VERSION ""

NS_ :

BS_:

BU_: Dummy_FO EOCM2cp_K2_FO EOCM2cp_K1_FO EOCM2cp_IMX6_FO CECM_R1_FO CMMb_FO CMMa_FO RSRR_FO LRR_FO CIPM_FO IMU2_FO IMU1_FO CGM3b_FO
VAL_TABLE_ vt_BooleanValues 1 "true" 0 "false" ;
VAL_TABLE_ StrgColCommsFlt 2 "Disabled Communications DTC" 1 "No Communications Fault" 0 "Communications Fault" ;
VAL_TABLE_ CPMAPINFO4 1 "Hardware Or Software Error" 0 "No Hardware Or Software Error" ;
VAL_TABLE_ InterLghtStat 1 "Interior Lights On" 0 "Interior Light Off" ;
VAL_TABLE_ ObstacleType 6 "NO_OBJECT" 5 "OBJ_GUARDRAIL" 4 "OBJ_TUNNEL " 3 "OBJ_TRAFFIC_SIGN" 2 "OBJ_VEHICLE" 1 "OBJ_BRIDGE " 0 "OBJ_UNKNOWN" ;
VAL_TABLE_ VpathMode 2 "Mid Hi Spped" 1 "Low Speed" 0 "Disabled" ;
VAL_TABLE_ LaneChngStatus 2 "Lane Change Right" 1 "Lane Change Left" 0 "Idle" ;
VAL_TABLE_ TravelDirection 3 "Other (excessive side slip)" 2 "reverse / stopped in rvrs gear" 1 "Forward / stopped in frwd gear" 0 "Unknown" ;
VAL_TABLE_ ModeCommand 5 "Sensing with Reduced Power" 4 "Undefined" 3 "Radio Silent" 2 "Sensing" 1 "Not Sensing" 0 "Undefined" ;
VAL_TABLE_ LaneSnsLLnPosValid 1 "Invalid" 0 "Valid" ;
VAL_TABLE_ LnSnsRLnPosValid 0 "Valid" 1 "Invalid" ;
VAL_TABLE_ Elevation 3 "Low " 2 "mid (reserved)" 1 "high " 0 "Unknown" ;
VAL_TABLE_ ModeCommandFdbk 5 "Sensing with reduced power" 4 "Undefined" 3 "Radio Silent" 2 "Sensing" 1 "Not Sensing" 0 "Undefined" ;
VAL_TABLE_ RoadTypeInfo 5 "Constiction Zone Exit" 4 "Construction Zone Entry" 3 "Highway" 2 "Secondary Road" 1 "City" 0 "Unknown" ;
VAL_TABLE_ ObjectLossInfo 2 "elevation conditions" 1 "tight curve" 0 "not lost" ;
VAL_TABLE_ MeasurementStatus 3 "Measured this cycle" 2 "Latent track not detctd this cyc" 1 "New Object" 0 "No Object" ;
VAL_TABLE_ Confidence 3 "confident" 2 "speculative" 1 "highly speculative" 0 "invalid" ;
VAL_TABLE_ DynamicProp 4 "Moving in opposite direction" 3 "Moving in same direction as host" 2 "Has moved but currently stopped" 1 "Has never moved" 0 "Unknown" ;
VAL_TABLE_ CRL_Cnfdnc 7 "Reserved4" 6 "Reserved3" 5 "Reserved2" 4 "Reserved1" 3 "Best" 2 "Marking Present" 1 "Weak Marking" 0 "No Lane" ;
VAL_TABLE_ CLL_Cnfdnc 7 "Reserved4" 6 "Reserved3" 5 "Reserved2" 4 "Reserved1" 3 "Best" 2 "Marking Present" 1 "Weak Marking" 0 "No Lane" ;
VAL_TABLE_ DrvWndPosSt 6 "Fully Opened" 5 "Open More Than C" 4 "Position C" 3 "Posistion B" 2 "Posistion A" 1 "Open Less Than A" 0 "Fully Closed" ;
VAL_TABLE_ OtsdAmbtLtLvlStat 2 "Day" 1 "Night" 0 "Unknown" ;
VAL_TABLE_ DTCI_DTCFaultType 3 "Type C" 2 "Type B" 1 "Type A" 0 "Not Supported" ;
VAL_TABLE_ VD_CoPilotSysFltStat 5 "Copilot System Failure" 4 "Partial Function Fault Detected" 3 "Redundancy Fault Detected" 2 "Environmental Interference" 1 "Operational" 0 "Unknown" ;
VAL_TABLE_ StrgAngTrqBsdEstSrfcMuConf 2 "Indeterminate" 1 "Use Data" 0 "Do Not Use Data" ;
VAL_TABLE_ SysPwrMd 3 "Crank Request" 2 "Run" 1 "Accessory" 0 "Off" ;
VAL_TABLE_ ValidityStates 1 "Invalid" 0 "Valid" ;

BO_ 1923 DTC_Triggered_783_FO: 7 RSRR_FO
 SG_ DTCI_WrnIndRqdSt_783 : 47|1@0+ (1,0) [0|1] ""  CGM3b_FO
 SG_ DTCI_TstNPsdPwrUpSt_783 : 45|1@0+ (1,0) [0|1] ""  CGM3b_FO
 SG_ DTCI_TstNPsdCdClrdSt_783 : 42|1@0+ (1,0) [0|1] ""  CGM3b_FO
 SG_ DTCI_TstFldPwrUpSt_783 : 46|1@0+ (1,0) [0|1] ""  CGM3b_FO
 SG_ DTCI_TstFldCdClrdStat_783 : 43|1@0+ (1,0) [0|1] ""  CGM3b_FO
 SG_ DTCI_HistStat_783 : 44|1@0+ (1,0) [0|1] ""  CGM3b_FO
 SG_ DTCI_DTCTriggered_783 : 0|1@0+ (1,0) [0|1] ""  CGM3b_FO
 SG_ DTCI_DTCSource_783 : 15|8@0+ (1,0) [0|255] ""  CGM3b_FO
 SG_ DTCI_DTCNumber_783 : 23|16@0+ (1,0) [0|65535] ""  CGM3b_FO
 SG_ DTCI_DTCFaultType_783 : 55|8@0+ (1,0) [0|255] ""  CGM3b_FO
 SG_ DTCI_DTCFailType_783 : 39|8@0+ (1,0) [0|255] ""  CGM3b_FO
 SG_ DTCI_CurrentStatus_783 : 41|1@0+ (1,0) [0|1] ""  CGM3b_FO
 SG_ DTCI_CodeSupported_783 : 40|1@0+ (1,0) [0|1] ""  CGM3b_FO
 SG_ DTCIUnused7_783 : 1|1@0+ (1,0) [0|1] ""  CGM3b_FO
 SG_ DTCIUnused6_783 : 2|1@0+ (1,0) [0|1] ""  CGM3b_FO
 SG_ DTCIUnused5_783 : 3|1@0+ (1,0) [0|1] ""  CGM3b_FO
 SG_ DTCIUnused4_783 : 4|1@0+ (1,0) [0|1] ""  CGM3b_FO
 SG_ DTCIUnused3_783 : 5|1@0+ (1,0) [0|1] ""  CGM3b_FO
 SG_ DTCIUnused2_783 : 6|1@0+ (1,0) [0|1] ""  CGM3b_FO
 SG_ DTCIUnused1_783 : 7|1@0+ (1,0) [0|1] ""  CGM3b_FO

BO_ 1920 DTC_Triggered_780_FO: 7 LRR_FO
 SG_ DTCI_CurrentStatus_780 : 41|1@0+ (1,0) [0|1] ""  CGM3b_FO
 SG_ DTCI_WrnIndRqdSt_780 : 47|1@0+ (1,0) [0|1] ""  CGM3b_FO
 SG_ DTCIUnused7_780 : 1|1@0+ (1,0) [0|1] ""  CGM3b_FO
 SG_ DTCIUnused6_780 : 2|1@0+ (1,0) [0|1] ""  CGM3b_FO
 SG_ DTCIUnused5_780 : 3|1@0+ (1,0) [0|1] ""  CGM3b_FO
 SG_ DTCIUnused4_780 : 4|1@0+ (1,0) [0|1] ""  CGM3b_FO
 SG_ DTCIUnused3_780 : 5|1@0+ (1,0) [0|1] ""  CGM3b_FO
 SG_ DTCIUnused2_780 : 6|1@0+ (1,0) [0|1] ""  CGM3b_FO
 SG_ DTCIUnused1_780 : 7|1@0+ (1,0) [0|1] ""  CGM3b_FO
 SG_ DTCI_TstNPsdPwrUpSt_780 : 45|1@0+ (1,0) [0|1] ""  CGM3b_FO
 SG_ DTCI_TstNPsdCdClrdSt_780 : 42|1@0+ (1,0) [0|1] ""  CGM3b_FO
 SG_ DTCI_TstFldPwrUpSt_780 : 46|1@0+ (1,0) [0|1] ""  CGM3b_FO
 SG_ DTCI_TstFldCdClrdStat_780 : 43|1@0+ (1,0) [0|1] ""  CGM3b_FO
 SG_ DTCI_HistStat_780 : 44|1@0+ (1,0) [0|1] ""  CGM3b_FO
 SG_ DTCI_DTCTriggered_780 : 0|1@0+ (1,0) [0|1] ""  CGM3b_FO
 SG_ DTCI_DTCSource_780 : 15|8@0+ (1,0) [0|255] ""  CGM3b_FO
 SG_ DTCI_DTCNumber_780 : 23|16@0+ (1,0) [0|65535] ""  CGM3b_FO
 SG_ DTCI_DTCFaultType_780 : 55|8@0+ (1,0) [0|255] ""  CGM3b_FO
 SG_ DTCI_DTCFailType_780 : 39|8@0+ (1,0) [0|255] ""  CGM3b_FO
 SG_ DTCI_CodeSupported_780 : 40|1@0+ (1,0) [0|1] ""  CGM3b_FO

BO_ 1789 AL_Test_Tool_Req_RSRR: 8 Dummy_FO
 SG_ RSRREngCmdDta : 7|64@0+ (1,0) [0|1.84467440737096E+019] ""  CGM3b_FO,RSRR_FO

BO_ 1786 AL_Test_Tool_Rsp_RSRR: 8 RSRR_FO
 SG_ RSRREngRspDta : 7|64@0+ (1,0) [0|1.84467440737096E+019] ""  CGM3b_FO

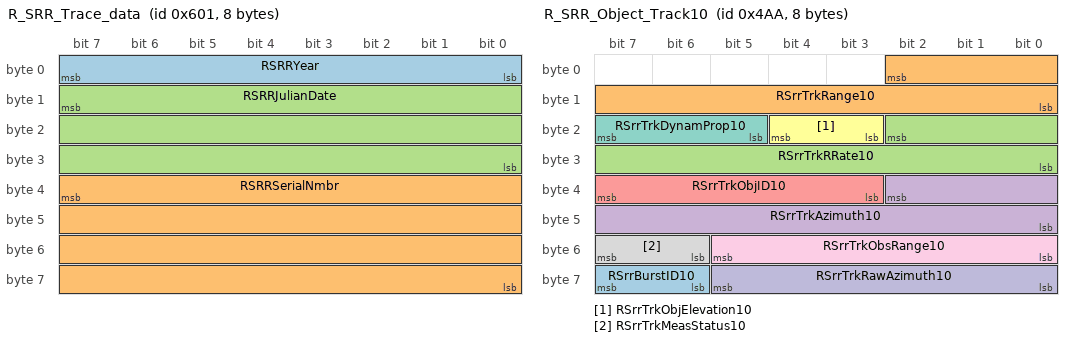
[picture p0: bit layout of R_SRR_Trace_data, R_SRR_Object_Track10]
BO_ 1537 R_SRR_Trace_data: 8 RSRR_FO
 SG_ RSRRYear : 7|8@0+ (1,0) [0|0] ""  CGM3b_FO
 SG_ RSRRSerialNmbr : 39|32@0+ (1,0) [0|0] ""  CGM3b_FO
 SG_ RSRRJulianDate : 15|24@0+ (1,0) [0|0] ""  CGM3b_FO

BO_ 1194 R_SRR_Object_Track10: 8 RSRR_FO
 SG_ RSrrBurstID10 : 63|2@0+ (1,0) [0|3] ""  CGM3b_FO
 SG_ RSrrTrkRange10 : 2|11@0+ (0.02,0) [0|40.94] "m"  CGM3b_FO
 SG_ RSrrTrkRRate10 : 18|11@0- (0.125,0) [-128|127.875] "m/s"  CGM3b_FO
 SG_ RSrrTrkAzimuth10 : 34|11@0- (0.125,0) [-128|127.875] "deg"  CGM3b_FO
 SG_ RSrrTrkObjID10 : 39|5@0+ (1,0) [0|31] ""  CGM3b_FO
 SG_ RSrrTrkObjElevation10 : 20|2@0+ (1,0) [0|3] ""  CGM3b_FO
 SG_ RSrrTrkDynamProp10 : 23|3@0+ (1,0) [0|7] ""  CGM3b_FO
 SG_ RSrrTrkMeasStatus10 : 55|2@0+ (1,0) [0|3] ""  CGM3b_FO
 SG_ RSrrTrkObsRange10 : 53|6@0- (0.02,0) [-0.64|0.62] "m"  CGM3b_FO
 SG_ RSrrTrkRawAzimuth10 : 61|6@0- (1,0) [-32|31] "deg"  CGM3b_FO

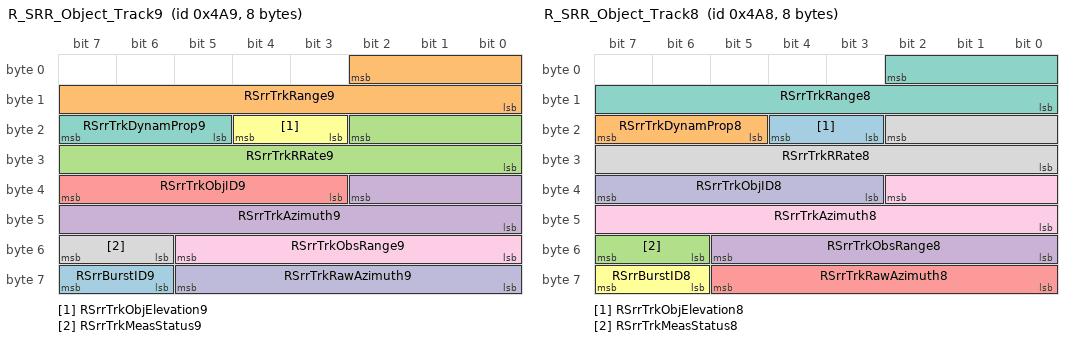
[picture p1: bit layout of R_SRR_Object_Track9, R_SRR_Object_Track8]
BO_ 1193 R_SRR_Object_Track9: 8 RSRR_FO
 SG_ RSrrBurstID9 : 63|2@0+ (1,0) [0|3] ""  CGM3b_FO
 SG_ RSrrTrkRange9 : 2|11@0+ (0.02,0) [0|40.94] "m"  CGM3b_FO
 SG_ RSrrTrkRRate9 : 18|11@0- (0.125,0) [-128|127.875] "m/s"  CGM3b_FO
 SG_ RSrrTrkAzimuth9 : 34|11@0- (0.125,0) [-128|127.875] "deg"  CGM3b_FO
 SG_ RSrrTrkObjID9 : 39|5@0+ (1,0) [0|31] ""  CGM3b_FO
 SG_ RSrrTrkObjElevation9 : 20|2@0+ (1,0) [0|3] ""  CGM3b_FO
 SG_ RSrrTrkDynamProp9 : 23|3@0+ (1,0) [0|7] ""  CGM3b_FO
 SG_ RSrrTrkMeasStatus9 : 55|2@0+ (1,0) [0|3] ""  CGM3b_FO
 SG_ RSrrTrkObsRange9 : 53|6@0- (0.02,0) [-0.64|0.62] "m"  CGM3b_FO
 SG_ RSrrTrkRawAzimuth9 : 61|6@0- (1,0) [-32|31] "deg"  CGM3b_FO

BO_ 1192 R_SRR_Object_Track8: 8 RSRR_FO
 SG_ RSrrTrkObjElevation8 : 20|2@0+ (1,0) [0|3] ""  CGM3b_FO
 SG_ RSrrTrkDynamProp8 : 23|3@0+ (1,0) [0|7] ""  CGM3b_FO
 SG_ RSrrTrkMeasStatus8 : 55|2@0+ (1,0) [0|3] ""  CGM3b_FO
 SG_ RSrrTrkObsRange8 : 53|6@0- (0.02,0) [-0.64|0.62] "m"  CGM3b_FO
 SG_ RSrrTrkRawAzimuth8 : 61|6@0- (1,0) [-32|31] "deg"  CGM3b_FO
 SG_ RSrrBurstID8 : 63|2@0+ (1,0) [0|3] ""  CGM3b_FO
 SG_ RSrrTrkRange8 : 2|11@0+ (0.02,0) [0|40.94] "m"  CGM3b_FO
 SG_ RSrrTrkRRate8 : 18|11@0- (0.125,0) [-128|127.875] "m/s"  CGM3b_FO
 SG_ RSrrTrkAzimuth8 : 34|11@0- (0.125,0) [-128|127.875] "deg"  CGM3b_FO
 SG_ RSrrTrkObjID8 : 39|5@0+ (1,0) [0|31] ""  CGM3b_FO

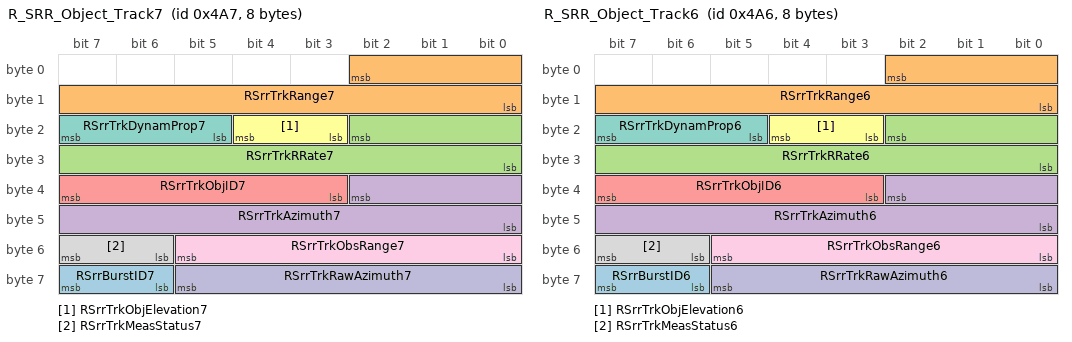
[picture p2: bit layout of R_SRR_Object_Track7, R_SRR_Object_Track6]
BO_ 1191 R_SRR_Object_Track7: 8 RSRR_FO
 SG_ RSrrBurstID7 : 63|2@0+ (1,0) [0|3] ""  CGM3b_FO
 SG_ RSrrTrkRange7 : 2|11@0+ (0.02,0) [0|40.94] "m"  CGM3b_FO
 SG_ RSrrTrkRRate7 : 18|11@0- (0.125,0) [-128|127.875] "m/s"  CGM3b_FO
 SG_ RSrrTrkAzimuth7 : 34|11@0- (0.125,0) [-128|127.875] "deg"  CGM3b_FO
 SG_ RSrrTrkObjID7 : 39|5@0+ (1,0) [0|31] ""  CGM3b_FO
 SG_ RSrrTrkObjElevation7 : 20|2@0+ (1,0) [0|3] ""  CGM3b_FO
 SG_ RSrrTrkDynamProp7 : 23|3@0+ (1,0) [0|7] ""  CGM3b_FO
 SG_ RSrrTrkMeasStatus7 : 55|2@0+ (1,0) [0|3] ""  CGM3b_FO
 SG_ RSrrTrkObsRange7 : 53|6@0- (0.02,0) [-0.64|0.62] "m"  CGM3b_FO
 SG_ RSrrTrkRawAzimuth7 : 61|6@0- (1,0) [-32|31] "deg"  CGM3b_FO

BO_ 1190 R_SRR_Object_Track6: 8 RSRR_FO
 SG_ RSrrBurstID6 : 63|2@0+ (1,0) [0|3] ""  CGM3b_FO
 SG_ RSrrTrkRange6 : 2|11@0+ (0.02,0) [0|40.94] "m"  CGM3b_FO
 SG_ RSrrTrkRRate6 : 18|11@0- (0.125,0) [-128|127.875] "m/s"  CGM3b_FO
 SG_ RSrrTrkAzimuth6 : 34|11@0- (0.125,0) [-128|127.875] "deg"  CGM3b_FO
 SG_ RSrrTrkObjID6 : 39|5@0+ (1,0) [0|31] ""  CGM3b_FO
 SG_ RSrrTrkObjElevation6 : 20|2@0+ (1,0) [0|3] ""  CGM3b_FO
 SG_ RSrrTrkDynamProp6 : 23|3@0+ (1,0) [0|7] ""  CGM3b_FO
 SG_ RSrrTrkMeasStatus6 : 55|2@0+ (1,0) [0|3] ""  CGM3b_FO
 SG_ RSrrTrkObsRange6 : 53|6@0- (0.02,0) [-0.64|0.62] "m"  CGM3b_FO
 SG_ RSrrTrkRawAzimuth6 : 61|6@0- (1,0) [-32|31] "deg"  CGM3b_FO

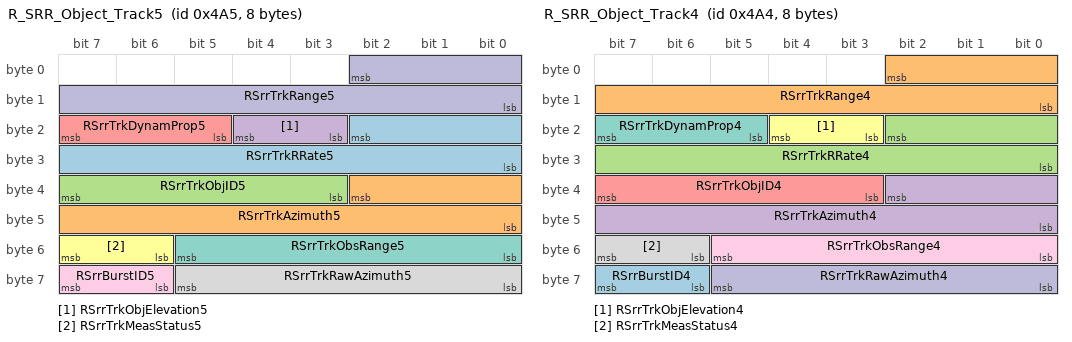
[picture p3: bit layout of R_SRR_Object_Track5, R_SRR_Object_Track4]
BO_ 1189 R_SRR_Object_Track5: 8 RSRR_FO
 SG_ RSrrTrkRRate5 : 18|11@0- (0.125,0) [-128|127.875] "m/s"  CGM3b_FO
 SG_ RSrrTrkAzimuth5 : 34|11@0- (0.125,0) [-128|127.875] "deg"  CGM3b_FO
 SG_ RSrrTrkObjID5 : 39|5@0+ (1,0) [0|31] ""  CGM3b_FO
 SG_ RSrrTrkObjElevation5 : 20|2@0+ (1,0) [0|3] ""  CGM3b_FO
 SG_ RSrrTrkDynamProp5 : 23|3@0+ (1,0) [0|7] ""  CGM3b_FO
 SG_ RSrrTrkMeasStatus5 : 55|2@0+ (1,0) [0|3] ""  CGM3b_FO
 SG_ RSrrTrkObsRange5 : 53|6@0- (0.02,0) [-0.64|0.62] "m"  CGM3b_FO
 SG_ RSrrTrkRawAzimuth5 : 61|6@0- (1,0) [-32|31] "deg"  CGM3b_FO
 SG_ RSrrBurstID5 : 63|2@0+ (1,0) [0|3] ""  CGM3b_FO
 SG_ RSrrTrkRange5 : 2|11@0+ (0.02,0) [0|40.94] "m"  CGM3b_FO

BO_ 1188 R_SRR_Object_Track4: 8 RSRR_FO
 SG_ RSrrBurstID4 : 63|2@0+ (1,0) [0|3] ""  CGM3b_FO
 SG_ RSrrTrkRange4 : 2|11@0+ (0.02,0) [0|40.94] "m"  CGM3b_FO
 SG_ RSrrTrkRRate4 : 18|11@0- (0.125,0) [-128|127.875] "m/s"  CGM3b_FO
 SG_ RSrrTrkAzimuth4 : 34|11@0- (0.125,0) [-128|127.875] "deg"  CGM3b_FO
 SG_ RSrrTrkObjID4 : 39|5@0+ (1,0) [0|31] ""  CGM3b_FO
 SG_ RSrrTrkObjElevation4 : 20|2@0+ (1,0) [0|3] ""  CGM3b_FO
 SG_ RSrrTrkDynamProp4 : 23|3@0+ (1,0) [0|7] ""  CGM3b_FO
 SG_ RSrrTrkMeasStatus4 : 55|2@0+ (1,0) [0|3] ""  CGM3b_FO
 SG_ RSrrTrkObsRange4 : 53|6@0- (0.02,0) [-0.64|0.62] "m"  CGM3b_FO
 SG_ RSrrTrkRawAzimuth4 : 61|6@0- (1,0) [-32|31] "deg"  CGM3b_FO

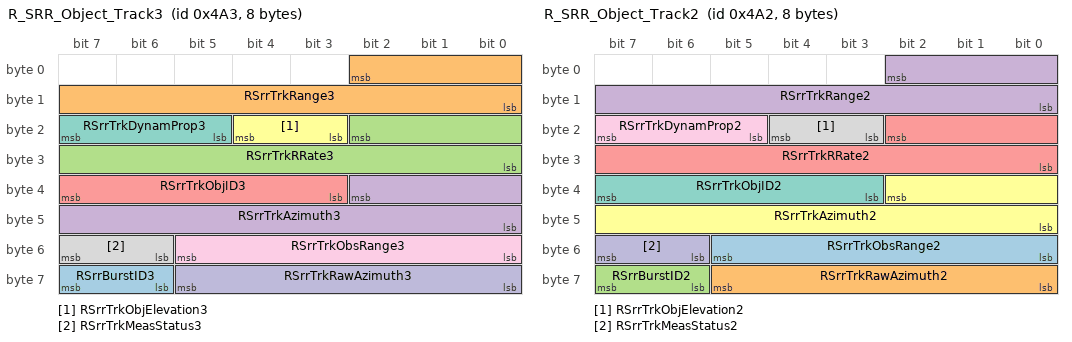
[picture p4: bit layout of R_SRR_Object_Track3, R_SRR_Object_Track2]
BO_ 1187 R_SRR_Object_Track3: 8 RSRR_FO
 SG_ RSrrBurstID3 : 63|2@0+ (1,0) [0|3] ""  CGM3b_FO
 SG_ RSrrTrkRange3 : 2|11@0+ (0.02,0) [0|40.94] "m"  CGM3b_FO
 SG_ RSrrTrkRRate3 : 18|11@0- (0.125,0) [-128|127.875] "m/s"  CGM3b_FO
 SG_ RSrrTrkAzimuth3 : 34|11@0- (0.125,0) [-128|127.875] "deg"  CGM3b_FO
 SG_ RSrrTrkObjID3 : 39|5@0+ (1,0) [0|31] ""  CGM3b_FO
 SG_ RSrrTrkObjElevation3 : 20|2@0+ (1,0) [0|3] ""  CGM3b_FO
 SG_ RSrrTrkDynamProp3 : 23|3@0+ (1,0) [0|7] ""  CGM3b_FO
 SG_ RSrrTrkMeasStatus3 : 55|2@0+ (1,0) [0|3] ""  CGM3b_FO
 SG_ RSrrTrkObsRange3 : 53|6@0- (0.02,0) [-0.64|0.62] "m"  CGM3b_FO
 SG_ RSrrTrkRawAzimuth3 : 61|6@0- (1,0) [-32|31] "deg"  CGM3b_FO

BO_ 1186 R_SRR_Object_Track2: 8 RSRR_FO
 SG_ RSrrTrkObsRange2 : 53|6@0- (0.02,0) [-0.64|0.62] "m"  CGM3b_FO
 SG_ RSrrTrkRawAzimuth2 : 61|6@0- (1,0) [-32|31] "deg"  CGM3b_FO
 SG_ RSrrBurstID2 : 63|2@0+ (1,0) [0|3] ""  CGM3b_FO
 SG_ RSrrTrkRange2 : 2|11@0+ (0.02,0) [0|40.94] "m"  CGM3b_FO
 SG_ RSrrTrkRRate2 : 18|11@0- (0.125,0) [-128|127.875] "m/s"  CGM3b_FO
 SG_ RSrrTrkAzimuth2 : 34|11@0- (0.125,0) [-128|127.875] "deg"  CGM3b_FO
 SG_ RSrrTrkObjID2 : 39|5@0+ (1,0) [0|31] ""  CGM3b_FO
 SG_ RSrrTrkObjElevation2 : 20|2@0+ (1,0) [0|3] ""  CGM3b_FO
 SG_ RSrrTrkDynamProp2 : 23|3@0+ (1,0) [0|7] ""  CGM3b_FO
 SG_ RSrrTrkMeasStatus2 : 55|2@0+ (1,0) [0|3] ""  CGM3b_FO

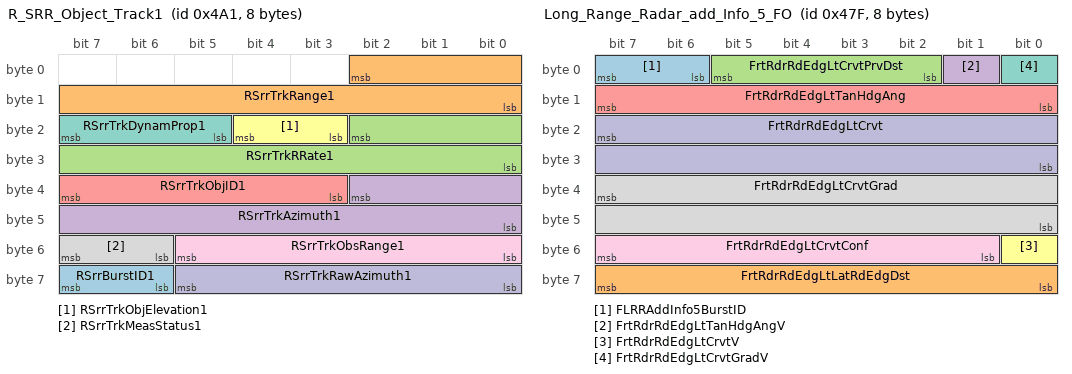
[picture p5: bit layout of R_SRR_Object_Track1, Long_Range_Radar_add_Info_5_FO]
BO_ 1185 R_SRR_Object_Track1: 8 RSRR_FO
 SG_ RSrrBurstID1 : 63|2@0+ (1,0) [0|3] ""  CGM3b_FO
 SG_ RSrrTrkRange1 : 2|11@0+ (0.02,0) [0|40.94] "m"  CGM3b_FO
 SG_ RSrrTrkRRate1 : 18|11@0- (0.125,0) [-128|127.875] "m/s"  CGM3b_FO
 SG_ RSrrTrkAzimuth1 : 34|11@0- (0.125,0) [-128|127.875] "deg"  CGM3b_FO
 SG_ RSrrTrkObjID1 : 39|5@0+ (1,0) [0|31] ""  CGM3b_FO
 SG_ RSrrTrkObjElevation1 : 20|2@0+ (1,0) [0|3] ""  CGM3b_FO
 SG_ RSrrTrkDynamProp1 : 23|3@0+ (1,0) [0|7] ""  CGM3b_FO
 SG_ RSrrTrkMeasStatus1 : 55|2@0+ (1,0) [0|3] ""  CGM3b_FO
 SG_ RSrrTrkObsRange1 : 53|6@0- (0.02,0) [-0.64|0.62] "m"  CGM3b_FO
 SG_ RSrrTrkRawAzimuth1 : 61|6@0- (1,0) [-32|31] "deg"  CGM3b_FO

BO_ 1184 R_SRR_Object_Header: 8 RSRR_FO
 SG_ RSRRSnstvFltPrsntInt : 24|1@0+ (1,0) [0|1] ""  CGM3b_FO
 SG_ RSRRPlntAlgnInProc : 37|1@0+ (1,0) [0|1] ""  CGM3b_FO
 SG_ RSRRMsalgnYawRt : 47|1@0+ (1,0) [0|1] ""  CGM3b_FO
 SG_ RSRRMsalgnYawLt : 46|1@0+ (1,0) [0|1] ""  CGM3b_FO
 SG_ RSRRMsalgnRllRt : 35|1@0+ (1,0) [0|1] ""  CGM3b_FO
 SG_ RSRRMsalgnRllLt : 34|1@0+ (1,0) [0|1] ""  CGM3b_FO
 SG_ RSRRMsalgnPtchUp : 32|1@0+ (1,0) [0|1] ""  CGM3b_FO
 SG_ RSRRMsalgnPtchDn : 33|1@0+ (1,0) [0|1] ""  CGM3b_FO
 SG_ RSRRInitDiagCmplt : 40|1@0+ (1,0) [0|1] ""  CGM3b_FO
 SG_ RSRRHWFltPrsntInt : 25|1@0+ (1,0) [0|1] ""  CGM3b_FO
 SG_ RSRRExtIntrfrnc : 36|1@0+ (1,0) [0|1] ""  CGM3b_FO
 SG_ RSRRDiagSpare : 30|1@0+ (1,0) [0|1] ""  CGM3b_FO
 SG_ RSRRCANSgnlSpvFld : 29|1@0+ (1,0) [0|1] ""  CGM3b_FO
 SG_ RSRRCANRxErr : 28|1@0+ (1,0) [0|1] ""  CGM3b_FO
 SG_ RSRRCANIDAddrsUnsbl : 27|1@0+ (1,0) [0|1] ""  CGM3b_FO
 SG_ RSRRAntTngFltPrsnt : 26|1@0+ (1,0) [0|1] ""  CGM3b_FO
 SG_ RSRRAmbTmpOutRngLw : 42|1@0+ (1,0) [0|1] ""  CGM3b_FO
 SG_ RSRRAmbTmpOutRngHi : 41|1@0+ (1,0) [0|1] ""  CGM3b_FO
 SG_ RSRRAlgnFltPrsnt : 39|1@0+ (1,0) [0|1] ""  CGM3b_FO
 SG_ RSRRVltgOutRngLo : 44|1@0+ (1,0) [0|1] ""  CGM3b_FO
 SG_ RSRRVltgOutRngHi : 43|1@0+ (1,0) [0|1] ""  CGM3b_FO
 SG_ RSRRSvcAlgnInPrcs : 38|1@0+ (1,0) [0|1] ""  CGM3b_FO
 SG_ RSRRSnsrBlckd : 45|1@0+ (1,0) [0|1] ""  CGM3b_FO
 SG_ RSRRNumValidTargets : 14|4@0+ (1,0) [0|15] ""  CGM3b_FO
 SG_ RSrrRollingCnt : 1|2@0+ (1,0) [0|3] ""  CGM3b_FO
 SG_ RSRRModeCmdFdbk : 4|3@0+ (1,0) [0|7] ""  CGM3b_FO
 SG_ RSrrTimeStampV : 15|1@0+ (1,0) [0|1] ""  CGM3b_FO
 SG_ RSrrTimeStamp : 10|11@0+ (1,0) [0|2047] "ms"  CGM3b_FO
 SG_ RSrrBurstChecksum : 55|16@0+ (1,0) [0|65535] ""  CGM3b_FO

BO_ 1151 Long_Range_Radar_add_Info_5_FO: 8 LRR_FO
 SG_ FLRRAddInfo5BurstID : 7|2@0+ (1,0) [0|3] ""  CGM3b_FO
 SG_ FrtRdrRdEdgLtLatRdEdgDst : 63|8@0- (0.1,0) [-12.8|12.7] "m/m"  CGM3b_FO
 SG_ FrtRdrRdEdgLtCrvtPrvDst : 5|4@0+ (10,0) [0|150] ""  CGM3b_FO
 SG_ FrtRdrRdEdgLtTanHdgAngV : 1|1@0+ (1,0) [0|1] ""  CGM3b_FO
 SG_ FrtRdrRdEdgLtTanHdgAng : 15|8@0- (0.002,0) [-0.256|0.254] "m/m"  CGM3b_FO
 SG_ FrtRdrRdEdgLtCrvtV : 48|1@0+ (1,0) [0|1] ""  CGM3b_FO
 SG_ FrtRdrRdEdgLtCrvtGradV : 0|1@0+ (1,0) [0|1] ""  CGM3b_FO
 SG_ FrtRdrRdEdgLtCrvtGrad : 39|16@0- (5.96E-008,0) [-0.0019529728|0.0019529132] "1/(m*sec)"  CGM3b_FO
 SG_ FrtRdrRdEdgLtCrvtConf : 55|7@0+ (0.7874016,0) [0|100.0000032] "%"  CGM3b_FO
 SG_ FrtRdrRdEdgLtCrvt : 23|16@0- (9.53E-007,0) [-0.031227904|0.031226951] "1/m"  CGM3b_FO

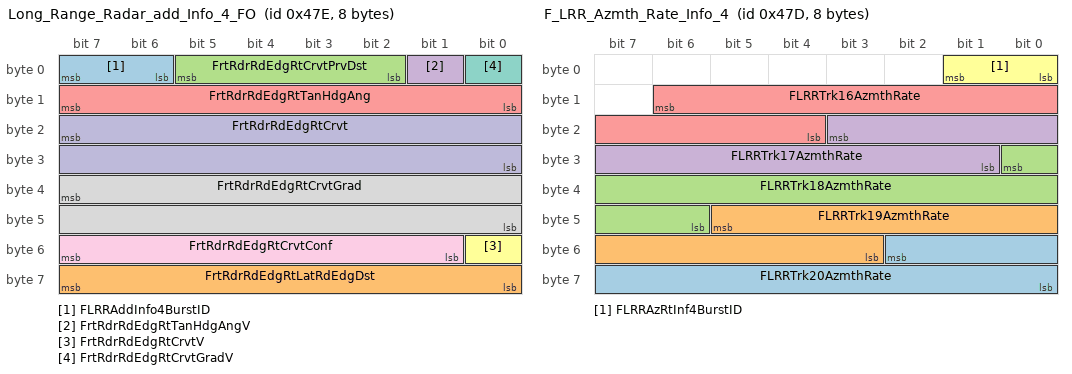
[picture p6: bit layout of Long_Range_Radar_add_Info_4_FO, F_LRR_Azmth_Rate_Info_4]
BO_ 1150 Long_Range_Radar_add_Info_4_FO: 8 LRR_FO
 SG_ FLRRAddInfo4BurstID : 7|2@0+ (1,0) [0|3] ""  CGM3b_FO
 SG_ FrtRdrRdEdgRtLatRdEdgDst : 63|8@0- (0.1,0) [-12.8|12.7] "m/m"  CGM3b_FO
 SG_ FrtRdrRdEdgRtCrvtPrvDst : 5|4@0+ (10,0) [0|150] ""  CGM3b_FO
 SG_ FrtRdrRdEdgRtTanHdgAngV : 1|1@0+ (1,0) [0|1] ""  CGM3b_FO
 SG_ FrtRdrRdEdgRtTanHdgAng : 15|8@0- (0.002,0) [-0.256|0.254] "m/m"  CGM3b_FO
 SG_ FrtRdrRdEdgRtCrvtV : 48|1@0+ (1,0) [0|1] ""  CGM3b_FO
 SG_ FrtRdrRdEdgRtCrvtGradV : 0|1@0+ (1,0) [0|1] ""  CGM3b_FO
 SG_ FrtRdrRdEdgRtCrvtGrad : 39|16@0- (5.96E-008,0) [-0.0019529728|0.0019529132] "1/(m*sec)"  CGM3b_FO
 SG_ FrtRdrRdEdgRtCrvtConf : 55|7@0+ (0.7874016,0) [0|100.0000032] "%"  CGM3b_FO
 SG_ FrtRdrRdEdgRtCrvt : 23|16@0- (9.53E-007,0) [-0.031227904|0.031226951] "1/m"  CGM3b_FO

BO_ 1149 F_LRR_Azmth_Rate_Info_4: 8 LRR_FO
 SG_ FLRRTrk20AzmthRate : 50|11@0- (0.125,0) [-128|127.875] "deg/s"  CGM3b_FO
 SG_ FLRRTrk19AzmthRate : 45|11@0- (0.125,0) [-128|127.875] "deg/s"  CGM3b_FO
 SG_ FLRRTrk18AzmthRate : 24|11@0- (0.125,0) [-128|127.875] "deg/s"  CGM3b_FO
 SG_ FLRRTrk17AzmthRate : 19|11@0- (0.125,0) [-128|127.875] "deg/s"  CGM3b_FO
 SG_ FLRRTrk16AzmthRate : 14|11@0- (0.125,0) [-128|127.875] "deg/s"  CGM3b_FO
 SG_ FLRRAzRtInf4BurstID : 1|2@0+ (1,0) [0|3] ""  CGM3b_FO

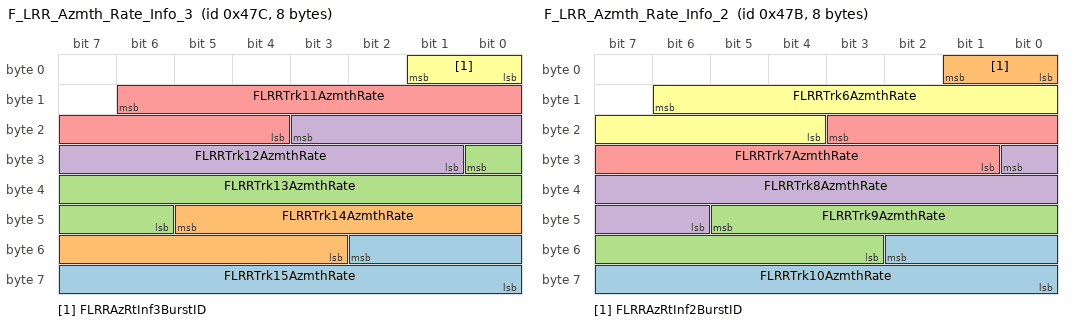
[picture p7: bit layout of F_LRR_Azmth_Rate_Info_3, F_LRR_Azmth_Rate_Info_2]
BO_ 1148 F_LRR_Azmth_Rate_Info_3: 8 LRR_FO
 SG_ FLRRTrk15AzmthRate : 50|11@0- (0.125,0) [-128|127.875] "deg/s"  CGM3b_FO
 SG_ FLRRTrk14AzmthRate : 45|11@0- (0.125,0) [-128|127.875] "deg/s"  CGM3b_FO
 SG_ FLRRTrk13AzmthRate : 24|11@0- (0.125,0) [-128|127.875] "deg/s"  CGM3b_FO
 SG_ FLRRTrk12AzmthRate : 19|11@0- (0.125,0) [-128|127.875] "deg/s"  CGM3b_FO
 SG_ FLRRTrk11AzmthRate : 14|11@0- (0.125,0) [-128|127.875] "deg/s"  CGM3b_FO
 SG_ FLRRAzRtInf3BurstID : 1|2@0+ (1,0) [0|3] ""  CGM3b_FO

BO_ 1147 F_LRR_Azmth_Rate_Info_2: 8 LRR_FO
 SG_ FLRRTrk10AzmthRate : 50|11@0- (0.125,0) [-128|127.875] "deg/s"  CGM3b_FO
 SG_ FLRRAzRtInf2BurstID : 1|2@0+ (1,0) [0|3] ""  CGM3b_FO
 SG_ FLRRTrk9AzmthRate : 45|11@0- (0.125,0) [-128|127.875] "deg/s"  CGM3b_FO
 SG_ FLRRTrk8AzmthRate : 24|11@0- (0.125,0) [-128|127.875] "deg/s"  CGM3b_FO
 SG_ FLRRTrk7AzmthRate : 19|11@0- (0.125,0) [-128|127.875] "deg/s"  CGM3b_FO
 SG_ FLRRTrk6AzmthRate : 14|11@0- (0.125,0) [-128|127.875] "deg/s"  CGM3b_FO

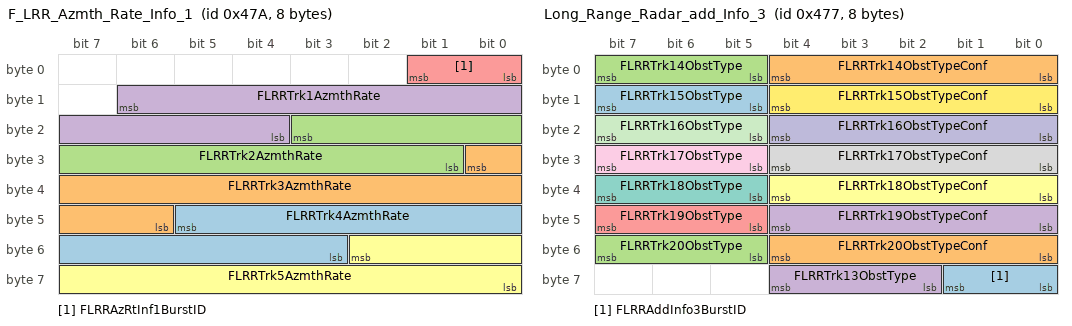
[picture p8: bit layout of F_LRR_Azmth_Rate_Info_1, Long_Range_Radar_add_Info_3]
BO_ 1146 F_LRR_Azmth_Rate_Info_1: 8 LRR_FO
 SG_ FLRRTrk4AzmthRate : 45|11@0- (0.125,0) [-128|127.875] "deg/s"  CGM3b_FO
 SG_ FLRRTrk3AzmthRate : 24|11@0- (0.125,0) [-128|127.875] "deg/s"  CGM3b_FO
 SG_ FLRRTrk2AzmthRate : 19|11@0- (0.125,0) [-128|127.875] "deg/s"  CGM3b_FO
 SG_ FLRRTrk1AzmthRate : 14|11@0- (0.125,0) [-128|127.875] "deg/s"  CGM3b_FO
 SG_ FLRRAzRtInf1BurstID : 1|2@0+ (1,0) [0|3] ""  CGM3b_FO
 SG_ FLRRTrk5AzmthRate : 50|11@0- (0.125,0) [-128|127.875] "deg/s"  CGM3b_FO

BO_ 1143 Long_Range_Radar_add_Info_3: 8 LRR_FO
 SG_ FLRRAddInfo3BurstID : 57|2@0+ (1,0) [0|3] ""  CGM3b_FO
 SG_ FLRRTrk20ObstTypeConf : 52|5@0+ (0.0323,0) [0|1.0013] ""  CGM3b_FO
 SG_ FLRRTrk20ObstType : 55|3@0+ (1,0) [0|7] ""  CGM3b_FO
 SG_ FLRRTrk19ObstTypeConf : 44|5@0+ (0.0323,0) [0|1.0013] ""  CGM3b_FO
 SG_ FLRRTrk19ObstType : 47|3@0+ (1,0) [0|7] ""  CGM3b_FO
 SG_ FLRRTrk18ObstTypeConf : 36|5@0+ (0.0323,0) [0|1.0013] ""  CGM3b_FO
 SG_ FLRRTrk18ObstType : 39|3@0+ (1,0) [0|7] ""  CGM3b_FO
 SG_ FLRRTrk17ObstTypeConf : 28|5@0+ (0.0323,0) [0|1.0013] ""  CGM3b_FO
 SG_ FLRRTrk17ObstType : 31|3@0+ (1,0) [0|7] ""  CGM3b_FO
 SG_ FLRRTrk16ObstTypeConf : 20|5@0+ (0.0323,0) [0|1.0013] ""  CGM3b_FO
 SG_ FLRRTrk16ObstType : 23|3@0+ (1,0) [0|7] ""  CGM3b_FO
 SG_ FLRRTrk15ObstTypeConf : 12|5@0+ (0.0323,0) [0|1.0013] ""  CGM3b_FO
 SG_ FLRRTrk15ObstType : 15|3@0+ (1,0) [0|7] ""  CGM3b_FO
 SG_ FLRRTrk14ObstTypeConf : 4|5@0+ (0.0323,0) [0|1.0013] ""  CGM3b_FO
 SG_ FLRRTrk14ObstType : 7|3@0+ (1,0) [0|7] ""  CGM3b_FO
 SG_ FLRRTrk13ObstType : 60|3@0+ (1,0) [0|7] ""  CGM3b_FO

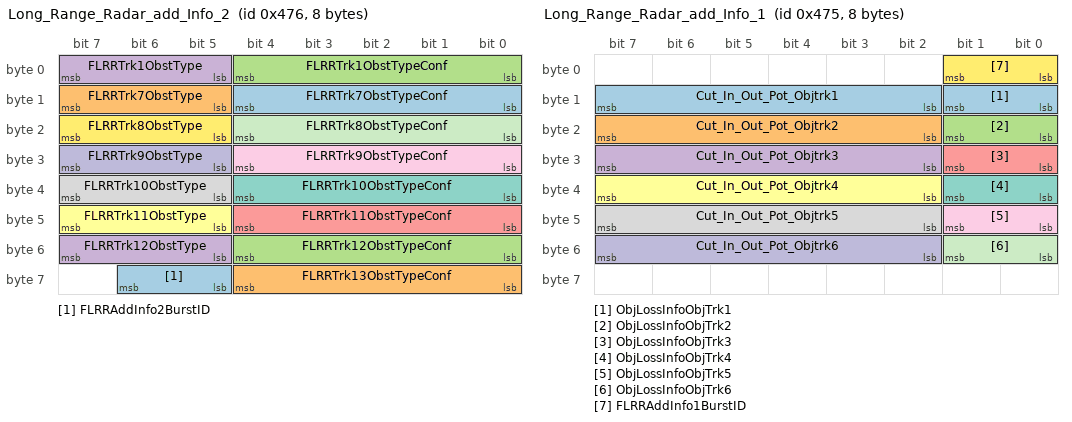
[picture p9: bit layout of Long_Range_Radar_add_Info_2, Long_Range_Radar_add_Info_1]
BO_ 1142 Long_Range_Radar_add_Info_2: 8 LRR_FO
 SG_ FLRRAddInfo2BurstID : 62|2@0+ (1,0) [0|3] ""  CGM3b_FO
 SG_ FLRRTrk13ObstTypeConf : 60|5@0+ (0.0323,0) [0|1.0013] ""  CGM3b_FO
 SG_ FLRRTrk12ObstTypeConf : 52|5@0+ (0.0323,0) [0|1.0013] ""  CGM3b_FO
 SG_ FLRRTrk12ObstType : 55|3@0+ (1,0) [0|7] ""  CGM3b_FO
 SG_ FLRRTrk11ObstTypeConf : 44|5@0+ (0.0323,0) [0|1.0013] ""  CGM3b_FO
 SG_ FLRRTrk11ObstType : 47|3@0+ (1,0) [0|7] ""  CGM3b_FO
 SG_ FLRRTrk10ObstTypeConf : 36|5@0+ (0.0323,0) [0|1.0013] ""  CGM3b_FO
 SG_ FLRRTrk10ObstType : 39|3@0+ (1,0) [0|7] ""  CGM3b_FO
 SG_ FLRRTrk9ObstTypeConf : 28|5@0+ (0.0323,0) [0|1.0013] ""  CGM3b_FO
 SG_ FLRRTrk9ObstType : 31|3@0+ (1,0) [0|7] ""  CGM3b_FO
 SG_ FLRRTrk8ObstTypeConf : 20|5@0+ (0.0323,0) [0|1.0013] ""  CGM3b_FO
 SG_ FLRRTrk8ObstType : 23|3@0+ (1,0) [0|7] ""  CGM3b_FO
 SG_ FLRRTrk7ObstTypeConf : 12|5@0+ (0.0323,0) [0|1.0013] ""  CGM3b_FO
 SG_ FLRRTrk7ObstType : 15|3@0+ (1,0) [0|7] ""  CGM3b_FO
 SG_ FLRRTrk1ObstTypeConf : 4|5@0+ (0.0323,0) [0|1.0013] ""  CGM3b_FO
 SG_ FLRRTrk1ObstType : 7|3@0+ (1,0) [0|7] ""  CGM3b_FO

BO_ 1141 Long_Range_Radar_add_Info_1: 8 LRR_FO
 SG_ ObjLossInfoObjTrk1 : 9|2@0+ (1,0) [0|3] ""  CGM3b_FO
 SG_ Cut_In_Out_Pot_Objtrk2 : 23|6@0+ (0.02,0) [0|1.26] ""  CGM3b_FO
 SG_ ObjLossInfoObjTrk2 : 17|2@0+ (1,0) [0|3] ""  CGM3b_FO
 SG_ Cut_In_Out_Pot_Objtrk3 : 31|6@0+ (0.02,0) [0|1.26] ""  CGM3b_FO
 SG_ ObjLossInfoObjTrk3 : 25|2@0+ (1,0) [0|3] ""  CGM3b_FO
 SG_ Cut_In_Out_Pot_Objtrk4 : 39|6@0+ (0.02,0) [0|1.26] ""  CGM3b_FO
 SG_ ObjLossInfoObjTrk4 : 33|2@0+ (1,0) [0|3] ""  CGM3b_FO
 SG_ Cut_In_Out_Pot_Objtrk5 : 47|6@0+ (0.02,0) [0|1.26] ""  CGM3b_FO
 SG_ ObjLossInfoObjTrk5 : 41|2@0+ (1,0) [0|3] ""  CGM3b_FO
 SG_ Cut_In_Out_Pot_Objtrk6 : 55|6@0+ (0.02,0) [0|1.26] ""  CGM3b_FO
 SG_ ObjLossInfoObjTrk6 : 49|2@0+ (1,0) [0|3] ""  CGM3b_FO
 SG_ FLRRAddInfo1BurstID : 1|2@0+ (1,0) [0|3] ""  CGM3b_FO
 SG_ Cut_In_Out_Pot_Objtrk1 : 15|6@0+ (0.02,0) [0|1.26] ""  CGM3b_FO

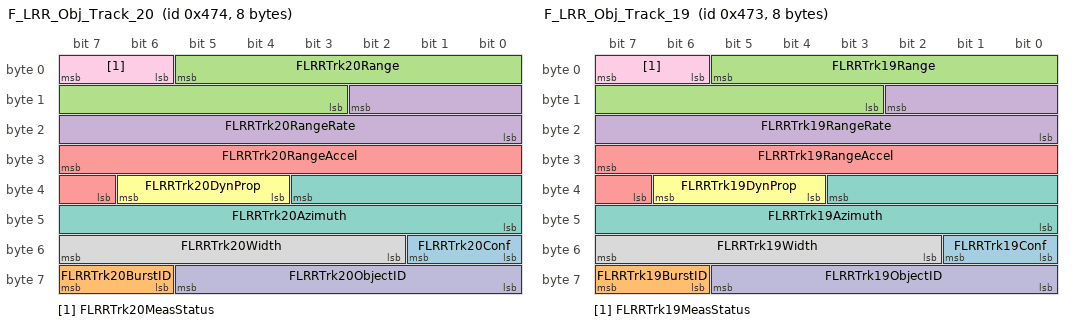
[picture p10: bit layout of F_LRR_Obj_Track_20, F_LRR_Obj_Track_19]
BO_ 1140 F_LRR_Obj_Track_20: 8 LRR_FO
 SG_ FLRRTrk20Conf : 49|2@0+ (1,0) [0|3] ""  CGM3b_FO
 SG_ FLRRTrk20BurstID : 63|2@0+ (1,0) [0|3] ""  CGM3b_FO
 SG_ FLRRTrk20Range : 5|11@0+ (0.125,0) [0|255.875] "m"  CGM3b_FO
 SG_ FLRRTrk20RangeRate : 10|11@0- (0.125,0) [-128|127.875] "m/s"  CGM3b_FO
 SG_ FLRRTrk20RangeAccel : 31|9@0- (0.125,0) [-32|31.875] "m/s^2"  CGM3b_FO
 SG_ FLRRTrk20DynProp : 38|3@0+ (1,0) [0|7] ""  CGM3b_FO
 SG_ FLRRTrk20Azimuth : 35|12@0- (0.125,0) [-256|255.875] "deg"  CGM3b_FO
 SG_ FLRRTrk20Width : 55|6@0+ (0.25,0) [0|15.75] "m"  CGM3b_FO
 SG_ FLRRTrk20MeasStatus : 7|2@0+ (1,0) [0|3] ""  CGM3b_FO
 SG_ FLRRTrk20ObjectID : 61|6@0+ (1,0) [0|63] ""  CGM3b_FO

BO_ 1139 F_LRR_Obj_Track_19: 8 LRR_FO
 SG_ FLRRTrk19Conf : 49|2@0+ (1,0) [0|3] ""  CGM3b_FO
 SG_ FLRRTrk19BurstID : 63|2@0+ (1,0) [0|3] ""  CGM3b_FO
 SG_ FLRRTrk19Range : 5|11@0+ (0.125,0) [0|255.875] "m"  CGM3b_FO
 SG_ FLRRTrk19RangeRate : 10|11@0- (0.125,0) [-128|127.875] "m/s"  CGM3b_FO
 SG_ FLRRTrk19RangeAccel : 31|9@0- (0.125,0) [-32|31.875] "m/s^2"  CGM3b_FO
 SG_ FLRRTrk19DynProp : 38|3@0+ (1,0) [0|7] ""  CGM3b_FO
 SG_ FLRRTrk19Azimuth : 35|12@0- (0.125,0) [-256|255.875] "deg"  CGM3b_FO
 SG_ FLRRTrk19Width : 55|6@0+ (0.25,0) [0|15.75] "m"  CGM3b_FO
 SG_ FLRRTrk19MeasStatus : 7|2@0+ (1,0) [0|3] ""  CGM3b_FO
 SG_ FLRRTrk19ObjectID : 61|6@0+ (1,0) [0|63] ""  CGM3b_FO

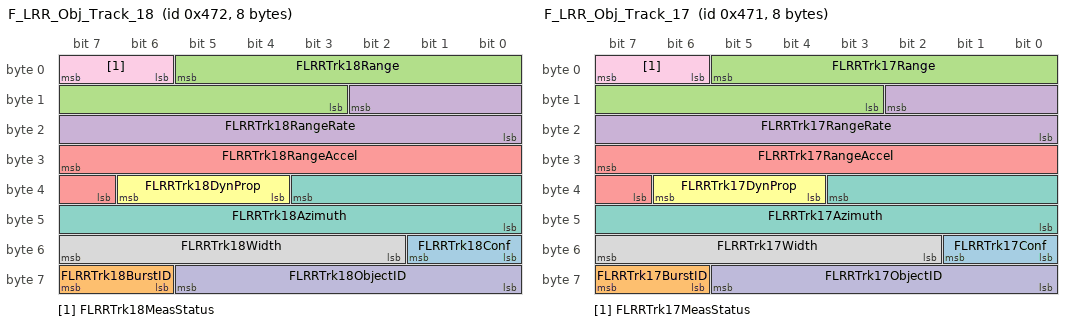
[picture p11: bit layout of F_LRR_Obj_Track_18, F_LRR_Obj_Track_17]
BO_ 1138 F_LRR_Obj_Track_18: 8 LRR_FO
 SG_ FLRRTrk18Conf : 49|2@0+ (1,0) [0|3] ""  CGM3b_FO
 SG_ FLRRTrk18BurstID : 63|2@0+ (1,0) [0|3] ""  CGM3b_FO
 SG_ FLRRTrk18Range : 5|11@0+ (0.125,0) [0|255.875] "m"  CGM3b_FO
 SG_ FLRRTrk18RangeRate : 10|11@0- (0.125,0) [-128|127.875] "m/s"  CGM3b_FO
 SG_ FLRRTrk18RangeAccel : 31|9@0- (0.125,0) [-32|31.875] "m/s^2"  CGM3b_FO
 SG_ FLRRTrk18DynProp : 38|3@0+ (1,0) [0|7] ""  CGM3b_FO
 SG_ FLRRTrk18Azimuth : 35|12@0- (0.125,0) [-256|255.875] "deg"  CGM3b_FO
 SG_ FLRRTrk18Width : 55|6@0+ (0.25,0) [0|15.75] "m"  CGM3b_FO
 SG_ FLRRTrk18MeasStatus : 7|2@0+ (1,0) [0|3] ""  CGM3b_FO
 SG_ FLRRTrk18ObjectID : 61|6@0+ (1,0) [0|63] ""  CGM3b_FO

BO_ 1137 F_LRR_Obj_Track_17: 8 LRR_FO
 SG_ FLRRTrk17Conf : 49|2@0+ (1,0) [0|3] ""  CGM3b_FO
 SG_ FLRRTrk17BurstID : 63|2@0+ (1,0) [0|3] ""  CGM3b_FO
 SG_ FLRRTrk17Range : 5|11@0+ (0.125,0) [0|255.875] "m"  CGM3b_FO
 SG_ FLRRTrk17RangeRate : 10|11@0- (0.125,0) [-128|127.875] "m/s"  CGM3b_FO
 SG_ FLRRTrk17RangeAccel : 31|9@0- (0.125,0) [-32|31.875] "m/s^2"  CGM3b_FO
 SG_ FLRRTrk17DynProp : 38|3@0+ (1,0) [0|7] ""  CGM3b_FO
 SG_ FLRRTrk17Azimuth : 35|12@0- (0.125,0) [-256|255.875] "deg"  CGM3b_FO
 SG_ FLRRTrk17Width : 55|6@0+ (0.25,0) [0|15.75] "m"  CGM3b_FO
 SG_ FLRRTrk17MeasStatus : 7|2@0+ (1,0) [0|3] ""  CGM3b_FO
 SG_ FLRRTrk17ObjectID : 61|6@0+ (1,0) [0|63] ""  CGM3b_FO

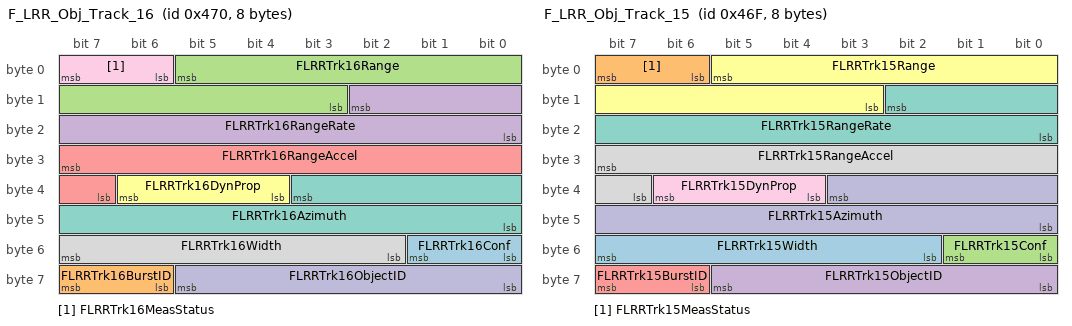
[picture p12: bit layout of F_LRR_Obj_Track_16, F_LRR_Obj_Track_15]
BO_ 1136 F_LRR_Obj_Track_16: 8 LRR_FO
 SG_ FLRRTrk16Conf : 49|2@0+ (1,0) [0|3] ""  CGM3b_FO
 SG_ FLRRTrk16BurstID : 63|2@0+ (1,0) [0|3] ""  CGM3b_FO
 SG_ FLRRTrk16Range : 5|11@0+ (0.125,0) [0|255.875] "m"  CGM3b_FO
 SG_ FLRRTrk16RangeRate : 10|11@0- (0.125,0) [-128|127.875] "m/s"  CGM3b_FO
 SG_ FLRRTrk16RangeAccel : 31|9@0- (0.125,0) [-32|31.875] "m/s^2"  CGM3b_FO
 SG_ FLRRTrk16DynProp : 38|3@0+ (1,0) [0|7] ""  CGM3b_FO
 SG_ FLRRTrk16Azimuth : 35|12@0- (0.125,0) [-256|255.875] "deg"  CGM3b_FO
 SG_ FLRRTrk16Width : 55|6@0+ (0.25,0) [0|15.75] "m"  CGM3b_FO
 SG_ FLRRTrk16MeasStatus : 7|2@0+ (1,0) [0|3] ""  CGM3b_FO
 SG_ FLRRTrk16ObjectID : 61|6@0+ (1,0) [0|63] ""  CGM3b_FO

BO_ 1135 F_LRR_Obj_Track_15: 8 LRR_FO
 SG_ FLRRTrk15Width : 55|6@0+ (0.25,0) [0|15.75] "m"  CGM3b_FO
 SG_ FLRRTrk15MeasStatus : 7|2@0+ (1,0) [0|3] ""  CGM3b_FO
 SG_ FLRRTrk15Conf : 49|2@0+ (1,0) [0|3] ""  CGM3b_FO
 SG_ FLRRTrk15ObjectID : 61|6@0+ (1,0) [0|63] ""  CGM3b_FO
 SG_ FLRRTrk15BurstID : 63|2@0+ (1,0) [0|3] ""  CGM3b_FO
 SG_ FLRRTrk15Range : 5|11@0+ (0.125,0) [0|255.875] "m"  CGM3b_FO
 SG_ FLRRTrk15RangeRate : 10|11@0- (0.125,0) [-128|127.875] "m/s"  CGM3b_FO
 SG_ FLRRTrk15RangeAccel : 31|9@0- (0.125,0) [-32|31.875] "m/s^2"  CGM3b_FO
 SG_ FLRRTrk15DynProp : 38|3@0+ (1,0) [0|7] ""  CGM3b_FO
 SG_ FLRRTrk15Azimuth : 35|12@0- (0.125,0) [-256|255.875] "deg"  CGM3b_FO

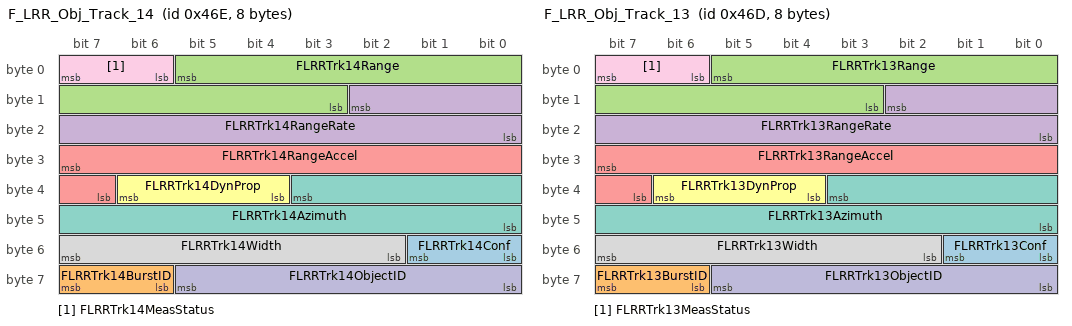
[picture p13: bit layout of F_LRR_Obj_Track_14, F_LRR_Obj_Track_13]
BO_ 1134 F_LRR_Obj_Track_14: 8 LRR_FO
 SG_ FLRRTrk14Conf : 49|2@0+ (1,0) [0|3] ""  CGM3b_FO
 SG_ FLRRTrk14BurstID : 63|2@0+ (1,0) [0|3] ""  CGM3b_FO
 SG_ FLRRTrk14Range : 5|11@0+ (0.125,0) [0|255.875] "m"  CGM3b_FO
 SG_ FLRRTrk14RangeRate : 10|11@0- (0.125,0) [-128|127.875] "m/s"  CGM3b_FO
 SG_ FLRRTrk14RangeAccel : 31|9@0- (0.125,0) [-32|31.875] "m/s^2"  CGM3b_FO
 SG_ FLRRTrk14DynProp : 38|3@0+ (1,0) [0|7] ""  CGM3b_FO
 SG_ FLRRTrk14Azimuth : 35|12@0- (0.125,0) [-256|255.875] "deg"  CGM3b_FO
 SG_ FLRRTrk14Width : 55|6@0+ (0.25,0) [0|15.75] "m"  CGM3b_FO
 SG_ FLRRTrk14MeasStatus : 7|2@0+ (1,0) [0|3] ""  CGM3b_FO
 SG_ FLRRTrk14ObjectID : 61|6@0+ (1,0) [0|63] ""  CGM3b_FO

BO_ 1133 F_LRR_Obj_Track_13: 8 LRR_FO
 SG_ FLRRTrk13Conf : 49|2@0+ (1,0) [0|3] ""  CGM3b_FO
 SG_ FLRRTrk13BurstID : 63|2@0+ (1,0) [0|3] ""  CGM3b_FO
 SG_ FLRRTrk13Range : 5|11@0+ (0.125,0) [0|255.875] "m"  CGM3b_FO
 SG_ FLRRTrk13RangeRate : 10|11@0- (0.125,0) [-128|127.875] "m/s"  CGM3b_FO
 SG_ FLRRTrk13RangeAccel : 31|9@0- (0.125,0) [-32|31.875] "m/s^2"  CGM3b_FO
 SG_ FLRRTrk13DynProp : 38|3@0+ (1,0) [0|7] ""  CGM3b_FO
 SG_ FLRRTrk13Azimuth : 35|12@0- (0.125,0) [-256|255.875] "deg"  CGM3b_FO
 SG_ FLRRTrk13Width : 55|6@0+ (0.25,0) [0|15.75] "m"  CGM3b_FO
 SG_ FLRRTrk13MeasStatus : 7|2@0+ (1,0) [0|3] ""  CGM3b_FO
 SG_ FLRRTrk13ObjectID : 61|6@0+ (1,0) [0|63] ""  CGM3b_FO

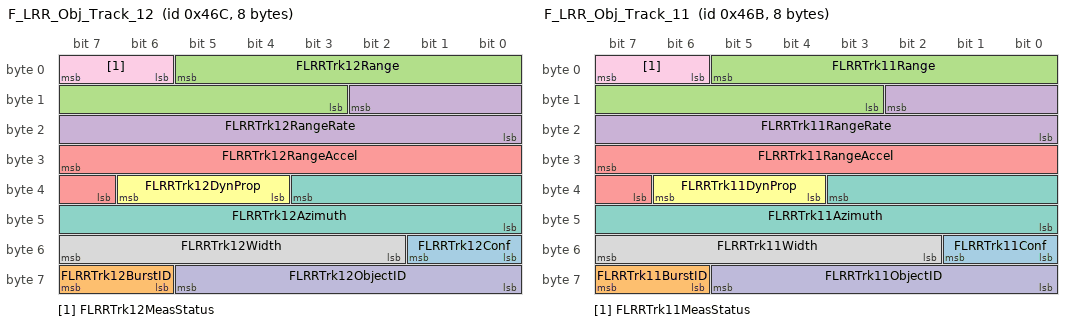
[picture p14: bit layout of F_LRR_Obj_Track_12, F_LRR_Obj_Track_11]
BO_ 1132 F_LRR_Obj_Track_12: 8 LRR_FO
 SG_ FLRRTrk12Conf : 49|2@0+ (1,0) [0|3] ""  CGM3b_FO
 SG_ FLRRTrk12BurstID : 63|2@0+ (1,0) [0|3] ""  CGM3b_FO
 SG_ FLRRTrk12Range : 5|11@0+ (0.125,0) [0|255.875] "m"  CGM3b_FO
 SG_ FLRRTrk12RangeRate : 10|11@0- (0.125,0) [-128|127.875] "m/s"  CGM3b_FO
 SG_ FLRRTrk12RangeAccel : 31|9@0- (0.125,0) [-32|31.875] "m/s^2"  CGM3b_FO
 SG_ FLRRTrk12DynProp : 38|3@0+ (1,0) [0|7] ""  CGM3b_FO
 SG_ FLRRTrk12Azimuth : 35|12@0- (0.125,0) [-256|255.875] "deg"  CGM3b_FO
 SG_ FLRRTrk12Width : 55|6@0+ (0.25,0) [0|15.75] "m"  CGM3b_FO
 SG_ FLRRTrk12MeasStatus : 7|2@0+ (1,0) [0|3] ""  CGM3b_FO
 SG_ FLRRTrk12ObjectID : 61|6@0+ (1,0) [0|63] ""  CGM3b_FO

BO_ 1131 F_LRR_Obj_Track_11: 8 LRR_FO
 SG_ FLRRTrk11Conf : 49|2@0+ (1,0) [0|3] ""  CGM3b_FO
 SG_ FLRRTrk11BurstID : 63|2@0+ (1,0) [0|3] ""  CGM3b_FO
 SG_ FLRRTrk11Range : 5|11@0+ (0.125,0) [0|255.875] "m"  CGM3b_FO
 SG_ FLRRTrk11RangeRate : 10|11@0- (0.125,0) [-128|127.875] "m/s"  CGM3b_FO
 SG_ FLRRTrk11RangeAccel : 31|9@0- (0.125,0) [-32|31.875] "m/s^2"  CGM3b_FO
 SG_ FLRRTrk11DynProp : 38|3@0+ (1,0) [0|7] ""  CGM3b_FO
 SG_ FLRRTrk11Azimuth : 35|12@0- (0.125,0) [-256|255.875] "deg"  CGM3b_FO
 SG_ FLRRTrk11Width : 55|6@0+ (0.25,0) [0|15.75] "m"  CGM3b_FO
 SG_ FLRRTrk11MeasStatus : 7|2@0+ (1,0) [0|3] ""  CGM3b_FO
 SG_ FLRRTrk11ObjectID : 61|6@0+ (1,0) [0|63] ""  CGM3b_FO

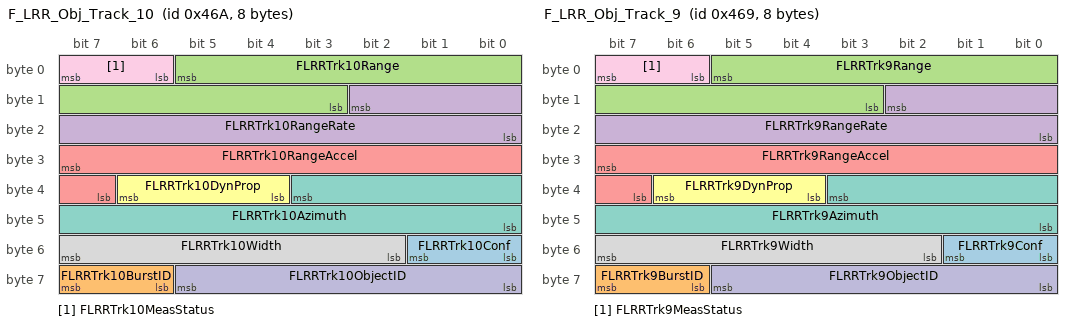
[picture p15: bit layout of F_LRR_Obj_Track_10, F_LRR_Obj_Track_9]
BO_ 1130 F_LRR_Obj_Track_10: 8 LRR_FO
 SG_ FLRRTrk10Conf : 49|2@0+ (1,0) [0|3] ""  CGM3b_FO
 SG_ FLRRTrk10BurstID : 63|2@0+ (1,0) [0|3] ""  CGM3b_FO
 SG_ FLRRTrk10Range : 5|11@0+ (0.125,0) [0|255.875] "m"  CGM3b_FO
 SG_ FLRRTrk10RangeRate : 10|11@0- (0.125,0) [-128|127.875] "m/s"  CGM3b_FO
 SG_ FLRRTrk10RangeAccel : 31|9@0- (0.125,0) [-32|31.875] "m/s^2"  CGM3b_FO
 SG_ FLRRTrk10DynProp : 38|3@0+ (1,0) [0|7] ""  CGM3b_FO
 SG_ FLRRTrk10Azimuth : 35|12@0- (0.125,0) [-256|255.875] "deg"  CGM3b_FO
 SG_ FLRRTrk10Width : 55|6@0+ (0.25,0) [0|15.75] "m"  CGM3b_FO
 SG_ FLRRTrk10MeasStatus : 7|2@0+ (1,0) [0|3] ""  CGM3b_FO
 SG_ FLRRTrk10ObjectID : 61|6@0+ (1,0) [0|63] ""  CGM3b_FO

BO_ 1129 F_LRR_Obj_Track_9: 8 LRR_FO
 SG_ FLRRTrk9Conf : 49|2@0+ (1,0) [0|3] ""  CGM3b_FO
 SG_ FLRRTrk9BurstID : 63|2@0+ (1,0) [0|3] ""  CGM3b_FO
 SG_ FLRRTrk9Range : 5|11@0+ (0.125,0) [0|255.875] "m"  CGM3b_FO
 SG_ FLRRTrk9RangeRate : 10|11@0- (0.125,0) [-128|127.875] "m/s"  CGM3b_FO
 SG_ FLRRTrk9RangeAccel : 31|9@0- (0.125,0) [-32|31.875] "m/s^2"  CGM3b_FO
 SG_ FLRRTrk9DynProp : 38|3@0+ (1,0) [0|7] ""  CGM3b_FO
 SG_ FLRRTrk9Azimuth : 35|12@0- (0.125,0) [-256|255.875] "deg"  CGM3b_FO
 SG_ FLRRTrk9Width : 55|6@0+ (0.25,0) [0|15.75] "m"  CGM3b_FO
 SG_ FLRRTrk9MeasStatus : 7|2@0+ (1,0) [0|3] ""  CGM3b_FO
 SG_ FLRRTrk9ObjectID : 61|6@0+ (1,0) [0|63] ""  CGM3b_FO

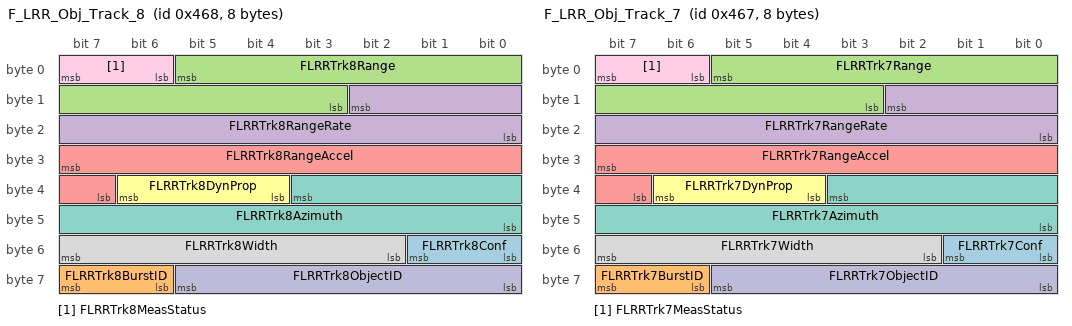
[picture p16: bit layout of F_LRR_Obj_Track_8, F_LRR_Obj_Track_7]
BO_ 1128 F_LRR_Obj_Track_8: 8 LRR_FO
 SG_ FLRRTrk8Conf : 49|2@0+ (1,0) [0|3] ""  CGM3b_FO
 SG_ FLRRTrk8BurstID : 63|2@0+ (1,0) [0|3] ""  CGM3b_FO
 SG_ FLRRTrk8Range : 5|11@0+ (0.125,0) [0|255.875] "m"  CGM3b_FO
 SG_ FLRRTrk8RangeRate : 10|11@0- (0.125,0) [-128|127.875] "m/s"  CGM3b_FO
 SG_ FLRRTrk8RangeAccel : 31|9@0- (0.125,0) [-32|31.875] "m/s^2"  CGM3b_FO
 SG_ FLRRTrk8DynProp : 38|3@0+ (1,0) [0|7] ""  CGM3b_FO
 SG_ FLRRTrk8Azimuth : 35|12@0- (0.125,0) [-256|255.875] "deg"  CGM3b_FO
 SG_ FLRRTrk8Width : 55|6@0+ (0.25,0) [0|15.75] "m"  CGM3b_FO
 SG_ FLRRTrk8MeasStatus : 7|2@0+ (1,0) [0|3] ""  CGM3b_FO
 SG_ FLRRTrk8ObjectID : 61|6@0+ (1,0) [0|63] ""  CGM3b_FO

BO_ 1127 F_LRR_Obj_Track_7: 8 LRR_FO
 SG_ FLRRTrk7Conf : 49|2@0+ (1,0) [0|3] ""  CGM3b_FO
 SG_ FLRRTrk7BurstID : 63|2@0+ (1,0) [0|3] ""  CGM3b_FO
 SG_ FLRRTrk7Range : 5|11@0+ (0.125,0) [0|255.875] "m"  CGM3b_FO
 SG_ FLRRTrk7RangeRate : 10|11@0- (0.125,0) [-128|127.875] "m/s"  CGM3b_FO
 SG_ FLRRTrk7RangeAccel : 31|9@0- (0.125,0) [-32|31.875] "m/s^2"  CGM3b_FO
 SG_ FLRRTrk7DynProp : 38|3@0+ (1,0) [0|7] ""  CGM3b_FO
 SG_ FLRRTrk7Azimuth : 35|12@0- (0.125,0) [-256|255.875] "deg"  CGM3b_FO
 SG_ FLRRTrk7Width : 55|6@0+ (0.25,0) [0|15.75] "m"  CGM3b_FO
 SG_ FLRRTrk7MeasStatus : 7|2@0+ (1,0) [0|3] ""  CGM3b_FO
 SG_ FLRRTrk7ObjectID : 61|6@0+ (1,0) [0|63] ""  CGM3b_FO

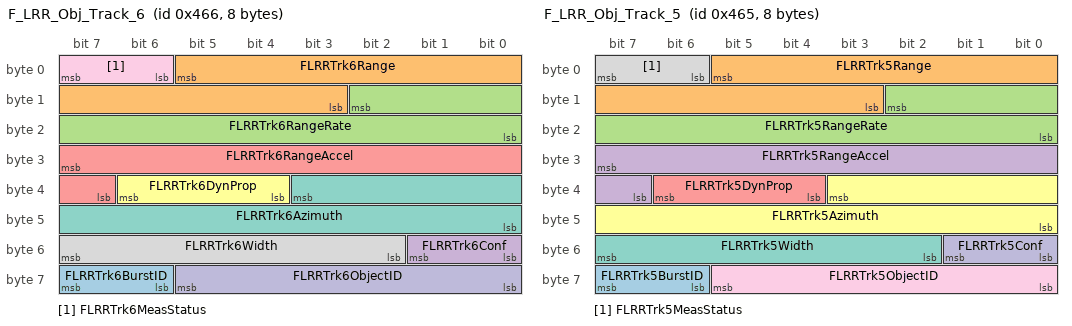
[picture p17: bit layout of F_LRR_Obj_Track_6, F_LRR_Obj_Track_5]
BO_ 1126 F_LRR_Obj_Track_6: 8 LRR_FO
 SG_ FLRRTrk6BurstID : 63|2@0+ (1,0) [0|3] ""  CGM3b_FO
 SG_ FLRRTrk6Range : 5|11@0+ (0.125,0) [0|255.875] "m"  CGM3b_FO
 SG_ FLRRTrk6RangeRate : 10|11@0- (0.125,0) [-128|127.875] "m/s"  CGM3b_FO
 SG_ FLRRTrk6Conf : 49|2@0+ (1,0) [0|3] ""  CGM3b_FO
 SG_ FLRRTrk6RangeAccel : 31|9@0- (0.125,0) [-32|31.875] "m/s^2"  CGM3b_FO
 SG_ FLRRTrk6DynProp : 38|3@0+ (1,0) [0|7] ""  CGM3b_FO
 SG_ FLRRTrk6Azimuth : 35|12@0- (0.125,0) [-256|255.875] "deg"  CGM3b_FO
 SG_ FLRRTrk6Width : 55|6@0+ (0.25,0) [0|15.75] "m"  CGM3b_FO
 SG_ FLRRTrk6MeasStatus : 7|2@0+ (1,0) [0|3] ""  CGM3b_FO
 SG_ FLRRTrk6ObjectID : 61|6@0+ (1,0) [0|63] ""  CGM3b_FO

BO_ 1125 F_LRR_Obj_Track_5: 8 LRR_FO
 SG_ FLRRTrk5BurstID : 63|2@0+ (1,0) [0|3] ""  CGM3b_FO
 SG_ FLRRTrk5Range : 5|11@0+ (0.125,0) [0|255.875] "m"  CGM3b_FO
 SG_ FLRRTrk5RangeRate : 10|11@0- (0.125,0) [-128|127.875] "m/s"  CGM3b_FO
 SG_ FLRRTrk5RangeAccel : 31|9@0- (0.125,0) [-32|31.875] "m/s^2"  CGM3b_FO
 SG_ FLRRTrk5DynProp : 38|3@0+ (1,0) [0|7] ""  CGM3b_FO
 SG_ FLRRTrk5Azimuth : 35|12@0- (0.125,0) [-256|255.875] "deg"  CGM3b_FO
 SG_ FLRRTrk5Width : 55|6@0+ (0.25,0) [0|15.75] "m"  CGM3b_FO
 SG_ FLRRTrk5MeasStatus : 7|2@0+ (1,0) [0|3] ""  CGM3b_FO
 SG_ FLRRTrk5ObjectID : 61|6@0+ (1,0) [0|63] ""  CGM3b_FO
 SG_ FLRRTrk5Conf : 49|2@0+ (1,0) [0|3] ""  CGM3b_FO

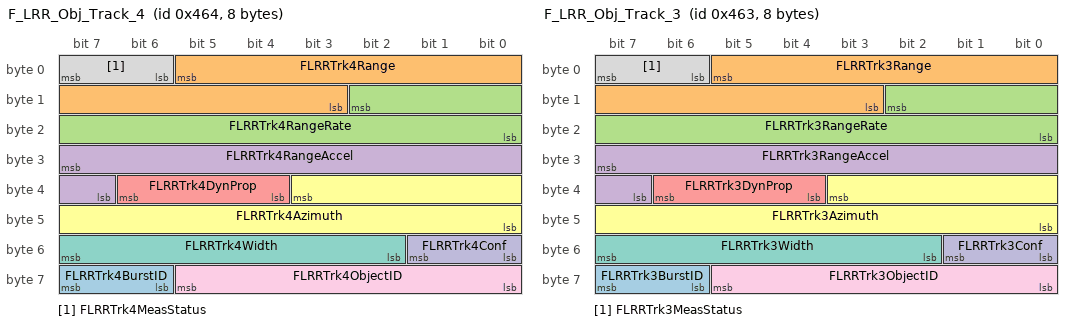
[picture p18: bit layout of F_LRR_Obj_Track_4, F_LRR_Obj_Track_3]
BO_ 1124 F_LRR_Obj_Track_4: 8 LRR_FO
 SG_ FLRRTrk4BurstID : 63|2@0+ (1,0) [0|3] ""  CGM3b_FO
 SG_ FLRRTrk4Range : 5|11@0+ (0.125,0) [0|255.875] "m"  CGM3b_FO
 SG_ FLRRTrk4RangeRate : 10|11@0- (0.125,0) [-128|127.875] "m/s"  CGM3b_FO
 SG_ FLRRTrk4RangeAccel : 31|9@0- (0.125,0) [-32|31.875] "m/s^2"  CGM3b_FO
 SG_ FLRRTrk4DynProp : 38|3@0+ (1,0) [0|7] ""  CGM3b_FO
 SG_ FLRRTrk4Azimuth : 35|12@0- (0.125,0) [-256|255.875] "deg"  CGM3b_FO
 SG_ FLRRTrk4Width : 55|6@0+ (0.25,0) [0|15.75] "m"  CGM3b_FO
 SG_ FLRRTrk4MeasStatus : 7|2@0+ (1,0) [0|3] ""  CGM3b_FO
 SG_ FLRRTrk4ObjectID : 61|6@0+ (1,0) [0|63] ""  CGM3b_FO
 SG_ FLRRTrk4Conf : 49|2@0+ (1,0) [0|3] ""  CGM3b_FO

BO_ 1123 F_LRR_Obj_Track_3: 8 LRR_FO
 SG_ FLRRTrk3BurstID : 63|2@0+ (1,0) [0|3] ""  CGM3b_FO
 SG_ FLRRTrk3Range : 5|11@0+ (0.125,0) [0|255.875] "m"  CGM3b_FO
 SG_ FLRRTrk3RangeRate : 10|11@0- (0.125,0) [-128|127.875] "m/s"  CGM3b_FO
 SG_ FLRRTrk3RangeAccel : 31|9@0- (0.125,0) [-32|31.875] "m/s^2"  CGM3b_FO
 SG_ FLRRTrk3DynProp : 38|3@0+ (1,0) [0|7] ""  CGM3b_FO
 SG_ FLRRTrk3Azimuth : 35|12@0- (0.125,0) [-256|255.875] "deg"  CGM3b_FO
 SG_ FLRRTrk3Width : 55|6@0+ (0.25,0) [0|15.75] "m"  CGM3b_FO
 SG_ FLRRTrk3MeasStatus : 7|2@0+ (1,0) [0|3] ""  CGM3b_FO
 SG_ FLRRTrk3ObjectID : 61|6@0+ (1,0) [0|63] ""  CGM3b_FO
 SG_ FLRRTrk3Conf : 49|2@0+ (1,0) [0|3] ""  CGM3b_FO

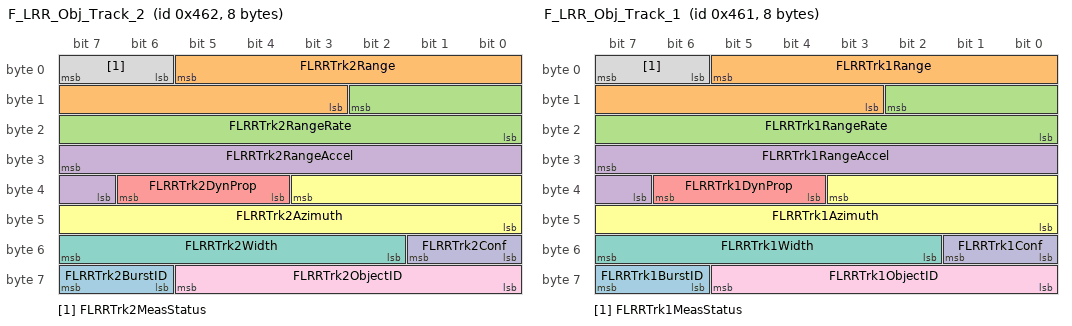
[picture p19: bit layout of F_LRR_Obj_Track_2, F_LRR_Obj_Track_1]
BO_ 1122 F_LRR_Obj_Track_2: 8 LRR_FO
 SG_ FLRRTrk2BurstID : 63|2@0+ (1,0) [0|3] ""  CGM3b_FO
 SG_ FLRRTrk2Range : 5|11@0+ (0.125,0) [0|255.875] "m"  CGM3b_FO
 SG_ FLRRTrk2RangeRate : 10|11@0- (0.125,0) [-128|127.875] "m/s"  CGM3b_FO
 SG_ FLRRTrk2RangeAccel : 31|9@0- (0.125,0) [-32|31.875] "m/s^2"  CGM3b_FO
 SG_ FLRRTrk2DynProp : 38|3@0+ (1,0) [0|7] ""  CGM3b_FO
 SG_ FLRRTrk2Azimuth : 35|12@0- (0.125,0) [-256|255.875] "deg"  CGM3b_FO
 SG_ FLRRTrk2Width : 55|6@0+ (0.25,0) [0|15.75] "m"  CGM3b_FO
 SG_ FLRRTrk2MeasStatus : 7|2@0+ (1,0) [0|3] ""  CGM3b_FO
 SG_ FLRRTrk2ObjectID : 61|6@0+ (1,0) [0|63] ""  CGM3b_FO
 SG_ FLRRTrk2Conf : 49|2@0+ (1,0) [0|3] ""  CGM3b_FO

BO_ 1121 F_LRR_Obj_Track_1: 8 LRR_FO
 SG_ FLRRTrk1BurstID : 63|2@0+ (1,0) [0|3] ""  CGM3b_FO
 SG_ FLRRTrk1Range : 5|11@0+ (0.125,0) [0|255.875] "m"  CGM3b_FO
 SG_ FLRRTrk1RangeRate : 10|11@0- (0.125,0) [-128|127.875] "m/s"  CGM3b_FO
 SG_ FLRRTrk1RangeAccel : 31|9@0- (0.125,0) [-32|31.875] "m/s^2"  CGM3b_FO
 SG_ FLRRTrk1DynProp : 38|3@0+ (1,0) [0|7] ""  CGM3b_FO
 SG_ FLRRTrk1Azimuth : 35|12@0- (0.125,0) [-256|255.875] "deg"  CGM3b_FO
 SG_ FLRRTrk1Width : 55|6@0+ (0.25,0) [0|15.75] "m"  CGM3b_FO
 SG_ FLRRTrk1MeasStatus : 7|2@0+ (1,0) [0|3] ""  CGM3b_FO
 SG_ FLRRTrk1ObjectID : 61|6@0+ (1,0) [0|63] ""  CGM3b_FO
 SG_ FLRRTrk1Conf : 49|2@0+ (1,0) [0|3] ""  CGM3b_FO

BO_ 1120 F_LRR_Obj_Header: 8 LRR_FO
 SG_ FLRRDiagSpare : 30|1@0+ (1,0) [0|1] ""  CGM3b_FO
 SG_ FLRRVltgOutRngLo : 44|1@0+ (1,0) [0|1] ""  CGM3b_FO
 SG_ FLRRVltgOutRngHi : 43|1@0+ (1,0) [0|1] ""  CGM3b_FO
 SG_ FLRRSvcAlgnInPrcs : 38|1@0+ (1,0) [0|1] ""  CGM3b_FO
 SG_ FLRRSnsrBlckd : 45|1@0+ (1,0) [0|1] ""  CGM3b_FO
 SG_ FLRRSnstvFltPrsntInt : 24|1@0+ (1,0) [0|1] ""  CGM3b_FO
 SG_ FLRRPlntAlgnInProc : 37|1@0+ (1,0) [0|1] ""  CGM3b_FO
 SG_ FLRRMsalgnYawRt : 47|1@0+ (1,0) [0|1] ""  CGM3b_FO
 SG_ FLRRMsalgnYawLt : 46|1@0+ (1,0) [0|1] ""  CGM3b_FO
 SG_ FLRRLonVelPlsblityFlt : 35|1@0+ (1,0) [0|1] ""  CGM3b_FO
 SG_ FLRRYawRtPlsblityFlt : 34|1@0+ (1,0) [0|1] ""  CGM3b_FO
 SG_ FLRRMsalgnPtchUp : 32|1@0+ (1,0) [0|1] ""  CGM3b_FO
 SG_ FLRRMsalgnPtchDn : 33|1@0+ (1,0) [0|1] ""  CGM3b_FO
 SG_ FLRRInitDiagCmplt : 40|1@0+ (1,0) [0|1] ""  CGM3b_FO
 SG_ FLRRHWFltPrsntInt : 25|1@0+ (1,0) [0|1] ""  CGM3b_FO
 SG_ FLRRExtIntrfrnc : 36|1@0+ (1,0) [0|1] ""  CGM3b_FO
 SG_ FLRRCANSgnlSpvFld : 29|1@0+ (1,0) [0|1] ""  CGM3b_FO
 SG_ FLRRCANRxErr : 28|1@0+ (1,0) [0|1] ""  CGM3b_FO
 SG_ FLRRTunlDtctd : 27|1@0+ (1,0) [0|1] ""  CGM3b_FO
 SG_ FLRRAmbTmpOutRngLw : 42|1@0+ (1,0) [0|1] ""  CGM3b_FO
 SG_ FLRRAmbTmpOutRngHi : 41|1@0+ (1,0) [0|1] ""  CGM3b_FO
 SG_ FLRRAntTngFltPrsnt : 26|1@0+ (1,0) [0|1] ""  CGM3b_FO
 SG_ FLRRAlgnFltPrsnt : 39|1@0+ (1,0) [0|1] ""  CGM3b_FO
 SG_ FLRRRollingCount : 7|2@0+ (1,0) [0|3] ""  CGM3b_FO
 SG_ FLRRModeCmdFdbk : 23|3@0+ (1,0) [0|7] ""  CGM3b_FO
 SG_ FLRRNumValidTargets : 20|5@0+ (1,0) [0|31] ""  CGM3b_FO
 SG_ FLRRTimeStampV : 31|1@0+ (1,0) [0|1] ""  CGM3b_FO
 SG_ FLRRTimeStamp : 2|11@0+ (1,0) [0|2047] "ms"  CGM3b_FO
 SG_ FLRRRoadTypeInfo : 5|3@0+ (1,0) [0|7] ""  CGM3b_FO
 SG_ FLRRBurstChecksum : 55|16@0+ (1,0) [0|65535] ""  CGM3b_FO

BO_ 1625 USDT_Resp_From_RSRR: 8 RSRR_FO
 SG_ DgnInf : 7|64@0+ (1,0) [0|1.84467440737096E+019] ""  CECM_R1_FO,CGM3b_FO

BO_ 1602 USDT_Resp_From_LRR_FO: 8 LRR_FO
 SG_ DgnInf : 7|64@0+ (1,0) [0|1.84467440737096E+019] ""  CECM_R1_FO,CGM3b_FO

CM_ "Front Object Bus";
CM_ BU_ Dummy_FO "This is to avoid single ended signalling";
CM_ BU_ EOCM2cp_K2_FO "External Object Control Module Safety co-pilot - K2 micro";
CM_ BU_ EOCM2cp_K1_FO "External Object Control Module Safety co-pilot - K1 micro";
CM_ BU_ EOCM2cp_IMX6_FO "External Object Control Module Safety co-pilot - IMX6 micro";
CM_ BU_ CECM_R1_FO "CAN to Ethernet Convertor Module";
CM_ BU_ CMMb_FO "Chassis Motion Module";
CM_ BU_ CMMa_FO "Chassis Motion Module";
CM_ BU_ RSRR_FO "Rear Short Range Radar";
CM_ BU_ LRR_FO "Long Range Radar";
CM_ BU_ CIPM_FO "Camera Image Processing Module";
CM_ BU_ IMU2_FO "6 Degrees of Freedom Inertial Measurement Unit 2";
CM_ BU_ IMU1_FO "6 Degrees of Freedom Inertial Measurement Unit 1";
CM_ BU_ CGM3b_FO "Communication Gateway  - Secondary";
CM_ SG_ 1923 DTCI_DTCSource_783 "This shall be equal to the Diagnostic Address of the transmittting device.";
CM_ SG_ 1923 DTCI_DTCFaultType_783 "Based on Powertrain definition.  Not expected to be supported by all devices.";
CM_ SG_ 1923 DTCI_DTCFailType_783 "Assigned per GMW3110, Appendix E";
CM_ SG_ 1920 DTCI_DTCSource_780 "This shall be equal to the Diagnostic Address of the transmittting device.";
CM_ SG_ 1920 DTCI_DTCFaultType_780 "Based on Powertrain definition.  Not expected to be supported by all devices.";
CM_ SG_ 1920 DTCI_DTCFailType_780 "Assigned per GMW3110, Appendix E";
CM_ BO_ 1194 "Application Is Tx ing this frame at the rate of 40 ms";
CM_ BO_ 1193 "Application Is Tx ing this frame at the rate of 40 ms";
CM_ BO_ 1192 "Application Is Tx ing this frame at the rate of 40 ms";
CM_ BO_ 1191 "Application Is Tx ing this frame at the rate of 40 ms";
CM_ BO_ 1190 "Application Is Tx ing this frame at the rate of 40 ms";
CM_ BO_ 1189 "Application Is Tx ing this frame at the rate of 40 ms";
CM_ BO_ 1188 "Application Is Tx ing this frame at the rate of 40 ms";
CM_ BO_ 1187 "Application Is Tx ing this frame at the rate of 40 ms";
CM_ BO_ 1186 "Application Is Tx ing this frame at the rate of 40 ms";
CM_ BO_ 1185 "Application Is Tx ing this frame at the rate of 40 ms";
CM_ BO_ 1184 "Application Is Tx ing this frame at the rate of 40 ms";
CM_ SG_ 1184 RSRRModeCmdFdbk "0 = Disabled
1 = Standby
2 = Enabled
3 + Reserved";
CM_ BO_ 1149 "Application Is Tx ing this frame at the rate of 66 ms";
CM_ BO_ 1148 "Application Is Tx ing this frame at the rate of 66 ms";
CM_ BO_ 1147 "Application Is Tx ing this frame at the rate of 66 ms";
CM_ BO_ 1146 "Application Is Tx ing this frame at the rate of 66 ms";
CM_ BO_ 1143 "Application Is Tx ing this frame at the rate of 66 ms";
CM_ BO_ 1142 "Application Is Tx ing this frame at the rate of 66 ms";
CM_ BO_ 1141 "Application Is Tx ing this frame at the rate of 66 ms";
CM_ BO_ 1140 "Application Is Tx ing this frame at the rate of 66 ms";
CM_ BO_ 1139 "Application Is Tx ing this frame at the rate of 66 ms";
CM_ BO_ 1138 "Application Is Tx ing this frame at the rate of 66 ms";
CM_ BO_ 1137 "Application Is Tx ing this frame at the rate of 66 ms";
CM_ BO_ 1136 "Application Is Tx ing this frame at the rate of 66 ms";
CM_ BO_ 1135 "Application Is Tx ing this frame at the rate of 66 ms";
CM_ BO_ 1134 "Application Is Tx ing this frame at the rate of 66 ms";
CM_ BO_ 1133 "Application Is Tx ing this frame at the rate of 66 ms";
CM_ BO_ 1132 "Application Is Tx ing this frame at the rate of 66 ms";
CM_ BO_ 1131 "Application Is Tx ing this frame at the rate of 66 ms";
CM_ BO_ 1130 "Application Is Tx ing this frame at the rate of 66 ms";
CM_ BO_ 1129 "Application Is Tx ing this frame at the rate of 66 ms";
CM_ BO_ 1128 "Application Is Tx ing this frame at the rate of 66 ms";
CM_ BO_ 1127 "Application Is Tx ing this frame at the rate of 66 ms";
CM_ BO_ 1126 "Application Is Tx ing this frame at the rate of 66 ms";
CM_ BO_ 1125 "Application Is Tx ing this frame at the rate of 66 ms";
CM_ BO_ 1124 "Application Is Tx ing this frame at the rate of 66 ms";
CM_ BO_ 1123 "Application Is Tx ing this frame at the rate of 66 ms";
CM_ BO_ 1122 "Application Is Tx ing this frame at the rate of 66 ms";
CM_ BO_ 1121 "Application Is Tx ing this frame at the rate of 66 ms";
CM_ BO_ 1120 "Application Is Tx ing this frame at the rate of 66 ms";
BA_DEF_  "BusType" STRING ;
BA_DEF_ SG_  "VNSigSLHSSharedDiagnostic" ENUM  "No","Yes";
BA_DEF_ SG_  "SignalType" STRING ;
BA_DEF_ SG_  "PacketOrder" INT 0 65535;
BA_DEF_ SG_  "SignalLongName" STRING ;
BA_DEF_ SG_  "GenSigStartValue" INT 0 65535;
BA_DEF_ SG_  "VNSigAllNodes" ENUM  "No","Yes";
BA_DEF_ SG_  "GenSigDeltaValue" INT 0 0;
BA_DEF_ SG_  "GenSigSendType" ENUM  "not used","not used","not used","not used","not used","not used","not used","NoSigSendType","not used","not used","OnAnyChange","OnChangeIfActive","OnDelta";
BA_DEF_ SG_  "GenSigSendOnInit" ENUM  "Not Initialized","Application","Handler";
BA_DEF_ BO_  "AppGenMsgCycleTime" INT 0 0;
BA_DEF_ BO_  "GenMsgILSupport" ENUM  "No","Yes";
BA_DEF_ BO_  "TpApplType" STRING ;
BA_DEF_ BO_  "Prio" INT 0 7;
BA_DEF_ BO_  "MessageSubnet" ENUM  "LS","HS","CE","PE","HV","FO","LE","HE2","PHS","PCE","DLCLS","DLCHS","DLCCE","DLCFO";
BA_DEF_ BO_  "DiagState" ENUM  "No","Yes";
BA_DEF_ BO_  "GenMsgDelayTime" INT 0 100000;
BA_DEF_ BO_  "GenMsgCycleTime" INT 0 100000;
BA_DEF_ BO_  "GenMsgCycleTimeFast" INT 0 100000;
BA_DEF_ BO_  "GenMsgSendType" ENUM  "cyclicX","spontanX","cyclicIfActiveX","spontanWithDelay","cyclicAndSpontanX","cyclicAndSpontanWithDelay","spontanWithRepitition","cyclicIfActiveAndSpontanWD";
BA_DEF_ BO_  "DiagResponse" ENUM  "No","Yes";
BA_DEF_ BO_  "DiagRequest" ENUM  "No","Yes";
BA_DEF_ BO_  "NmMessage" ENUM  "No","Yes";
BA_DEF_ BU_  "MessageManagerUsed" ENUM  "No","Yes";
BA_DEF_ BU_  "NmNode" ENUM  "No","Yes";
BA_DEF_ BU_  "ILUsed" ENUM  "No","Yes";
BA_DEF_ BU_  "NodeLayerModules" STRING ;
BA_DEF_ BU_  "VNECUSLHSSharedDiagnostic" ENUM  "None","Activator","Remoted","Activator and Remoted","Shared Local";
BA_DEF_ BU_  "VNECUAllNodes" ENUM  "None","Activator","Remoted","Activator and Remoted","Shared Local";
BA_DEF_ BU_  "ECU_Id" HEX 0 255;
BA_DEF_ BU_  "SourceId" HEX 0 253;
BA_DEF_  "VersionMonth" INT 0 255;
BA_DEF_  "SyncJumpWidthMax" INT 0 255;
BA_DEF_  "SyncJumpWidthMin" INT 0 255;
BA_DEF_  "SamplePointMax" FLOAT 0 100;
BA_DEF_  "SamplePointMin" FLOAT 0 100;
BA_DEF_  "Baudrate" INT 0 1000000;
BA_DEF_  "VehicleArchitecture" STRING ;
BA_DEF_  "VNInitActSLHS_VNReq" ENUM  "No","Yes";
BA_DEF_  "VNInitActSLHSSharedDiagnostic" ENUM  "No","Yes";
BA_DEF_  "VN_SLHSSharedDiagnostic" INT 0 255;
BA_DEF_  "VersionNumber" INT 0 65535;
BA_DEF_  "NmMessageCount" INT 0 32;
BA_DEF_  "NmBaseAddress" HEX 0 2032;
BA_DEF_  "NetworkType" STRING ;
BA_DEF_  "VNMFPeriodicInterval" INT 0 65535;
BA_DEF_  "BusWakeUpDelay" INT 0 65535;
BA_DEF_  "BusOffRecoveryTime" INT 0 65535;
BA_DEF_  "NodeStatusMsgID" HEX 0 536870911;
BA_DEF_  "NodeStatusMsgCycleTime" INT 0 65535;
BA_DEF_  "NodeStatusMsgTimeoutTime" INT 0 65535;
BA_DEF_  "UseGMParameterIDs" INT 0 1;
BA_DEF_  "VersionWeek" INT 0 255;
BA_DEF_  "VersionYear" INT 0 255;
BA_DEF_  "VN_AllNodes" INT 0 255;
BA_DEF_  "Manufacturer" ENUM  "DBAG","VAG","BMW","PAG","GM";
BA_DEF_  "NmType" STRING ;
BA_DEF_REL_ BU_SG_REL_  "GenSigSuprvRespComment" STRING ;
BA_DEF_REL_ BU_SG_REL_  "GenSigVBitResp" ENUM  "No","Yes";
BA_DEF_REL_ BU_SG_REL_  "GenSigVBitRespComment" STRING ;
BA_DEF_REL_ BU_SG_REL_  "GenSigVDAFailComment" STRING ;
BA_DEF_REL_ BU_SG_REL_  "GenSigRxStartValue" STRING ;
BA_DEF_REL_ BU_SG_REL_  "GenSigSuprvResp" ENUM  "None","Notify App","Substitute Default";
BA_DEF_REL_ BU_SG_REL_  "GenSigTimeoutMsg" HEX 0 268435455;
BA_DEF_REL_ BU_SG_REL_  "GenSigTimeoutTime" INT 0 15000;
BA_DEF_DEF_  "BusType" "";
BA_DEF_DEF_  "VNSigSLHSSharedDiagnostic" "No";
BA_DEF_DEF_  "SignalType" "";
BA_DEF_DEF_  "PacketOrder" 0;
BA_DEF_DEF_  "SignalLongName" "";
BA_DEF_DEF_  "GenSigStartValue" 0;
BA_DEF_DEF_  "VNSigAllNodes" "No";
BA_DEF_DEF_  "GenSigDeltaValue" 0;
BA_DEF_DEF_  "GenSigSendType" "NoSigSendType";
BA_DEF_DEF_  "GenSigSendOnInit" "Not Initialized";
BA_DEF_DEF_  "AppGenMsgCycleTime" 0;
BA_DEF_DEF_  "GenMsgILSupport" "Yes";
BA_DEF_DEF_  "TpApplType" "";
BA_DEF_DEF_  "Prio" 4;
BA_DEF_DEF_  "MessageSubnet" "LS";
BA_DEF_DEF_  "DiagState" "No";
BA_DEF_DEF_  "GenMsgDelayTime" 0;
BA_DEF_DEF_  "GenMsgCycleTime" 0;
BA_DEF_DEF_  "GenMsgCycleTimeFast" 0;
BA_DEF_DEF_  "GenMsgSendType" "spontanX";
BA_DEF_DEF_  "DiagResponse" "No";
BA_DEF_DEF_  "DiagRequest" "No";
BA_DEF_DEF_  "NmMessage" "No";
BA_DEF_DEF_REL_ "GenSigSuprvRespComment" "";
BA_DEF_DEF_REL_ "GenSigVBitResp" "No";
BA_DEF_DEF_REL_ "GenSigVBitRespComment" "";
BA_DEF_DEF_REL_ "GenSigVDAFailComment" "";
BA_DEF_DEF_REL_ "GenSigRxStartValue" "";
BA_DEF_DEF_REL_ "GenSigSuprvResp" "None";
BA_DEF_DEF_REL_ "GenSigTimeoutMsg" 0;
BA_DEF_DEF_REL_ "GenSigTimeoutTime" 0;
BA_DEF_DEF_  "MessageManagerUsed" "Yes";
BA_DEF_DEF_  "NmNode" "Yes";
BA_DEF_DEF_  "ILUsed" "Yes";
BA_DEF_DEF_  "NodeLayerModules" "gmlan02.dll";
BA_DEF_DEF_  "VNECUSLHSSharedDiagnostic" "None";
BA_DEF_DEF_  "VNECUAllNodes" "None";
BA_DEF_DEF_  "ECU_Id" 0;
BA_DEF_DEF_  "SourceId" 0;
BA_DEF_DEF_  "VersionMonth" 0;
BA_DEF_DEF_  "SyncJumpWidthMax" 0;
BA_DEF_DEF_  "SyncJumpWidthMin" 0;
BA_DEF_DEF_  "SamplePointMax" 0;
BA_DEF_DEF_  "SamplePointMin" 0;
BA_DEF_DEF_  "Baudrate" 0;
BA_DEF_DEF_  "VehicleArchitecture" "";
BA_DEF_DEF_  "VNInitActSLHS_VNReq" "No";
BA_DEF_DEF_  "VNInitActSLHSSharedDiagnostic" "No";
BA_DEF_DEF_  "VN_SLHSSharedDiagnostic" 0;
BA_DEF_DEF_  "VersionNumber" 0;
BA_DEF_DEF_  "NmMessageCount" 32;
BA_DEF_DEF_  "NmBaseAddress" 1568;
BA_DEF_DEF_  "NetworkType" "";
BA_DEF_DEF_  "VNMFPeriodicInterval" 3000;
BA_DEF_DEF_  "BusWakeUpDelay" 100;
BA_DEF_DEF_  "BusOffRecoveryTime" 0;
BA_DEF_DEF_  "NodeStatusMsgID" 268427264;
BA_DEF_DEF_  "NodeStatusMsgCycleTime" 1200;
BA_DEF_DEF_  "NodeStatusMsgTimeoutTime" 0;
BA_DEF_DEF_  "UseGMParameterIDs" 1;
BA_DEF_DEF_  "VersionWeek" 0;
BA_DEF_DEF_  "VersionYear" 0;
BA_DEF_DEF_  "VN_AllNodes" 1;
BA_DEF_DEF_  "Manufacturer" "GM";
BA_DEF_DEF_  "NmType" "GMLAN";
BA_ "VersionMonth" 19;
BA_ "SyncJumpWidthMax" 4;
BA_ "SyncJumpWidthMin" 3;
BA_ "SamplePointMax" 81.25;
BA_ "SamplePointMin" 80;
BA_ "Baudrate" 500000;
BA_ "VehicleArchitecture" "G2KCA";
BA_ "VNInitActSLHS_VNReq" 1;
BA_ "VNInitActSLHSSharedDiagnostic" 1;
BA_ "NmMessageCount" 16;
BA_ "NmBaseAddress" 1552;
BA_ "NetworkType" "Powertrain";
BA_ "BusOffRecoveryTime" 160;
BA_ "NodeStatusMsgID" 0;
BA_ "UseGMParameterIDs" 0;
BA_ "VersionWeek" 38;
BA_ "VersionYear" 19;
BA_ "BusType" "CAN";
BA_ "VNECUSLHSSharedDiagnostic" BU_ Dummy_FO 4;
BA_ "VNECUAllNodes" BU_ Dummy_FO 4;
BA_ "VNECUSLHSSharedDiagnostic" BU_ EOCM2cp_K2_FO 4;
BA_ "VNECUAllNodes" BU_ EOCM2cp_K2_FO 4;
BA_ "ECU_Id" BU_ EOCM2cp_K2_FO 11;
BA_ "SourceId" BU_ EOCM2cp_K2_FO 219;
BA_ "VNECUSLHSSharedDiagnostic" BU_ EOCM2cp_K1_FO 4;
BA_ "VNECUAllNodes" BU_ EOCM2cp_K1_FO 4;
BA_ "ECU_Id" BU_ EOCM2cp_K1_FO 10;
BA_ "SourceId" BU_ EOCM2cp_K1_FO 108;
BA_ "VNECUSLHSSharedDiagnostic" BU_ EOCM2cp_IMX6_FO 4;
BA_ "VNECUAllNodes" BU_ EOCM2cp_IMX6_FO 4;
BA_ "ECU_Id" BU_ EOCM2cp_IMX6_FO 16;
BA_ "SourceId" BU_ EOCM2cp_IMX6_FO 220;
BA_ "VNECUSLHSSharedDiagnostic" BU_ CECM_R1_FO 4;
BA_ "VNECUAllNodes" BU_ CECM_R1_FO 4;
BA_ "ECU_Id" BU_ CECM_R1_FO 5;
BA_ "SourceId" BU_ CECM_R1_FO 74;
BA_ "VNECUSLHSSharedDiagnostic" BU_ CMMb_FO 4;
BA_ "VNECUAllNodes" BU_ CMMb_FO 4;
BA_ "ECU_Id" BU_ CMMb_FO 22;
BA_ "SourceId" BU_ CMMb_FO 62;
BA_ "VNECUSLHSSharedDiagnostic" BU_ CMMa_FO 4;
BA_ "VNECUAllNodes" BU_ CMMa_FO 4;
BA_ "ECU_Id" BU_ CMMa_FO 27;
BA_ "SourceId" BU_ CMMa_FO 61;
BA_ "VNECUSLHSSharedDiagnostic" BU_ RSRR_FO 4;
BA_ "VNECUAllNodes" BU_ RSRR_FO 4;
BA_ "ECU_Id" BU_ RSRR_FO 25;
BA_ "SourceId" BU_ RSRR_FO 215;
BA_ "VNECUSLHSSharedDiagnostic" BU_ LRR_FO 4;
BA_ "VNECUAllNodes" BU_ LRR_FO 4;
BA_ "ECU_Id" BU_ LRR_FO 2;
BA_ "SourceId" BU_ LRR_FO 210;
BA_ "VNECUSLHSSharedDiagnostic" BU_ CIPM_FO 4;
BA_ "VNECUAllNodes" BU_ CIPM_FO 4;
BA_ "ECU_Id" BU_ CIPM_FO 21;
BA_ "SourceId" BU_ CIPM_FO 188;
BA_ "VNECUSLHSSharedDiagnostic" BU_ IMU2_FO 4;
BA_ "VNECUAllNodes" BU_ IMU2_FO 4;
BA_ "ECU_Id" BU_ IMU2_FO 8;
BA_ "SourceId" BU_ IMU2_FO 47;
BA_ "VNECUSLHSSharedDiagnostic" BU_ IMU1_FO 4;
BA_ "VNECUAllNodes" BU_ IMU1_FO 4;
BA_ "ECU_Id" BU_ IMU1_FO 4;
BA_ "SourceId" BU_ IMU1_FO 44;
BA_ "VNECUSLHSSharedDiagnostic" BU_ CGM3b_FO 4;
BA_ "VNECUAllNodes" BU_ CGM3b_FO 4;
BA_ "ECU_Id" BU_ CGM3b_FO 29;
BA_ "SourceId" BU_ CGM3b_FO 72;
BA_ "Prio" BO_ 1923 0;
BA_ "MessageSubnet" BO_ 1923 5;
BA_ "GenMsgCycleTime" BO_ 1923 1000;
BA_ "Prio" BO_ 1920 0;
BA_ "MessageSubnet" BO_ 1920 5;
BA_ "GenMsgCycleTime" BO_ 1920 1000;
BA_ "Prio" BO_ 1789 0;
BA_ "MessageSubnet" BO_ 1789 5;
BA_ "GenMsgCycleTime" BO_ 1789 100;
BA_ "GenMsgSendType" BO_ 1789 0;
BA_ "Prio" BO_ 1786 0;
BA_ "MessageSubnet" BO_ 1786 5;
BA_ "GenMsgCycleTime" BO_ 1786 100;
BA_ "GenMsgSendType" BO_ 1786 0;
BA_ "Prio" BO_ 1537 0;
BA_ "MessageSubnet" BO_ 1537 5;
BA_ "GenMsgDelayTime" BO_ 1537 10;
BA_ "AppGenMsgCycleTime" BO_ 1194 40;
BA_ "Prio" BO_ 1194 0;
BA_ "MessageSubnet" BO_ 1194 5;
BA_ "AppGenMsgCycleTime" BO_ 1193 40;
BA_ "Prio" BO_ 1193 0;
BA_ "MessageSubnet" BO_ 1193 5;
BA_ "AppGenMsgCycleTime" BO_ 1192 40;
BA_ "Prio" BO_ 1192 0;
BA_ "MessageSubnet" BO_ 1192 5;
BA_ "AppGenMsgCycleTime" BO_ 1191 40;
BA_ "Prio" BO_ 1191 0;
BA_ "MessageSubnet" BO_ 1191 5;
BA_ "AppGenMsgCycleTime" BO_ 1190 40;
BA_ "Prio" BO_ 1190 0;
BA_ "MessageSubnet" BO_ 1190 5;
BA_ "AppGenMsgCycleTime" BO_ 1189 40;
BA_ "Prio" BO_ 1189 0;
BA_ "MessageSubnet" BO_ 1189 5;
BA_ "AppGenMsgCycleTime" BO_ 1188 40;
BA_ "Prio" BO_ 1188 0;
BA_ "MessageSubnet" BO_ 1188 5;
BA_ "AppGenMsgCycleTime" BO_ 1187 40;
BA_ "Prio" BO_ 1187 0;
BA_ "MessageSubnet" BO_ 1187 5;
BA_ "AppGenMsgCycleTime" BO_ 1186 40;
BA_ "Prio" BO_ 1186 0;
BA_ "MessageSubnet" BO_ 1186 5;
BA_ "AppGenMsgCycleTime" BO_ 1185 40;
BA_ "Prio" BO_ 1185 0;
BA_ "MessageSubnet" BO_ 1185 5;
BA_ "AppGenMsgCycleTime" BO_ 1184 40;
BA_ "Prio" BO_ 1184 0;
BA_ "MessageSubnet" BO_ 1184 5;
BA_ "AppGenMsgCycleTime" BO_ 1151 66;
BA_ "Prio" BO_ 1151 0;
BA_ "MessageSubnet" BO_ 1151 5;
BA_ "AppGenMsgCycleTime" BO_ 1150 66;
BA_ "Prio" BO_ 1150 0;
BA_ "MessageSubnet" BO_ 1150 5;
BA_ "AppGenMsgCycleTime" BO_ 1149 66;
BA_ "Prio" BO_ 1149 0;
BA_ "MessageSubnet" BO_ 1149 5;
BA_ "AppGenMsgCycleTime" BO_ 1148 66;
BA_ "Prio" BO_ 1148 0;
BA_ "MessageSubnet" BO_ 1148 5;
BA_ "AppGenMsgCycleTime" BO_ 1147 66;
BA_ "Prio" BO_ 1147 0;
BA_ "MessageSubnet" BO_ 1147 5;
BA_ "AppGenMsgCycleTime" BO_ 1146 66;
BA_ "Prio" BO_ 1146 0;
BA_ "MessageSubnet" BO_ 1146 5;
BA_ "AppGenMsgCycleTime" BO_ 1143 66;
BA_ "Prio" BO_ 1143 0;
BA_ "MessageSubnet" BO_ 1143 5;
BA_ "AppGenMsgCycleTime" BO_ 1142 66;
BA_ "Prio" BO_ 1142 0;
BA_ "MessageSubnet" BO_ 1142 5;
BA_ "AppGenMsgCycleTime" BO_ 1141 66;
BA_ "Prio" BO_ 1141 0;
BA_ "MessageSubnet" BO_ 1141 5;
BA_ "AppGenMsgCycleTime" BO_ 1140 66;
BA_ "Prio" BO_ 1140 0;
BA_ "MessageSubnet" BO_ 1140 5;
BA_ "AppGenMsgCycleTime" BO_ 1139 66;
BA_ "Prio" BO_ 1139 0;
BA_ "MessageSubnet" BO_ 1139 5;
BA_ "AppGenMsgCycleTime" BO_ 1138 66;
BA_ "Prio" BO_ 1138 0;
BA_ "MessageSubnet" BO_ 1138 5;
BA_ "AppGenMsgCycleTime" BO_ 1137 66;
BA_ "Prio" BO_ 1137 0;
BA_ "MessageSubnet" BO_ 1137 5;
BA_ "AppGenMsgCycleTime" BO_ 1136 66;
BA_ "Prio" BO_ 1136 0;
BA_ "MessageSubnet" BO_ 1136 5;
BA_ "AppGenMsgCycleTime" BO_ 1135 66;
BA_ "Prio" BO_ 1135 0;
BA_ "MessageSubnet" BO_ 1135 5;
BA_ "AppGenMsgCycleTime" BO_ 1134 66;
BA_ "Prio" BO_ 1134 0;
BA_ "MessageSubnet" BO_ 1134 5;
BA_ "AppGenMsgCycleTime" BO_ 1133 66;
BA_ "Prio" BO_ 1133 0;
BA_ "MessageSubnet" BO_ 1133 5;
BA_ "AppGenMsgCycleTime" BO_ 1132 66;
BA_ "Prio" BO_ 1132 0;
BA_ "MessageSubnet" BO_ 1132 5;
BA_ "AppGenMsgCycleTime" BO_ 1131 66;
BA_ "Prio" BO_ 1131 0;
BA_ "MessageSubnet" BO_ 1131 5;
BA_ "AppGenMsgCycleTime" BO_ 1130 66;
BA_ "Prio" BO_ 1130 0;
BA_ "MessageSubnet" BO_ 1130 5;
BA_ "AppGenMsgCycleTime" BO_ 1129 66;
BA_ "Prio" BO_ 1129 0;
BA_ "MessageSubnet" BO_ 1129 5;
BA_ "AppGenMsgCycleTime" BO_ 1128 66;
BA_ "Prio" BO_ 1128 0;
BA_ "MessageSubnet" BO_ 1128 5;
BA_ "AppGenMsgCycleTime" BO_ 1127 66;
BA_ "Prio" BO_ 1127 0;
BA_ "MessageSubnet" BO_ 1127 5;
BA_ "AppGenMsgCycleTime" BO_ 1126 66;
BA_ "Prio" BO_ 1126 0;
BA_ "MessageSubnet" BO_ 1126 5;
BA_ "AppGenMsgCycleTime" BO_ 1125 66;
BA_ "Prio" BO_ 1125 0;
BA_ "MessageSubnet" BO_ 1125 5;
BA_ "AppGenMsgCycleTime" BO_ 1124 66;
BA_ "Prio" BO_ 1124 0;
BA_ "MessageSubnet" BO_ 1124 5;
BA_ "AppGenMsgCycleTime" BO_ 1123 66;
BA_ "Prio" BO_ 1123 0;
BA_ "MessageSubnet" BO_ 1123 5;
BA_ "AppGenMsgCycleTime" BO_ 1122 66;
BA_ "Prio" BO_ 1122 0;
BA_ "MessageSubnet" BO_ 1122 5;
BA_ "AppGenMsgCycleTime" BO_ 1121 66;
BA_ "Prio" BO_ 1121 0;
BA_ "MessageSubnet" BO_ 1121 5;
BA_ "AppGenMsgCycleTime" BO_ 1120 66;
BA_ "Prio" BO_ 1120 0;
BA_ "MessageSubnet" BO_ 1120 5;
BA_ "Prio" BO_ 1625 0;
BA_ "MessageSubnet" BO_ 1625 5;
BA_ "DiagResponse" BO_ 1625 1;
BA_ "Prio" BO_ 1602 0;
BA_ "MessageSubnet" BO_ 1602 5;
BA_ "DiagResponse" BO_ 1602 1;
BA_ "SignalType" SG_ 1923 DTCI_WrnIndRqdSt_783 "BLN";
BA_ "PacketOrder" SG_ 1923 DTCI_WrnIndRqdSt_783 12;
BA_ "SignalLongName" SG_ 1923 DTCI_WrnIndRqdSt_783 "Diagnostic Trouble Code Information Extended 783 : Warning Indicator Requested Status";
BA_ "VNSigAllNodes" SG_ 1923 DTCI_WrnIndRqdSt_783 1;
BA_ "SignalType" SG_ 1923 DTCI_TstNPsdPwrUpSt_783 "BLN";
BA_ "PacketOrder" SG_ 1923 DTCI_TstNPsdPwrUpSt_783 14;
BA_ "SignalLongName" SG_ 1923 DTCI_TstNPsdPwrUpSt_783 "Diagnostic Trouble Code Information Extended 783 : Test Not Passed Since Power Up Status";
BA_ "VNSigAllNodes" SG_ 1923 DTCI_TstNPsdPwrUpSt_783 1;
BA_ "SignalType" SG_ 1923 DTCI_TstNPsdCdClrdSt_783 "BLN";
BA_ "PacketOrder" SG_ 1923 DTCI_TstNPsdCdClrdSt_783 17;
BA_ "SignalLongName" SG_ 1923 DTCI_TstNPsdCdClrdSt_783 "Diagnostic Trouble Code Information Extended 783 : Test Not Passed Since Code Cleared Status";
BA_ "VNSigAllNodes" SG_ 1923 DTCI_TstNPsdCdClrdSt_783 1;
BA_ "SignalType" SG_ 1923 DTCI_TstFldPwrUpSt_783 "BLN";
BA_ "PacketOrder" SG_ 1923 DTCI_TstFldPwrUpSt_783 13;
BA_ "SignalLongName" SG_ 1923 DTCI_TstFldPwrUpSt_783 "Diagnostic Trouble Code Information Extended 783 : Test Failed Since Power Up Status";
BA_ "VNSigAllNodes" SG_ 1923 DTCI_TstFldPwrUpSt_783 1;
BA_ "SignalType" SG_ 1923 DTCI_TstFldCdClrdStat_783 "BLN";
BA_ "PacketOrder" SG_ 1923 DTCI_TstFldCdClrdStat_783 16;
BA_ "SignalLongName" SG_ 1923 DTCI_TstFldCdClrdStat_783 "Diagnostic Trouble Code Information Extended 783 : Test Failed Since Code Cleared Status";
BA_ "VNSigAllNodes" SG_ 1923 DTCI_TstFldCdClrdStat_783 1;
BA_ "SignalType" SG_ 1923 DTCI_HistStat_783 "BLN";
BA_ "PacketOrder" SG_ 1923 DTCI_HistStat_783 15;
BA_ "SignalLongName" SG_ 1923 DTCI_HistStat_783 "Diagnostic Trouble Code Information Extended 783 : History Status";
BA_ "VNSigAllNodes" SG_ 1923 DTCI_HistStat_783 1;
BA_ "SignalType" SG_ 1923 DTCI_DTCTriggered_783 "BLN";
BA_ "PacketOrder" SG_ 1923 DTCI_DTCTriggered_783 8;
BA_ "SignalLongName" SG_ 1923 DTCI_DTCTriggered_783 "Diagnostic Trouble Code Information Extended 783 : Diagnostic Trouble Code Triggered";
BA_ "VNSigAllNodes" SG_ 1923 DTCI_DTCTriggered_783 1;
BA_ "SignalType" SG_ 1923 DTCI_DTCSource_783 "UNM";
BA_ "PacketOrder" SG_ 1923 DTCI_DTCSource_783 9;
BA_ "SignalLongName" SG_ 1923 DTCI_DTCSource_783 "Diagnostic Trouble Code Information Extended 783 : Diagnostic Trouble Code Source";
BA_ "VNSigAllNodes" SG_ 1923 DTCI_DTCSource_783 1;
BA_ "SignalType" SG_ 1923 DTCI_DTCNumber_783 "UNM";
BA_ "PacketOrder" SG_ 1923 DTCI_DTCNumber_783 10;
BA_ "SignalLongName" SG_ 1923 DTCI_DTCNumber_783 "Diagnostic Trouble Code Information Extended 783 : Diagnostic Trouble Code Number";
BA_ "VNSigAllNodes" SG_ 1923 DTCI_DTCNumber_783 1;
BA_ "SignalType" SG_ 1923 DTCI_DTCFaultType_783 "ENM";
BA_ "PacketOrder" SG_ 1923 DTCI_DTCFaultType_783 20;
BA_ "SignalLongName" SG_ 1923 DTCI_DTCFaultType_783 "Diagnostic Trouble Code Information Extended 783 : Diagnostic Trouble Code Fault Type";
BA_ "VNSigAllNodes" SG_ 1923 DTCI_DTCFaultType_783 1;
BA_ "SignalType" SG_ 1923 DTCI_DTCFailType_783 "UNM";
BA_ "PacketOrder" SG_ 1923 DTCI_DTCFailType_783 11;
BA_ "SignalLongName" SG_ 1923 DTCI_DTCFailType_783 "Diagnostic Trouble Code Information Extended 783 : Diagnostic Trouble Code Failure Type";
BA_ "VNSigAllNodes" SG_ 1923 DTCI_DTCFailType_783 1;
BA_ "SignalType" SG_ 1923 DTCI_CurrentStatus_783 "BLN";
BA_ "PacketOrder" SG_ 1923 DTCI_CurrentStatus_783 18;
BA_ "SignalLongName" SG_ 1923 DTCI_CurrentStatus_783 "Diagnostic Trouble Code Information Extended 783 : Current Status";
BA_ "VNSigAllNodes" SG_ 1923 DTCI_CurrentStatus_783 1;
BA_ "SignalType" SG_ 1923 DTCI_CodeSupported_783 "BLN";
BA_ "PacketOrder" SG_ 1923 DTCI_CodeSupported_783 19;
BA_ "SignalLongName" SG_ 1923 DTCI_CodeSupported_783 "Diagnostic Trouble Code Information Extended 783 : Code Supported";
BA_ "VNSigAllNodes" SG_ 1923 DTCI_CodeSupported_783 1;
BA_ "SignalType" SG_ 1923 DTCIUnused7_783 "BLN";
BA_ "PacketOrder" SG_ 1923 DTCIUnused7_783 7;
BA_ "SignalLongName" SG_ 1923 DTCIUnused7_783 "Diagnostic Trouble Code Information Extended 783 : Unused 7";
BA_ "VNSigAllNodes" SG_ 1923 DTCIUnused7_783 1;
BA_ "SignalType" SG_ 1923 DTCIUnused6_783 "BLN";
BA_ "PacketOrder" SG_ 1923 DTCIUnused6_783 6;
BA_ "SignalLongName" SG_ 1923 DTCIUnused6_783 "Diagnostic Trouble Code Information Extended 783 : Unused 6";
BA_ "VNSigAllNodes" SG_ 1923 DTCIUnused6_783 1;
BA_ "SignalType" SG_ 1923 DTCIUnused5_783 "BLN";
BA_ "PacketOrder" SG_ 1923 DTCIUnused5_783 5;
BA_ "SignalLongName" SG_ 1923 DTCIUnused5_783 "Diagnostic Trouble Code Information Extended 783 : Unused 5";
BA_ "VNSigAllNodes" SG_ 1923 DTCIUnused5_783 1;
BA_ "SignalType" SG_ 1923 DTCIUnused4_783 "BLN";
BA_ "PacketOrder" SG_ 1923 DTCIUnused4_783 4;
BA_ "SignalLongName" SG_ 1923 DTCIUnused4_783 "Diagnostic Trouble Code Information Extended 783 : Unused 4";
BA_ "VNSigAllNodes" SG_ 1923 DTCIUnused4_783 1;
BA_ "SignalType" SG_ 1923 DTCIUnused3_783 "BLN";
BA_ "PacketOrder" SG_ 1923 DTCIUnused3_783 3;
BA_ "SignalLongName" SG_ 1923 DTCIUnused3_783 "Diagnostic Trouble Code Information Extended 783 : Unused 3";
BA_ "VNSigAllNodes" SG_ 1923 DTCIUnused3_783 1;
BA_ "SignalType" SG_ 1923 DTCIUnused2_783 "BLN";
BA_ "PacketOrder" SG_ 1923 DTCIUnused2_783 2;
BA_ "SignalLongName" SG_ 1923 DTCIUnused2_783 "Diagnostic Trouble Code Information Extended 783 : Unused 2";
BA_ "VNSigAllNodes" SG_ 1923 DTCIUnused2_783 1;
BA_ "SignalType" SG_ 1923 DTCIUnused1_783 "BLN";
BA_ "PacketOrder" SG_ 1923 DTCIUnused1_783 1;
BA_ "SignalLongName" SG_ 1923 DTCIUnused1_783 "Diagnostic Trouble Code Information Extended 783 : Unused 1";
BA_ "VNSigAllNodes" SG_ 1923 DTCIUnused1_783 1;
BA_ "SignalType" SG_ 1920 DTCI_CurrentStatus_780 "BLN";
BA_ "PacketOrder" SG_ 1920 DTCI_CurrentStatus_780 18;
BA_ "SignalLongName" SG_ 1920 DTCI_CurrentStatus_780 "Diagnostic Trouble Code Information Extended 780 : Current Status";
BA_ "VNSigAllNodes" SG_ 1920 DTCI_CurrentStatus_780 1;
BA_ "SignalType" SG_ 1920 DTCI_WrnIndRqdSt_780 "BLN";
BA_ "PacketOrder" SG_ 1920 DTCI_WrnIndRqdSt_780 12;
BA_ "SignalLongName" SG_ 1920 DTCI_WrnIndRqdSt_780 "Diagnostic Trouble Code Information Extended 780 : Warning Indicator Requested Status";
BA_ "VNSigAllNodes" SG_ 1920 DTCI_WrnIndRqdSt_780 1;
BA_ "SignalType" SG_ 1920 DTCIUnused7_780 "BLN";
BA_ "PacketOrder" SG_ 1920 DTCIUnused7_780 7;
BA_ "SignalLongName" SG_ 1920 DTCIUnused7_780 "Diagnostic Trouble Code Information Extended 780 : Unused 7";
BA_ "VNSigAllNodes" SG_ 1920 DTCIUnused7_780 1;
BA_ "SignalType" SG_ 1920 DTCIUnused6_780 "BLN";
BA_ "PacketOrder" SG_ 1920 DTCIUnused6_780 6;
BA_ "SignalLongName" SG_ 1920 DTCIUnused6_780 "Diagnostic Trouble Code Information Extended 780 : Unused 6";
BA_ "VNSigAllNodes" SG_ 1920 DTCIUnused6_780 1;
BA_ "SignalType" SG_ 1920 DTCIUnused5_780 "BLN";
BA_ "PacketOrder" SG_ 1920 DTCIUnused5_780 5;
BA_ "SignalLongName" SG_ 1920 DTCIUnused5_780 "Diagnostic Trouble Code Information Extended 780 : Unused 5";
BA_ "VNSigAllNodes" SG_ 1920 DTCIUnused5_780 1;
BA_ "SignalType" SG_ 1920 DTCIUnused4_780 "BLN";
BA_ "PacketOrder" SG_ 1920 DTCIUnused4_780 4;
BA_ "SignalLongName" SG_ 1920 DTCIUnused4_780 "Diagnostic Trouble Code Information Extended 780 : Unused 4";
BA_ "VNSigAllNodes" SG_ 1920 DTCIUnused4_780 1;
BA_ "SignalType" SG_ 1920 DTCIUnused3_780 "BLN";
BA_ "PacketOrder" SG_ 1920 DTCIUnused3_780 3;
BA_ "SignalLongName" SG_ 1920 DTCIUnused3_780 "Diagnostic Trouble Code Information Extended 780 : Unused 3";
BA_ "VNSigAllNodes" SG_ 1920 DTCIUnused3_780 1;
BA_ "SignalType" SG_ 1920 DTCIUnused2_780 "BLN";
BA_ "PacketOrder" SG_ 1920 DTCIUnused2_780 2;
BA_ "SignalLongName" SG_ 1920 DTCIUnused2_780 "Diagnostic Trouble Code Information Extended 780 : Unused 2";
BA_ "VNSigAllNodes" SG_ 1920 DTCIUnused2_780 1;
BA_ "SignalType" SG_ 1920 DTCIUnused1_780 "BLN";
BA_ "PacketOrder" SG_ 1920 DTCIUnused1_780 1;
BA_ "SignalLongName" SG_ 1920 DTCIUnused1_780 "Diagnostic Trouble Code Information Extended 780 : Unused 1";
BA_ "VNSigAllNodes" SG_ 1920 DTCIUnused1_780 1;
BA_ "SignalType" SG_ 1920 DTCI_TstNPsdPwrUpSt_780 "BLN";
BA_ "PacketOrder" SG_ 1920 DTCI_TstNPsdPwrUpSt_780 14;
BA_ "SignalLongName" SG_ 1920 DTCI_TstNPsdPwrUpSt_780 "Diagnostic Trouble Code Information Extended 780 : Test Not Passed Since Power Up Status";
BA_ "VNSigAllNodes" SG_ 1920 DTCI_TstNPsdPwrUpSt_780 1;
BA_ "SignalType" SG_ 1920 DTCI_TstNPsdCdClrdSt_780 "BLN";
BA_ "PacketOrder" SG_ 1920 DTCI_TstNPsdCdClrdSt_780 17;
BA_ "SignalLongName" SG_ 1920 DTCI_TstNPsdCdClrdSt_780 "Diagnostic Trouble Code Information Extended 780 : Test Not Passed Since Code Cleared Status";
BA_ "VNSigAllNodes" SG_ 1920 DTCI_TstNPsdCdClrdSt_780 1;
BA_ "SignalType" SG_ 1920 DTCI_TstFldPwrUpSt_780 "BLN";
BA_ "PacketOrder" SG_ 1920 DTCI_TstFldPwrUpSt_780 13;
BA_ "SignalLongName" SG_ 1920 DTCI_TstFldPwrUpSt_780 "Diagnostic Trouble Code Information Extended 780 : Test Failed Since Power Up Status";
BA_ "VNSigAllNodes" SG_ 1920 DTCI_TstFldPwrUpSt_780 1;
BA_ "SignalType" SG_ 1920 DTCI_TstFldCdClrdStat_780 "BLN";
BA_ "PacketOrder" SG_ 1920 DTCI_TstFldCdClrdStat_780 16;
BA_ "SignalLongName" SG_ 1920 DTCI_TstFldCdClrdStat_780 "Diagnostic Trouble Code Information Extended 780 : Test Failed Since Code Cleared Status";
BA_ "VNSigAllNodes" SG_ 1920 DTCI_TstFldCdClrdStat_780 1;
BA_ "SignalType" SG_ 1920 DTCI_HistStat_780 "BLN";
BA_ "PacketOrder" SG_ 1920 DTCI_HistStat_780 15;
BA_ "SignalLongName" SG_ 1920 DTCI_HistStat_780 "Diagnostic Trouble Code Information Extended 780 : History Status";
BA_ "VNSigAllNodes" SG_ 1920 DTCI_HistStat_780 1;
BA_ "SignalType" SG_ 1920 DTCI_DTCTriggered_780 "BLN";
BA_ "PacketOrder" SG_ 1920 DTCI_DTCTriggered_780 8;
BA_ "SignalLongName" SG_ 1920 DTCI_DTCTriggered_780 "Diagnostic Trouble Code Information Extended 780 : Diagnostic Trouble Code Triggered";
BA_ "VNSigAllNodes" SG_ 1920 DTCI_DTCTriggered_780 1;
BA_ "SignalType" SG_ 1920 DTCI_DTCSource_780 "UNM";
BA_ "PacketOrder" SG_ 1920 DTCI_DTCSource_780 9;
BA_ "SignalLongName" SG_ 1920 DTCI_DTCSource_780 "Diagnostic Trouble Code Information Extended 780 : Diagnostic Trouble Code Source";
BA_ "VNSigAllNodes" SG_ 1920 DTCI_DTCSource_780 1;
BA_ "SignalType" SG_ 1920 DTCI_DTCNumber_780 "UNM";
BA_ "PacketOrder" SG_ 1920 DTCI_DTCNumber_780 10;
BA_ "SignalLongName" SG_ 1920 DTCI_DTCNumber_780 "Diagnostic Trouble Code Information Extended 780 : Diagnostic Trouble Code Number";
BA_ "VNSigAllNodes" SG_ 1920 DTCI_DTCNumber_780 1;
BA_ "SignalType" SG_ 1920 DTCI_DTCFaultType_780 "ENM";
BA_ "PacketOrder" SG_ 1920 DTCI_DTCFaultType_780 20;
BA_ "SignalLongName" SG_ 1920 DTCI_DTCFaultType_780 "Diagnostic Trouble Code Information Extended 780 : Diagnostic Trouble Code Fault Type";
BA_ "VNSigAllNodes" SG_ 1920 DTCI_DTCFaultType_780 1;
BA_ "SignalType" SG_ 1920 DTCI_DTCFailType_780 "UNM";
BA_ "PacketOrder" SG_ 1920 DTCI_DTCFailType_780 11;
BA_ "SignalLongName" SG_ 1920 DTCI_DTCFailType_780 "Diagnostic Trouble Code Information Extended 780 : Diagnostic Trouble Code Failure Type";
BA_ "VNSigAllNodes" SG_ 1920 DTCI_DTCFailType_780 1;
BA_ "SignalType" SG_ 1920 DTCI_CodeSupported_780 "BLN";
BA_ "PacketOrder" SG_ 1920 DTCI_CodeSupported_780 19;
BA_ "SignalLongName" SG_ 1920 DTCI_CodeSupported_780 "Diagnostic Trouble Code Information Extended 780 : Code Supported";
BA_ "VNSigAllNodes" SG_ 1920 DTCI_CodeSupported_780 1;
BA_ "SignalType" SG_ 1789 RSRREngCmdDta "UNM";
BA_ "SignalLongName" SG_ 1789 RSRREngCmdDta "Rear Short Range Radar Engineering Command Data";
BA_ "VNSigAllNodes" SG_ 1789 RSRREngCmdDta 1;
BA_ "SignalType" SG_ 1786 RSRREngRspDta "UNM";
BA_ "SignalLongName" SG_ 1786 RSRREngRspDta "Rear Short Range Radar Engineering Response Data";
BA_ "VNSigAllNodes" SG_ 1786 RSRREngRspDta 1;
BA_ "SignalType" SG_ 1537 RSRRYear "ASC";
BA_ "SignalLongName" SG_ 1537 RSRRYear "Rear Short Range Radar Year";
BA_ "VNSigAllNodes" SG_ 1537 RSRRYear 1;
BA_ "SignalType" SG_ 1537 RSRRSerialNmbr "ASC";
BA_ "SignalLongName" SG_ 1537 RSRRSerialNmbr "Rear Short Range Radar Serial Number";
BA_ "VNSigAllNodes" SG_ 1537 RSRRSerialNmbr 1;
BA_ "SignalType" SG_ 1537 RSRRJulianDate "ASC";
BA_ "SignalLongName" SG_ 1537 RSRRJulianDate "Rear Short Range Radar Julian Date";
BA_ "VNSigAllNodes" SG_ 1537 RSRRJulianDate 1;
BA_ "SignalType" SG_ 1194 RSrrBurstID10 "UNM";
BA_ "SignalLongName" SG_ 1194 RSrrBurstID10 "Rear Short Range Radar Burst ID 10";
BA_ "VNSigAllNodes" SG_ 1194 RSrrBurstID10 1;
BA_ "SignalType" SG_ 1194 RSrrTrkRange10 "UNM";
BA_ "SignalLongName" SG_ 1194 RSrrTrkRange10 "Rear Short Range Radar Track Range 10";
BA_ "VNSigAllNodes" SG_ 1194 RSrrTrkRange10 1;
BA_ "SignalType" SG_ 1194 RSrrTrkRRate10 "SNM";
BA_ "SignalLongName" SG_ 1194 RSrrTrkRRate10 "Rear Short Range Radar Track Range Rate 10";
BA_ "VNSigAllNodes" SG_ 1194 RSrrTrkRRate10 1;
BA_ "SignalType" SG_ 1194 RSrrTrkAzimuth10 "SNM";
BA_ "SignalLongName" SG_ 1194 RSrrTrkAzimuth10 "Rear Short Range Radar Track Azimuth 10";
BA_ "VNSigAllNodes" SG_ 1194 RSrrTrkAzimuth10 1;
BA_ "SignalType" SG_ 1194 RSrrTrkObjID10 "UNM";
BA_ "SignalLongName" SG_ 1194 RSrrTrkObjID10 "Rear Short Range Radar Track Object ID 10";
BA_ "VNSigAllNodes" SG_ 1194 RSrrTrkObjID10 1;
BA_ "SignalType" SG_ 1194 RSrrTrkObjElevation10 "ENM";
BA_ "SignalLongName" SG_ 1194 RSrrTrkObjElevation10 "Rear Short Range Radar Track Object Elevation 10";
BA_ "VNSigAllNodes" SG_ 1194 RSrrTrkObjElevation10 1;
BA_ "SignalType" SG_ 1194 RSrrTrkDynamProp10 "ENM";
BA_ "SignalLongName" SG_ 1194 RSrrTrkDynamProp10 "Rear Short Range Radar Track Dynamic Property 10";
BA_ "VNSigAllNodes" SG_ 1194 RSrrTrkDynamProp10 1;
BA_ "SignalType" SG_ 1194 RSrrTrkMeasStatus10 "ENM";
BA_ "SignalLongName" SG_ 1194 RSrrTrkMeasStatus10 "Rear Short Range Radar Track Measurement Status 10";
BA_ "VNSigAllNodes" SG_ 1194 RSrrTrkMeasStatus10 1;
BA_ "SignalType" SG_ 1194 RSrrTrkObsRange10 "SNM";
BA_ "SignalLongName" SG_ 1194 RSrrTrkObsRange10 "Rear Short Range Radar Track Observed Range 10";
BA_ "VNSigAllNodes" SG_ 1194 RSrrTrkObsRange10 1;
BA_ "SignalType" SG_ 1194 RSrrTrkRawAzimuth10 "SNM";
BA_ "SignalLongName" SG_ 1194 RSrrTrkRawAzimuth10 "Rear Short Range Radar Track Raw Azimuth 10";
BA_ "VNSigAllNodes" SG_ 1194 RSrrTrkRawAzimuth10 1;
BA_ "SignalType" SG_ 1193 RSrrBurstID9 "UNM";
BA_ "SignalLongName" SG_ 1193 RSrrBurstID9 "Rear Short Range Radar Burst ID 9";
BA_ "VNSigAllNodes" SG_ 1193 RSrrBurstID9 1;
BA_ "SignalType" SG_ 1193 RSrrTrkRange9 "UNM";
BA_ "SignalLongName" SG_ 1193 RSrrTrkRange9 "Rear Short Range Radar Track Range 9";
BA_ "VNSigAllNodes" SG_ 1193 RSrrTrkRange9 1;
BA_ "SignalType" SG_ 1193 RSrrTrkRRate9 "SNM";
BA_ "SignalLongName" SG_ 1193 RSrrTrkRRate9 "Rear Short Range Radar Track Range Rate 9";
BA_ "VNSigAllNodes" SG_ 1193 RSrrTrkRRate9 1;
BA_ "SignalType" SG_ 1193 RSrrTrkAzimuth9 "SNM";
BA_ "SignalLongName" SG_ 1193 RSrrTrkAzimuth9 "Rear Short Range Radar Track Azimuth 9";
BA_ "VNSigAllNodes" SG_ 1193 RSrrTrkAzimuth9 1;
BA_ "SignalType" SG_ 1193 RSrrTrkObjID9 "UNM";
BA_ "SignalLongName" SG_ 1193 RSrrTrkObjID9 "Rear Short Range Radar Track Object ID 9";
BA_ "VNSigAllNodes" SG_ 1193 RSrrTrkObjID9 1;
BA_ "SignalType" SG_ 1193 RSrrTrkObjElevation9 "ENM";
BA_ "SignalLongName" SG_ 1193 RSrrTrkObjElevation9 "Rear Short Range Radar Track Object Elevation 9";
BA_ "VNSigAllNodes" SG_ 1193 RSrrTrkObjElevation9 1;
BA_ "SignalType" SG_ 1193 RSrrTrkDynamProp9 "ENM";
BA_ "SignalLongName" SG_ 1193 RSrrTrkDynamProp9 "Rear Short Range Radar Track Dynamic Property 9";
BA_ "VNSigAllNodes" SG_ 1193 RSrrTrkDynamProp9 1;
BA_ "SignalType" SG_ 1193 RSrrTrkMeasStatus9 "ENM";
BA_ "SignalLongName" SG_ 1193 RSrrTrkMeasStatus9 "Rear Short Range Radar Track Measurement Status 9";
BA_ "VNSigAllNodes" SG_ 1193 RSrrTrkMeasStatus9 1;
BA_ "SignalType" SG_ 1193 RSrrTrkObsRange9 "SNM";
BA_ "SignalLongName" SG_ 1193 RSrrTrkObsRange9 "Rear Short Range Radar Track Observed Range 9";
BA_ "VNSigAllNodes" SG_ 1193 RSrrTrkObsRange9 1;
BA_ "SignalType" SG_ 1193 RSrrTrkRawAzimuth9 "SNM";
BA_ "SignalLongName" SG_ 1193 RSrrTrkRawAzimuth9 "Rear Short Range Radar Track Raw Azimuth 9";
BA_ "VNSigAllNodes" SG_ 1193 RSrrTrkRawAzimuth9 1;
BA_ "SignalType" SG_ 1192 RSrrTrkObjElevation8 "ENM";
BA_ "SignalLongName" SG_ 1192 RSrrTrkObjElevation8 "Rear Short Range Radar Track Object Elevation 8";
BA_ "VNSigAllNodes" SG_ 1192 RSrrTrkObjElevation8 1;
BA_ "SignalType" SG_ 1192 RSrrTrkDynamProp8 "ENM";
BA_ "SignalLongName" SG_ 1192 RSrrTrkDynamProp8 "Rear Short Range Radar Track Dynamic Property 8";
BA_ "VNSigAllNodes" SG_ 1192 RSrrTrkDynamProp8 1;
BA_ "SignalType" SG_ 1192 RSrrTrkMeasStatus8 "ENM";
BA_ "SignalLongName" SG_ 1192 RSrrTrkMeasStatus8 "Rear Short Range Radar Track Measurement Status 8";
BA_ "VNSigAllNodes" SG_ 1192 RSrrTrkMeasStatus8 1;
BA_ "SignalType" SG_ 1192 RSrrTrkObsRange8 "SNM";
BA_ "SignalLongName" SG_ 1192 RSrrTrkObsRange8 "Rear Short Range Radar Track Observed Range 8";
BA_ "VNSigAllNodes" SG_ 1192 RSrrTrkObsRange8 1;
BA_ "SignalType" SG_ 1192 RSrrTrkRawAzimuth8 "SNM";
BA_ "SignalLongName" SG_ 1192 RSrrTrkRawAzimuth8 "Rear Short Range Radar Track Raw Azimuth 8";
BA_ "VNSigAllNodes" SG_ 1192 RSrrTrkRawAzimuth8 1;
BA_ "SignalType" SG_ 1192 RSrrBurstID8 "UNM";
BA_ "SignalLongName" SG_ 1192 RSrrBurstID8 "Rear Short Range Radar Burst ID 8";
BA_ "VNSigAllNodes" SG_ 1192 RSrrBurstID8 1;
BA_ "SignalType" SG_ 1192 RSrrTrkRange8 "UNM";
BA_ "SignalLongName" SG_ 1192 RSrrTrkRange8 "Rear Short Range Radar Track Range 8";
BA_ "VNSigAllNodes" SG_ 1192 RSrrTrkRange8 1;
BA_ "SignalType" SG_ 1192 RSrrTrkRRate8 "SNM";
BA_ "SignalLongName" SG_ 1192 RSrrTrkRRate8 "Rear Short Range Radar Track Range Rate 8";
BA_ "VNSigAllNodes" SG_ 1192 RSrrTrkRRate8 1;
BA_ "SignalType" SG_ 1192 RSrrTrkAzimuth8 "SNM";
BA_ "SignalLongName" SG_ 1192 RSrrTrkAzimuth8 "Rear Short Range Radar Track Azimuth 8";
BA_ "VNSigAllNodes" SG_ 1192 RSrrTrkAzimuth8 1;
BA_ "SignalType" SG_ 1192 RSrrTrkObjID8 "UNM";
BA_ "SignalLongName" SG_ 1192 RSrrTrkObjID8 "Rear Short Range Radar Track Object ID 8";
BA_ "VNSigAllNodes" SG_ 1192 RSrrTrkObjID8 1;
BA_ "SignalType" SG_ 1191 RSrrBurstID7 "UNM";
BA_ "SignalLongName" SG_ 1191 RSrrBurstID7 "Rear Short Range Radar Burst ID 7";
BA_ "VNSigAllNodes" SG_ 1191 RSrrBurstID7 1;
BA_ "SignalType" SG_ 1191 RSrrTrkRange7 "UNM";
BA_ "SignalLongName" SG_ 1191 RSrrTrkRange7 "Rear Short Range Radar Track Range 7";
BA_ "VNSigAllNodes" SG_ 1191 RSrrTrkRange7 1;
BA_ "SignalType" SG_ 1191 RSrrTrkRRate7 "SNM";
BA_ "SignalLongName" SG_ 1191 RSrrTrkRRate7 "Rear Short Range Radar Track Range Rate 7";
BA_ "VNSigAllNodes" SG_ 1191 RSrrTrkRRate7 1;
BA_ "SignalType" SG_ 1191 RSrrTrkAzimuth7 "SNM";
BA_ "SignalLongName" SG_ 1191 RSrrTrkAzimuth7 "Rear Short Range Radar Track Azimuth 7";
BA_ "VNSigAllNodes" SG_ 1191 RSrrTrkAzimuth7 1;
BA_ "SignalType" SG_ 1191 RSrrTrkObjID7 "UNM";
BA_ "SignalLongName" SG_ 1191 RSrrTrkObjID7 "Rear Short Range Radar Track Object ID 7";
BA_ "VNSigAllNodes" SG_ 1191 RSrrTrkObjID7 1;
BA_ "SignalType" SG_ 1191 RSrrTrkObjElevation7 "ENM";
BA_ "SignalLongName" SG_ 1191 RSrrTrkObjElevation7 "Rear Short Range Radar Track Object Elevation 7";
BA_ "VNSigAllNodes" SG_ 1191 RSrrTrkObjElevation7 1;
BA_ "SignalType" SG_ 1191 RSrrTrkDynamProp7 "ENM";
BA_ "SignalLongName" SG_ 1191 RSrrTrkDynamProp7 "Rear Short Range Radar Track Dynamic Property 7";
BA_ "VNSigAllNodes" SG_ 1191 RSrrTrkDynamProp7 1;
BA_ "SignalType" SG_ 1191 RSrrTrkMeasStatus7 "ENM";
BA_ "SignalLongName" SG_ 1191 RSrrTrkMeasStatus7 "Rear Short Range Radar Track Measurement Status 7";
BA_ "VNSigAllNodes" SG_ 1191 RSrrTrkMeasStatus7 1;
BA_ "SignalType" SG_ 1191 RSrrTrkObsRange7 "SNM";
BA_ "SignalLongName" SG_ 1191 RSrrTrkObsRange7 "Rear Short Range Radar Track Observed Range 7";
BA_ "VNSigAllNodes" SG_ 1191 RSrrTrkObsRange7 1;
BA_ "SignalType" SG_ 1191 RSrrTrkRawAzimuth7 "SNM";
BA_ "SignalLongName" SG_ 1191 RSrrTrkRawAzimuth7 "Rear Short Range Radar Track Raw Azimuth 7";
BA_ "VNSigAllNodes" SG_ 1191 RSrrTrkRawAzimuth7 1;
BA_ "SignalType" SG_ 1190 RSrrBurstID6 "UNM";
BA_ "SignalLongName" SG_ 1190 RSrrBurstID6 "Rear Short Range Radar Burst ID 6";
BA_ "VNSigAllNodes" SG_ 1190 RSrrBurstID6 1;
BA_ "SignalType" SG_ 1190 RSrrTrkRange6 "UNM";
BA_ "SignalLongName" SG_ 1190 RSrrTrkRange6 "Rear Short Range Radar Track Range 6";
BA_ "VNSigAllNodes" SG_ 1190 RSrrTrkRange6 1;
BA_ "SignalType" SG_ 1190 RSrrTrkRRate6 "SNM";
BA_ "SignalLongName" SG_ 1190 RSrrTrkRRate6 "Rear Short Range Radar Track Range Rate 6";
BA_ "VNSigAllNodes" SG_ 1190 RSrrTrkRRate6 1;
BA_ "SignalType" SG_ 1190 RSrrTrkAzimuth6 "SNM";
BA_ "SignalLongName" SG_ 1190 RSrrTrkAzimuth6 "Rear Short Range Radar Track Azimuth 6";
BA_ "VNSigAllNodes" SG_ 1190 RSrrTrkAzimuth6 1;
BA_ "SignalType" SG_ 1190 RSrrTrkObjID6 "UNM";
BA_ "SignalLongName" SG_ 1190 RSrrTrkObjID6 "Rear Short Range Radar Track Object ID 6";
BA_ "VNSigAllNodes" SG_ 1190 RSrrTrkObjID6 1;
BA_ "SignalType" SG_ 1190 RSrrTrkObjElevation6 "ENM";
BA_ "SignalLongName" SG_ 1190 RSrrTrkObjElevation6 "Rear Short Range Radar Track Object Elevation 6";
BA_ "VNSigAllNodes" SG_ 1190 RSrrTrkObjElevation6 1;
BA_ "SignalType" SG_ 1190 RSrrTrkDynamProp6 "ENM";
BA_ "SignalLongName" SG_ 1190 RSrrTrkDynamProp6 "Rear Short Range Radar Track Dynamic Property 6";
BA_ "VNSigAllNodes" SG_ 1190 RSrrTrkDynamProp6 1;
BA_ "SignalType" SG_ 1190 RSrrTrkMeasStatus6 "ENM";
BA_ "SignalLongName" SG_ 1190 RSrrTrkMeasStatus6 "Rear Short Range Radar Track Measurement Status 6";
BA_ "VNSigAllNodes" SG_ 1190 RSrrTrkMeasStatus6 1;
BA_ "SignalType" SG_ 1190 RSrrTrkObsRange6 "SNM";
BA_ "SignalLongName" SG_ 1190 RSrrTrkObsRange6 "Rear Short Range Radar Track Observed Range 6";
BA_ "VNSigAllNodes" SG_ 1190 RSrrTrkObsRange6 1;
BA_ "SignalType" SG_ 1190 RSrrTrkRawAzimuth6 "SNM";
BA_ "SignalLongName" SG_ 1190 RSrrTrkRawAzimuth6 "Rear Short Range Radar Track Raw Azimuth 6";
BA_ "VNSigAllNodes" SG_ 1190 RSrrTrkRawAzimuth6 1;
BA_ "SignalType" SG_ 1189 RSrrTrkRRate5 "SNM";
BA_ "SignalLongName" SG_ 1189 RSrrTrkRRate5 "Rear Short Range Radar Track Range Rate 5";
BA_ "VNSigAllNodes" SG_ 1189 RSrrTrkRRate5 1;
BA_ "SignalType" SG_ 1189 RSrrTrkAzimuth5 "SNM";
BA_ "SignalLongName" SG_ 1189 RSrrTrkAzimuth5 "Rear Short Range Radar Track Azimuth 5";
BA_ "VNSigAllNodes" SG_ 1189 RSrrTrkAzimuth5 1;
BA_ "SignalType" SG_ 1189 RSrrTrkObjID5 "UNM";
BA_ "SignalLongName" SG_ 1189 RSrrTrkObjID5 "Rear Short Range Radar Track Object ID 5";
BA_ "VNSigAllNodes" SG_ 1189 RSrrTrkObjID5 1;
BA_ "SignalType" SG_ 1189 RSrrTrkObjElevation5 "ENM";
BA_ "SignalLongName" SG_ 1189 RSrrTrkObjElevation5 "Rear Short Range Radar Track Object Elevation 5";
BA_ "VNSigAllNodes" SG_ 1189 RSrrTrkObjElevation5 1;
BA_ "SignalType" SG_ 1189 RSrrTrkDynamProp5 "ENM";
BA_ "SignalLongName" SG_ 1189 RSrrTrkDynamProp5 "Rear Short Range Radar Track Dynamic Property 5";
BA_ "VNSigAllNodes" SG_ 1189 RSrrTrkDynamProp5 1;
BA_ "SignalType" SG_ 1189 RSrrTrkMeasStatus5 "ENM";
BA_ "SignalLongName" SG_ 1189 RSrrTrkMeasStatus5 "Rear Short Range Radar Track Measurement Status 5";
BA_ "VNSigAllNodes" SG_ 1189 RSrrTrkMeasStatus5 1;
BA_ "SignalType" SG_ 1189 RSrrTrkObsRange5 "SNM";
BA_ "SignalLongName" SG_ 1189 RSrrTrkObsRange5 "Rear Short Range Radar Track Observed Range 5";
BA_ "VNSigAllNodes" SG_ 1189 RSrrTrkObsRange5 1;
BA_ "SignalType" SG_ 1189 RSrrTrkRawAzimuth5 "SNM";
BA_ "SignalLongName" SG_ 1189 RSrrTrkRawAzimuth5 "Rear Short Range Radar Track Raw Azimuth 5";
BA_ "VNSigAllNodes" SG_ 1189 RSrrTrkRawAzimuth5 1;
BA_ "SignalType" SG_ 1189 RSrrBurstID5 "UNM";
BA_ "SignalLongName" SG_ 1189 RSrrBurstID5 "Rear Short Range Radar Burst ID 5";
BA_ "VNSigAllNodes" SG_ 1189 RSrrBurstID5 1;
BA_ "SignalType" SG_ 1189 RSrrTrkRange5 "UNM";
BA_ "SignalLongName" SG_ 1189 RSrrTrkRange5 "Rear Short Range Radar Track Range 5";
BA_ "VNSigAllNodes" SG_ 1189 RSrrTrkRange5 1;
BA_ "SignalType" SG_ 1188 RSrrBurstID4 "UNM";
BA_ "SignalLongName" SG_ 1188 RSrrBurstID4 "Rear Short Range Radar Burst ID 4";
BA_ "VNSigAllNodes" SG_ 1188 RSrrBurstID4 1;
BA_ "SignalType" SG_ 1188 RSrrTrkRange4 "UNM";
BA_ "SignalLongName" SG_ 1188 RSrrTrkRange4 "Rear Short Range Radar Track Range 4";
BA_ "VNSigAllNodes" SG_ 1188 RSrrTrkRange4 1;
BA_ "SignalType" SG_ 1188 RSrrTrkRRate4 "SNM";
BA_ "SignalLongName" SG_ 1188 RSrrTrkRRate4 "Rear Short Range Radar Track Range Rate 4";
BA_ "VNSigAllNodes" SG_ 1188 RSrrTrkRRate4 1;
BA_ "SignalType" SG_ 1188 RSrrTrkAzimuth4 "SNM";
BA_ "SignalLongName" SG_ 1188 RSrrTrkAzimuth4 "Rear Short Range Radar Track Azimuth 4";
BA_ "VNSigAllNodes" SG_ 1188 RSrrTrkAzimuth4 1;
BA_ "SignalType" SG_ 1188 RSrrTrkObjID4 "UNM";
BA_ "SignalLongName" SG_ 1188 RSrrTrkObjID4 "Rear Short Range Radar Track Object ID 4";
BA_ "VNSigAllNodes" SG_ 1188 RSrrTrkObjID4 1;
BA_ "SignalType" SG_ 1188 RSrrTrkObjElevation4 "ENM";
BA_ "SignalLongName" SG_ 1188 RSrrTrkObjElevation4 "Rear Short Range Radar Track Object Elevation 4";
BA_ "VNSigAllNodes" SG_ 1188 RSrrTrkObjElevation4 1;
BA_ "SignalType" SG_ 1188 RSrrTrkDynamProp4 "ENM";
BA_ "SignalLongName" SG_ 1188 RSrrTrkDynamProp4 "Rear Short Range Radar Track Dynamic Property 4";
BA_ "VNSigAllNodes" SG_ 1188 RSrrTrkDynamProp4 1;
BA_ "SignalType" SG_ 1188 RSrrTrkMeasStatus4 "ENM";
BA_ "SignalLongName" SG_ 1188 RSrrTrkMeasStatus4 "Rear Short Range Radar Track Measurement Status 4";
BA_ "VNSigAllNodes" SG_ 1188 RSrrTrkMeasStatus4 1;
BA_ "SignalType" SG_ 1188 RSrrTrkObsRange4 "SNM";
BA_ "SignalLongName" SG_ 1188 RSrrTrkObsRange4 "Rear Short Range Radar Track Observed Range 4";
BA_ "VNSigAllNodes" SG_ 1188 RSrrTrkObsRange4 1;
BA_ "SignalType" SG_ 1188 RSrrTrkRawAzimuth4 "SNM";
BA_ "SignalLongName" SG_ 1188 RSrrTrkRawAzimuth4 "Rear Short Range Radar Track Raw Azimuth 4";
BA_ "VNSigAllNodes" SG_ 1188 RSrrTrkRawAzimuth4 1;
BA_ "SignalType" SG_ 1187 RSrrBurstID3 "UNM";
BA_ "SignalLongName" SG_ 1187 RSrrBurstID3 "Rear Short Range Radar Burst ID 3";
BA_ "VNSigAllNodes" SG_ 1187 RSrrBurstID3 1;
BA_ "SignalType" SG_ 1187 RSrrTrkRange3 "UNM";
BA_ "SignalLongName" SG_ 1187 RSrrTrkRange3 "Rear Short Range Radar Track Range 3";
BA_ "VNSigAllNodes" SG_ 1187 RSrrTrkRange3 1;
BA_ "SignalType" SG_ 1187 RSrrTrkRRate3 "SNM";
BA_ "SignalLongName" SG_ 1187 RSrrTrkRRate3 "Rear Short Range Radar Track Range Rate 3";
BA_ "VNSigAllNodes" SG_ 1187 RSrrTrkRRate3 1;
BA_ "SignalType" SG_ 1187 RSrrTrkAzimuth3 "SNM";
BA_ "SignalLongName" SG_ 1187 RSrrTrkAzimuth3 "Rear Short Range Radar Track Azimuth 3";
BA_ "VNSigAllNodes" SG_ 1187 RSrrTrkAzimuth3 1;
BA_ "SignalType" SG_ 1187 RSrrTrkObjID3 "UNM";
BA_ "SignalLongName" SG_ 1187 RSrrTrkObjID3 "Rear Short Range Radar Track Object ID 3";
BA_ "VNSigAllNodes" SG_ 1187 RSrrTrkObjID3 1;
BA_ "SignalType" SG_ 1187 RSrrTrkObjElevation3 "ENM";
BA_ "SignalLongName" SG_ 1187 RSrrTrkObjElevation3 "Rear Short Range Radar Track Object Elevation 3";
BA_ "VNSigAllNodes" SG_ 1187 RSrrTrkObjElevation3 1;
BA_ "SignalType" SG_ 1187 RSrrTrkDynamProp3 "ENM";
BA_ "SignalLongName" SG_ 1187 RSrrTrkDynamProp3 "Rear Short Range Radar Track Dynamic Property 3";
BA_ "VNSigAllNodes" SG_ 1187 RSrrTrkDynamProp3 1;
BA_ "SignalType" SG_ 1187 RSrrTrkMeasStatus3 "ENM";
BA_ "SignalLongName" SG_ 1187 RSrrTrkMeasStatus3 "Rear Short Range Radar Track Measurement Status 3";
BA_ "VNSigAllNodes" SG_ 1187 RSrrTrkMeasStatus3 1;
BA_ "SignalType" SG_ 1187 RSrrTrkObsRange3 "SNM";
BA_ "SignalLongName" SG_ 1187 RSrrTrkObsRange3 "Rear Short Range Radar Track Observed Range 3";
BA_ "VNSigAllNodes" SG_ 1187 RSrrTrkObsRange3 1;
BA_ "SignalType" SG_ 1187 RSrrTrkRawAzimuth3 "SNM";
BA_ "SignalLongName" SG_ 1187 RSrrTrkRawAzimuth3 "Rear Short Range Radar Track Raw Azimuth 3";
BA_ "VNSigAllNodes" SG_ 1187 RSrrTrkRawAzimuth3 1;
BA_ "SignalType" SG_ 1186 RSrrTrkObsRange2 "SNM";
BA_ "SignalLongName" SG_ 1186 RSrrTrkObsRange2 "Rear Short Range Radar Track Observed Range 2";
BA_ "VNSigAllNodes" SG_ 1186 RSrrTrkObsRange2 1;
BA_ "SignalType" SG_ 1186 RSrrTrkRawAzimuth2 "SNM";
BA_ "SignalLongName" SG_ 1186 RSrrTrkRawAzimuth2 "Rear Short Range Radar Track Raw Azimuth 2";
BA_ "VNSigAllNodes" SG_ 1186 RSrrTrkRawAzimuth2 1;
BA_ "SignalType" SG_ 1186 RSrrBurstID2 "UNM";
BA_ "SignalLongName" SG_ 1186 RSrrBurstID2 "Rear Short Range Radar Burst ID 2";
BA_ "VNSigAllNodes" SG_ 1186 RSrrBurstID2 1;
BA_ "SignalType" SG_ 1186 RSrrTrkRange2 "UNM";
BA_ "SignalLongName" SG_ 1186 RSrrTrkRange2 "Rear Short Range Radar Track Range 2";
BA_ "VNSigAllNodes" SG_ 1186 RSrrTrkRange2 1;
BA_ "SignalType" SG_ 1186 RSrrTrkRRate2 "SNM";
BA_ "SignalLongName" SG_ 1186 RSrrTrkRRate2 "Rear Short Range Radar Track Range Rate 2";
BA_ "VNSigAllNodes" SG_ 1186 RSrrTrkRRate2 1;
BA_ "SignalType" SG_ 1186 RSrrTrkAzimuth2 "SNM";
BA_ "SignalLongName" SG_ 1186 RSrrTrkAzimuth2 "Rear Short Range Radar Track Azimuth 2";
BA_ "VNSigAllNodes" SG_ 1186 RSrrTrkAzimuth2 1;
BA_ "SignalType" SG_ 1186 RSrrTrkObjID2 "UNM";
BA_ "SignalLongName" SG_ 1186 RSrrTrkObjID2 "Rear Short Range Radar Track Object ID 2";
BA_ "VNSigAllNodes" SG_ 1186 RSrrTrkObjID2 1;
BA_ "SignalType" SG_ 1186 RSrrTrkObjElevation2 "ENM";
BA_ "SignalLongName" SG_ 1186 RSrrTrkObjElevation2 "Rear Short Range Radar Track Object Elevation 2";
BA_ "VNSigAllNodes" SG_ 1186 RSrrTrkObjElevation2 1;
BA_ "SignalType" SG_ 1186 RSrrTrkDynamProp2 "ENM";
BA_ "SignalLongName" SG_ 1186 RSrrTrkDynamProp2 "Rear Range Radar Track Dynamic Property 2";
BA_ "VNSigAllNodes" SG_ 1186 RSrrTrkDynamProp2 1;
BA_ "SignalType" SG_ 1186 RSrrTrkMeasStatus2 "ENM";
BA_ "SignalLongName" SG_ 1186 RSrrTrkMeasStatus2 "Rear Short Range Radar Track Measurement Status 2";
BA_ "VNSigAllNodes" SG_ 1186 RSrrTrkMeasStatus2 1;
BA_ "SignalType" SG_ 1185 RSrrBurstID1 "UNM";
BA_ "SignalLongName" SG_ 1185 RSrrBurstID1 "Rear Short Range Radar Burst ID 1";
BA_ "VNSigAllNodes" SG_ 1185 RSrrBurstID1 1;
BA_ "SignalType" SG_ 1185 RSrrTrkRange1 "UNM";
BA_ "SignalLongName" SG_ 1185 RSrrTrkRange1 "Rear Short Range Radar Track Range 1";
BA_ "VNSigAllNodes" SG_ 1185 RSrrTrkRange1 1;
BA_ "SignalType" SG_ 1185 RSrrTrkRRate1 "SNM";
BA_ "SignalLongName" SG_ 1185 RSrrTrkRRate1 "Rear Short Range Radar Track Range Rate 1";
BA_ "VNSigAllNodes" SG_ 1185 RSrrTrkRRate1 1;
BA_ "SignalType" SG_ 1185 RSrrTrkAzimuth1 "SNM";
BA_ "SignalLongName" SG_ 1185 RSrrTrkAzimuth1 "Rear Short Range Radar Track Azimuth 1";
BA_ "VNSigAllNodes" SG_ 1185 RSrrTrkAzimuth1 1;
BA_ "SignalType" SG_ 1185 RSrrTrkObjID1 "UNM";
BA_ "SignalLongName" SG_ 1185 RSrrTrkObjID1 "Rear Short Range Radar Track Object ID 1";
BA_ "VNSigAllNodes" SG_ 1185 RSrrTrkObjID1 1;
BA_ "SignalType" SG_ 1185 RSrrTrkObjElevation1 "ENM";
BA_ "SignalLongName" SG_ 1185 RSrrTrkObjElevation1 "Rear Short Range Radar Track Object Elevation 1";
BA_ "VNSigAllNodes" SG_ 1185 RSrrTrkObjElevation1 1;
BA_ "SignalType" SG_ 1185 RSrrTrkDynamProp1 "ENM";
BA_ "SignalLongName" SG_ 1185 RSrrTrkDynamProp1 "Rear Short Range Radar Track Dynamic Property 1";
BA_ "VNSigAllNodes" SG_ 1185 RSrrTrkDynamProp1 1;
BA_ "SignalType" SG_ 1185 RSrrTrkMeasStatus1 "ENM";
BA_ "SignalLongName" SG_ 1185 RSrrTrkMeasStatus1 "Rear Short Range Radar Track Measurement Status 1";
BA_ "VNSigAllNodes" SG_ 1185 RSrrTrkMeasStatus1 1;
BA_ "SignalType" SG_ 1185 RSrrTrkObsRange1 "SNM";
BA_ "SignalLongName" SG_ 1185 RSrrTrkObsRange1 "Rear Short Range Radar Track Observed Range 1";
BA_ "VNSigAllNodes" SG_ 1185 RSrrTrkObsRange1 1;
BA_ "SignalType" SG_ 1185 RSrrTrkRawAzimuth1 "SNM";
BA_ "SignalLongName" SG_ 1185 RSrrTrkRawAzimuth1 "Rear Short Range Radar Track Raw Azimuth 1";
BA_ "VNSigAllNodes" SG_ 1185 RSrrTrkRawAzimuth1 1;
BA_ "SignalType" SG_ 1184 RSRRSnstvFltPrsntInt "BLN";
BA_ "PacketOrder" SG_ 1184 RSRRSnstvFltPrsntInt 7;
BA_ "SignalLongName" SG_ 1184 RSRRSnstvFltPrsntInt "Rear Short Range Radar Sensitivity Fault Present, Internal";
BA_ "VNSigAllNodes" SG_ 1184 RSRRSnstvFltPrsntInt 1;
BA_ "SignalType" SG_ 1184 RSRRPlntAlgnInProc "BLN";
BA_ "PacketOrder" SG_ 1184 RSRRPlntAlgnInProc 10;
BA_ "SignalLongName" SG_ 1184 RSRRPlntAlgnInProc "Rear Short Range Radar Plant Alignment in Process";
BA_ "VNSigAllNodes" SG_ 1184 RSRRPlntAlgnInProc 1;
BA_ "SignalType" SG_ 1184 RSRRMsalgnYawRt "BLN";
BA_ "PacketOrder" SG_ 1184 RSRRMsalgnYawRt 16;
BA_ "SignalLongName" SG_ 1184 RSRRMsalgnYawRt "Rear Short Range Radar Misalignment Yaw Right";
BA_ "VNSigAllNodes" SG_ 1184 RSRRMsalgnYawRt 1;
BA_ "SignalType" SG_ 1184 RSRRMsalgnYawLt "BLN";
BA_ "PacketOrder" SG_ 1184 RSRRMsalgnYawLt 17;
BA_ "SignalLongName" SG_ 1184 RSRRMsalgnYawLt "Rear Short Range Radar Misalignment Yaw Left";
BA_ "VNSigAllNodes" SG_ 1184 RSRRMsalgnYawLt 1;
BA_ "SignalType" SG_ 1184 RSRRMsalgnRllRt "BLN";
BA_ "PacketOrder" SG_ 1184 RSRRMsalgnRllRt 12;
BA_ "SignalLongName" SG_ 1184 RSRRMsalgnRllRt "Rear Short Range Radar Misalignment Roll Right";
BA_ "VNSigAllNodes" SG_ 1184 RSRRMsalgnRllRt 1;
BA_ "SignalType" SG_ 1184 RSRRMsalgnRllLt "BLN";
BA_ "PacketOrder" SG_ 1184 RSRRMsalgnRllLt 13;
BA_ "SignalLongName" SG_ 1184 RSRRMsalgnRllLt "Rear Short Range Radar Misalignment Roll Left";
BA_ "VNSigAllNodes" SG_ 1184 RSRRMsalgnRllLt 1;
BA_ "SignalType" SG_ 1184 RSRRMsalgnPtchUp "BLN";
BA_ "PacketOrder" SG_ 1184 RSRRMsalgnPtchUp 15;
BA_ "SignalLongName" SG_ 1184 RSRRMsalgnPtchUp "Rear Short Range Radar Misalignment Pitch Up";
BA_ "VNSigAllNodes" SG_ 1184 RSRRMsalgnPtchUp 1;
BA_ "SignalType" SG_ 1184 RSRRMsalgnPtchDn "BLN";
BA_ "PacketOrder" SG_ 1184 RSRRMsalgnPtchDn 14;
BA_ "SignalLongName" SG_ 1184 RSRRMsalgnPtchDn "Rear Short Range Radar Misalignment Pitch Down";
BA_ "VNSigAllNodes" SG_ 1184 RSRRMsalgnPtchDn 1;
BA_ "SignalType" SG_ 1184 RSRRInitDiagCmplt "BLN";
BA_ "PacketOrder" SG_ 1184 RSRRInitDiagCmplt 23;
BA_ "SignalLongName" SG_ 1184 RSRRInitDiagCmplt "Rear Short Range Radar Initialization Diagnostics Successfully Completed";
BA_ "VNSigAllNodes" SG_ 1184 RSRRInitDiagCmplt 1;
BA_ "SignalType" SG_ 1184 RSRRHWFltPrsntInt "BLN";
BA_ "PacketOrder" SG_ 1184 RSRRHWFltPrsntInt 6;
BA_ "SignalLongName" SG_ 1184 RSRRHWFltPrsntInt "Rear Short Range Radar Hardware Fault Present, Internal";
BA_ "VNSigAllNodes" SG_ 1184 RSRRHWFltPrsntInt 1;
BA_ "SignalType" SG_ 1184 RSRRExtIntrfrnc "BLN";
BA_ "PacketOrder" SG_ 1184 RSRRExtIntrfrnc 11;
BA_ "SignalLongName" SG_ 1184 RSRRExtIntrfrnc "Rear Short Range Radar External Interference";
BA_ "VNSigAllNodes" SG_ 1184 RSRRExtIntrfrnc 1;
BA_ "SignalType" SG_ 1184 RSRRDiagSpare "BLN";
BA_ "PacketOrder" SG_ 1184 RSRRDiagSpare 1;
BA_ "SignalLongName" SG_ 1184 RSRRDiagSpare "Rear Short Range Radar Diagnostic Spare";
BA_ "VNSigAllNodes" SG_ 1184 RSRRDiagSpare 1;
BA_ "SignalType" SG_ 1184 RSRRCANSgnlSpvFld "BLN";
BA_ "PacketOrder" SG_ 1184 RSRRCANSgnlSpvFld 2;
BA_ "SignalLongName" SG_ 1184 RSRRCANSgnlSpvFld "Rear Short Range Radar CAN Signal Supervision Failed";
BA_ "VNSigAllNodes" SG_ 1184 RSRRCANSgnlSpvFld 1;
BA_ "SignalType" SG_ 1184 RSRRCANRxErr "BLN";
BA_ "PacketOrder" SG_ 1184 RSRRCANRxErr 3;
BA_ "SignalLongName" SG_ 1184 RSRRCANRxErr "Rear Short Range Radar CAN Rx Error";
BA_ "VNSigAllNodes" SG_ 1184 RSRRCANRxErr 1;
BA_ "SignalType" SG_ 1184 RSRRCANIDAddrsUnsbl "BLN";
BA_ "PacketOrder" SG_ 1184 RSRRCANIDAddrsUnsbl 4;
BA_ "SignalLongName" SG_ 1184 RSRRCANIDAddrsUnsbl "Rear Short Range Radar CAN ID Address Unstable";
BA_ "VNSigAllNodes" SG_ 1184 RSRRCANIDAddrsUnsbl 1;
BA_ "SignalType" SG_ 1184 RSRRAntTngFltPrsnt "BLN";
BA_ "PacketOrder" SG_ 1184 RSRRAntTngFltPrsnt 5;
BA_ "SignalLongName" SG_ 1184 RSRRAntTngFltPrsnt "Rear Short Range Radar Antenna Tuning Fault Present";
BA_ "VNSigAllNodes" SG_ 1184 RSRRAntTngFltPrsnt 1;
BA_ "SignalType" SG_ 1184 RSRRAmbTmpOutRngLw "BLN";
BA_ "PacketOrder" SG_ 1184 RSRRAmbTmpOutRngLw 21;
BA_ "SignalLongName" SG_ 1184 RSRRAmbTmpOutRngLw "Rear Short Range Radar Ambient Temperature Out of Range Low";
BA_ "VNSigAllNodes" SG_ 1184 RSRRAmbTmpOutRngLw 1;
BA_ "SignalType" SG_ 1184 RSRRAmbTmpOutRngHi "BLN";
BA_ "PacketOrder" SG_ 1184 RSRRAmbTmpOutRngHi 22;
BA_ "SignalLongName" SG_ 1184 RSRRAmbTmpOutRngHi "Rear Short Range Radar Ambient Temperature Out of Range High";
BA_ "VNSigAllNodes" SG_ 1184 RSRRAmbTmpOutRngHi 1;
BA_ "SignalType" SG_ 1184 RSRRAlgnFltPrsnt "BLN";
BA_ "PacketOrder" SG_ 1184 RSRRAlgnFltPrsnt 8;
BA_ "SignalLongName" SG_ 1184 RSRRAlgnFltPrsnt "Rear Short Range Radar Alignment Fault Present";
BA_ "VNSigAllNodes" SG_ 1184 RSRRAlgnFltPrsnt 1;
BA_ "SignalType" SG_ 1184 RSRRVltgOutRngLo "BLN";
BA_ "PacketOrder" SG_ 1184 RSRRVltgOutRngLo 19;
BA_ "SignalLongName" SG_ 1184 RSRRVltgOutRngLo "Rear Short Range Radar Voltage Out Of Range Low";
BA_ "VNSigAllNodes" SG_ 1184 RSRRVltgOutRngLo 1;
BA_ "SignalType" SG_ 1184 RSRRVltgOutRngHi "BLN";
BA_ "PacketOrder" SG_ 1184 RSRRVltgOutRngHi 20;
BA_ "SignalLongName" SG_ 1184 RSRRVltgOutRngHi "Rear Short Range Radar Voltage out of Range High";
BA_ "VNSigAllNodes" SG_ 1184 RSRRVltgOutRngHi 1;
BA_ "SignalType" SG_ 1184 RSRRSvcAlgnInPrcs "BLN";
BA_ "PacketOrder" SG_ 1184 RSRRSvcAlgnInPrcs 9;
BA_ "SignalLongName" SG_ 1184 RSRRSvcAlgnInPrcs "Rear Short Range Radar Service Alignment in Process";
BA_ "VNSigAllNodes" SG_ 1184 RSRRSvcAlgnInPrcs 1;
BA_ "SignalType" SG_ 1184 RSRRSnsrBlckd "BLN";
BA_ "PacketOrder" SG_ 1184 RSRRSnsrBlckd 18;
BA_ "SignalLongName" SG_ 1184 RSRRSnsrBlckd "Rear Short Range Radar Sensor Blocked";
BA_ "VNSigAllNodes" SG_ 1184 RSRRSnsrBlckd 1;
BA_ "SignalType" SG_ 1184 RSRRNumValidTargets "UNM";
BA_ "SignalLongName" SG_ 1184 RSRRNumValidTargets "Rear Short Range Radar Number of Valid Targets";
BA_ "VNSigAllNodes" SG_ 1184 RSRRNumValidTargets 1;
BA_ "SignalType" SG_ 1184 RSrrRollingCnt "UNM";
BA_ "SignalLongName" SG_ 1184 RSrrRollingCnt "Rear Short Range Radar Rolling Count";
BA_ "VNSigAllNodes" SG_ 1184 RSrrRollingCnt 1;
BA_ "SignalType" SG_ 1184 RSRRModeCmdFdbk "ENM";
BA_ "SignalLongName" SG_ 1184 RSRRModeCmdFdbk "Rear Short Range Radar Mode Command Feedback";
BA_ "VNSigAllNodes" SG_ 1184 RSRRModeCmdFdbk 1;
BA_ "SignalType" SG_ 1184 RSrrTimeStampV "ENM";
BA_ "SignalLongName" SG_ 1184 RSrrTimeStampV "Rear Short Range Radar Time Stamp Validity";
BA_ "VNSigAllNodes" SG_ 1184 RSrrTimeStampV 1;
BA_ "SignalType" SG_ 1184 RSrrTimeStamp "UNM";
BA_ "SignalLongName" SG_ 1184 RSrrTimeStamp "Rear Short Range Radar Time Stamp";
BA_ "VNSigAllNodes" SG_ 1184 RSrrTimeStamp 1;
BA_ "SignalType" SG_ 1184 RSrrBurstChecksum "UNM";
BA_ "SignalLongName" SG_ 1184 RSrrBurstChecksum "Rear Short Range Radar Burst Checksum";
BA_ "VNSigAllNodes" SG_ 1184 RSrrBurstChecksum 1;
BA_ "SignalType" SG_ 1151 FLRRAddInfo5BurstID "UNM";
BA_ "SignalLongName" SG_ 1151 FLRRAddInfo5BurstID "Front Long Range Radar Additional Information 5 Burst ID";
BA_ "VNSigAllNodes" SG_ 1151 FLRRAddInfo5BurstID 1;
BA_ "SignalType" SG_ 1151 FrtRdrRdEdgLtLatRdEdgDst "SNM";
BA_ "SignalLongName" SG_ 1151 FrtRdrRdEdgLtLatRdEdgDst "Front Radar Road Edge Left Lateral Road Edge Distance";
BA_ "VNSigAllNodes" SG_ 1151 FrtRdrRdEdgLtLatRdEdgDst 1;
BA_ "SignalType" SG_ 1151 FrtRdrRdEdgLtCrvtPrvDst "UNM";
BA_ "SignalLongName" SG_ 1151 FrtRdrRdEdgLtCrvtPrvDst "Front Radar Road Edge Left Curvature Preview Distance";
BA_ "VNSigAllNodes" SG_ 1151 FrtRdrRdEdgLtCrvtPrvDst 1;
BA_ "SignalType" SG_ 1151 FrtRdrRdEdgLtTanHdgAngV "ENM";
BA_ "SignalLongName" SG_ 1151 FrtRdrRdEdgLtTanHdgAngV "Front Radar Road Edge Left Tangens Heading Angle Validity";
BA_ "VNSigAllNodes" SG_ 1151 FrtRdrRdEdgLtTanHdgAngV 1;
BA_ "SignalType" SG_ 1151 FrtRdrRdEdgLtTanHdgAng "SNM";
BA_ "SignalLongName" SG_ 1151 FrtRdrRdEdgLtTanHdgAng "Front Radar Road Edge Left Tangens Heading Angle";
BA_ "VNSigAllNodes" SG_ 1151 FrtRdrRdEdgLtTanHdgAng 1;
BA_ "SignalType" SG_ 1151 FrtRdrRdEdgLtCrvtV "ENM";
BA_ "SignalLongName" SG_ 1151 FrtRdrRdEdgLtCrvtV "Front Radar Road Edge Left Curvature Validity";
BA_ "VNSigAllNodes" SG_ 1151 FrtRdrRdEdgLtCrvtV 1;
BA_ "SignalType" SG_ 1151 FrtRdrRdEdgLtCrvtGradV "ENM";
BA_ "SignalLongName" SG_ 1151 FrtRdrRdEdgLtCrvtGradV "Front Radar Road Edge Left Curvature Gradient Validity";
BA_ "VNSigAllNodes" SG_ 1151 FrtRdrRdEdgLtCrvtGradV 1;
BA_ "SignalType" SG_ 1151 FrtRdrRdEdgLtCrvtGrad "SNM";
BA_ "SignalLongName" SG_ 1151 FrtRdrRdEdgLtCrvtGrad "Front Radar Road Edge Left Curvature Gradient";
BA_ "VNSigAllNodes" SG_ 1151 FrtRdrRdEdgLtCrvtGrad 1;
BA_ "SignalType" SG_ 1151 FrtRdrRdEdgLtCrvtConf "UNM";
BA_ "SignalLongName" SG_ 1151 FrtRdrRdEdgLtCrvtConf "Front Radar Road Edge Left Curvature Confidence";
BA_ "VNSigAllNodes" SG_ 1151 FrtRdrRdEdgLtCrvtConf 1;
BA_ "SignalType" SG_ 1151 FrtRdrRdEdgLtCrvt "SNM";
BA_ "SignalLongName" SG_ 1151 FrtRdrRdEdgLtCrvt "Front Radar Road Edge Left Curvature";
BA_ "VNSigAllNodes" SG_ 1151 FrtRdrRdEdgLtCrvt 1;
BA_ "SignalType" SG_ 1150 FLRRAddInfo4BurstID "UNM";
BA_ "SignalLongName" SG_ 1150 FLRRAddInfo4BurstID "Front Long Range Radar Additional Information 4 Burst ID";
BA_ "VNSigAllNodes" SG_ 1150 FLRRAddInfo4BurstID 1;
BA_ "SignalType" SG_ 1150 FrtRdrRdEdgRtLatRdEdgDst "SNM";
BA_ "SignalLongName" SG_ 1150 FrtRdrRdEdgRtLatRdEdgDst "Front Radar Road Edge Right Lateral Road Edge Distance";
BA_ "VNSigAllNodes" SG_ 1150 FrtRdrRdEdgRtLatRdEdgDst 1;
BA_ "SignalType" SG_ 1150 FrtRdrRdEdgRtCrvtPrvDst "UNM";
BA_ "SignalLongName" SG_ 1150 FrtRdrRdEdgRtCrvtPrvDst "Front Radar Road Edge Right Curvature Preview Distance";
BA_ "VNSigAllNodes" SG_ 1150 FrtRdrRdEdgRtCrvtPrvDst 1;
BA_ "SignalType" SG_ 1150 FrtRdrRdEdgRtTanHdgAngV "ENM";
BA_ "SignalLongName" SG_ 1150 FrtRdrRdEdgRtTanHdgAngV "Front Radar Road Edge Right Tangens Heading Angle Validity";
BA_ "VNSigAllNodes" SG_ 1150 FrtRdrRdEdgRtTanHdgAngV 1;
BA_ "SignalType" SG_ 1150 FrtRdrRdEdgRtTanHdgAng "SNM";
BA_ "SignalLongName" SG_ 1150 FrtRdrRdEdgRtTanHdgAng "Front Radar Road Edge Right Tangens Heading Angle";
BA_ "VNSigAllNodes" SG_ 1150 FrtRdrRdEdgRtTanHdgAng 1;
BA_ "SignalType" SG_ 1150 FrtRdrRdEdgRtCrvtV "ENM";
BA_ "SignalLongName" SG_ 1150 FrtRdrRdEdgRtCrvtV "Front Radar Road Edge Right Curvature Validity";
BA_ "VNSigAllNodes" SG_ 1150 FrtRdrRdEdgRtCrvtV 1;
BA_ "SignalType" SG_ 1150 FrtRdrRdEdgRtCrvtGradV "ENM";
BA_ "SignalLongName" SG_ 1150 FrtRdrRdEdgRtCrvtGradV "Front Radar Road Edge Right Curvature Gradient Validity";
BA_ "VNSigAllNodes" SG_ 1150 FrtRdrRdEdgRtCrvtGradV 1;
BA_ "SignalType" SG_ 1150 FrtRdrRdEdgRtCrvtGrad "SNM";
BA_ "SignalLongName" SG_ 1150 FrtRdrRdEdgRtCrvtGrad "Front Radar Road Edge Right Curvature Gradient";
BA_ "VNSigAllNodes" SG_ 1150 FrtRdrRdEdgRtCrvtGrad 1;
BA_ "SignalType" SG_ 1150 FrtRdrRdEdgRtCrvtConf "UNM";
BA_ "SignalLongName" SG_ 1150 FrtRdrRdEdgRtCrvtConf "Front Radar Road Edge Right Curvature Confidence";
BA_ "VNSigAllNodes" SG_ 1150 FrtRdrRdEdgRtCrvtConf 1;
BA_ "SignalType" SG_ 1150 FrtRdrRdEdgRtCrvt "SNM";
BA_ "SignalLongName" SG_ 1150 FrtRdrRdEdgRtCrvt "Front Radar Road Edge Right Curvature";
BA_ "VNSigAllNodes" SG_ 1150 FrtRdrRdEdgRtCrvt 1;
BA_ "SignalType" SG_ 1149 FLRRTrk20AzmthRate "SNM";
BA_ "SignalLongName" SG_ 1149 FLRRTrk20AzmthRate "Front Long Range Radar Track 20 Azimuth Rate";
BA_ "VNSigAllNodes" SG_ 1149 FLRRTrk20AzmthRate 1;
BA_ "SignalType" SG_ 1149 FLRRTrk19AzmthRate "SNM";
BA_ "SignalLongName" SG_ 1149 FLRRTrk19AzmthRate "Front Long Range Radar Track 19 Azimuth Rate";
BA_ "VNSigAllNodes" SG_ 1149 FLRRTrk19AzmthRate 1;
BA_ "SignalType" SG_ 1149 FLRRTrk18AzmthRate "SNM";
BA_ "SignalLongName" SG_ 1149 FLRRTrk18AzmthRate "Front Long Range Radar Track 18 Azimuth Rate";
BA_ "VNSigAllNodes" SG_ 1149 FLRRTrk18AzmthRate 1;
BA_ "SignalType" SG_ 1149 FLRRTrk17AzmthRate "SNM";
BA_ "SignalLongName" SG_ 1149 FLRRTrk17AzmthRate "Front Long Range Radar Track 17 Azimuth Rate";
BA_ "VNSigAllNodes" SG_ 1149 FLRRTrk17AzmthRate 1;
BA_ "SignalType" SG_ 1149 FLRRTrk16AzmthRate "SNM";
BA_ "SignalLongName" SG_ 1149 FLRRTrk16AzmthRate "Front Long Range Radar Track 16 Azimuth Rate";
BA_ "VNSigAllNodes" SG_ 1149 FLRRTrk16AzmthRate 1;
BA_ "SignalType" SG_ 1149 FLRRAzRtInf4BurstID "UNM";
BA_ "SignalLongName" SG_ 1149 FLRRAzRtInf4BurstID "Front Long Range Radar Azimuth Rate Info 4 Burst ID";
BA_ "VNSigAllNodes" SG_ 1149 FLRRAzRtInf4BurstID 1;
BA_ "SignalType" SG_ 1148 FLRRTrk15AzmthRate "SNM";
BA_ "SignalLongName" SG_ 1148 FLRRTrk15AzmthRate "Front Long Range Radar Track 15 Azimuth Rate";
BA_ "VNSigAllNodes" SG_ 1148 FLRRTrk15AzmthRate 1;
BA_ "SignalType" SG_ 1148 FLRRTrk14AzmthRate "SNM";
BA_ "SignalLongName" SG_ 1148 FLRRTrk14AzmthRate "Front Long Range Radar Track 14 Azimuth Rate";
BA_ "VNSigAllNodes" SG_ 1148 FLRRTrk14AzmthRate 1;
BA_ "SignalType" SG_ 1148 FLRRTrk13AzmthRate "SNM";
BA_ "SignalLongName" SG_ 1148 FLRRTrk13AzmthRate "Front Long Range Radar Track 13 Azimuth Rate";
BA_ "VNSigAllNodes" SG_ 1148 FLRRTrk13AzmthRate 1;
BA_ "SignalType" SG_ 1148 FLRRTrk12AzmthRate "SNM";
BA_ "SignalLongName" SG_ 1148 FLRRTrk12AzmthRate "Front Long Range Radar Track 12 Azimuth Rate";
BA_ "VNSigAllNodes" SG_ 1148 FLRRTrk12AzmthRate 1;
BA_ "SignalType" SG_ 1148 FLRRTrk11AzmthRate "SNM";
BA_ "SignalLongName" SG_ 1148 FLRRTrk11AzmthRate "Front Long Range Radar Track 11 Azimuth Rate";
BA_ "VNSigAllNodes" SG_ 1148 FLRRTrk11AzmthRate 1;
BA_ "SignalType" SG_ 1148 FLRRAzRtInf3BurstID "UNM";
BA_ "SignalLongName" SG_ 1148 FLRRAzRtInf3BurstID "Front Long Range Radar Azimuth Rate Info 3 Burst ID";
BA_ "VNSigAllNodes" SG_ 1148 FLRRAzRtInf3BurstID 1;
BA_ "SignalType" SG_ 1147 FLRRTrk10AzmthRate "SNM";
BA_ "SignalLongName" SG_ 1147 FLRRTrk10AzmthRate "Front Long Range Radar Track 10 Azimuth Rate";
BA_ "VNSigAllNodes" SG_ 1147 FLRRTrk10AzmthRate 1;
BA_ "SignalType" SG_ 1147 FLRRAzRtInf2BurstID "UNM";
BA_ "SignalLongName" SG_ 1147 FLRRAzRtInf2BurstID "Front Long Range Radar Azimuth Rate Info 2 Burst ID";
BA_ "VNSigAllNodes" SG_ 1147 FLRRAzRtInf2BurstID 1;
BA_ "SignalType" SG_ 1147 FLRRTrk9AzmthRate "SNM";
BA_ "SignalLongName" SG_ 1147 FLRRTrk9AzmthRate "Front Long Range Radar Track 9 Azimuth Rate";
BA_ "VNSigAllNodes" SG_ 1147 FLRRTrk9AzmthRate 1;
BA_ "SignalType" SG_ 1147 FLRRTrk8AzmthRate "SNM";
BA_ "SignalLongName" SG_ 1147 FLRRTrk8AzmthRate "Front Long Range Radar Track 8 Azimuth Rate";
BA_ "VNSigAllNodes" SG_ 1147 FLRRTrk8AzmthRate 1;
BA_ "SignalType" SG_ 1147 FLRRTrk7AzmthRate "SNM";
BA_ "SignalLongName" SG_ 1147 FLRRTrk7AzmthRate "Front Long Range Radar Track 7 Azimuth Rate";
BA_ "VNSigAllNodes" SG_ 1147 FLRRTrk7AzmthRate 1;
BA_ "SignalType" SG_ 1147 FLRRTrk6AzmthRate "SNM";
BA_ "SignalLongName" SG_ 1147 FLRRTrk6AzmthRate "Front Long Range Radar Track 6 Azimuth Rate";
BA_ "VNSigAllNodes" SG_ 1147 FLRRTrk6AzmthRate 1;
BA_ "SignalType" SG_ 1146 FLRRTrk4AzmthRate "SNM";
BA_ "SignalLongName" SG_ 1146 FLRRTrk4AzmthRate "Front Long Range Radar Track 4 Azimuth Rate";
BA_ "VNSigAllNodes" SG_ 1146 FLRRTrk4AzmthRate 1;
BA_ "SignalType" SG_ 1146 FLRRTrk3AzmthRate "SNM";
BA_ "SignalLongName" SG_ 1146 FLRRTrk3AzmthRate "Front Long Range Radar Track 3 Azimuth Rate";
BA_ "VNSigAllNodes" SG_ 1146 FLRRTrk3AzmthRate 1;
BA_ "SignalType" SG_ 1146 FLRRTrk2AzmthRate "SNM";
BA_ "SignalLongName" SG_ 1146 FLRRTrk2AzmthRate "Front Long Range Radar Track 2 Azimuth Rate";
BA_ "VNSigAllNodes" SG_ 1146 FLRRTrk2AzmthRate 1;
BA_ "SignalType" SG_ 1146 FLRRTrk1AzmthRate "SNM";
BA_ "SignalLongName" SG_ 1146 FLRRTrk1AzmthRate "Front Long Range Radar Track 1 Azimuth Rate";
BA_ "VNSigAllNodes" SG_ 1146 FLRRTrk1AzmthRate 1;
BA_ "SignalType" SG_ 1146 FLRRAzRtInf1BurstID "UNM";
BA_ "SignalLongName" SG_ 1146 FLRRAzRtInf1BurstID "Front Long Range Radar Azimuth Rate Info 1 Burst ID";
BA_ "VNSigAllNodes" SG_ 1146 FLRRAzRtInf1BurstID 1;
BA_ "SignalType" SG_ 1146 FLRRTrk5AzmthRate "SNM";
BA_ "SignalLongName" SG_ 1146 FLRRTrk5AzmthRate "Front Long Range Radar Track 5 Azimuth Rate";
BA_ "VNSigAllNodes" SG_ 1146 FLRRTrk5AzmthRate 1;
BA_ "SignalType" SG_ 1143 FLRRAddInfo3BurstID "UNM";
BA_ "SignalLongName" SG_ 1143 FLRRAddInfo3BurstID "Front Long Range Radar Additional Information 3 Burst ID";
BA_ "VNSigAllNodes" SG_ 1143 FLRRAddInfo3BurstID 1;
BA_ "SignalType" SG_ 1143 FLRRTrk20ObstTypeConf "UNM";
BA_ "SignalLongName" SG_ 1143 FLRRTrk20ObstTypeConf "Front Long Range Radar Obstacle Type Confirmation Track 20";
BA_ "VNSigAllNodes" SG_ 1143 FLRRTrk20ObstTypeConf 1;
BA_ "SignalType" SG_ 1143 FLRRTrk20ObstType "ENM";
BA_ "SignalLongName" SG_ 1143 FLRRTrk20ObstType "Front Long Range Radar Obstacle Type Track 20";
BA_ "VNSigAllNodes" SG_ 1143 FLRRTrk20ObstType 1;
BA_ "SignalType" SG_ 1143 FLRRTrk19ObstTypeConf "UNM";
BA_ "SignalLongName" SG_ 1143 FLRRTrk19ObstTypeConf "Front Long Range Radar Obstacle Type Confirmation Track 19";
BA_ "VNSigAllNodes" SG_ 1143 FLRRTrk19ObstTypeConf 1;
BA_ "SignalType" SG_ 1143 FLRRTrk19ObstType "ENM";
BA_ "SignalLongName" SG_ 1143 FLRRTrk19ObstType "Front Long Range Radar Obstacle Type Track 19";
BA_ "VNSigAllNodes" SG_ 1143 FLRRTrk19ObstType 1;
BA_ "SignalType" SG_ 1143 FLRRTrk18ObstTypeConf "UNM";
BA_ "SignalLongName" SG_ 1143 FLRRTrk18ObstTypeConf "Front Long Range Radar Obstacle Type Confirmation Track 18";
BA_ "VNSigAllNodes" SG_ 1143 FLRRTrk18ObstTypeConf 1;
BA_ "SignalType" SG_ 1143 FLRRTrk18ObstType "ENM";
BA_ "SignalLongName" SG_ 1143 FLRRTrk18ObstType "Front Long Range Radar Obstacle Type Track 18";
BA_ "VNSigAllNodes" SG_ 1143 FLRRTrk18ObstType 1;
BA_ "SignalType" SG_ 1143 FLRRTrk17ObstTypeConf "UNM";
BA_ "SignalLongName" SG_ 1143 FLRRTrk17ObstTypeConf "Front Long Range Radar Obstacle Type Confirmation Track 17";
BA_ "VNSigAllNodes" SG_ 1143 FLRRTrk17ObstTypeConf 1;
BA_ "SignalType" SG_ 1143 FLRRTrk17ObstType "ENM";
BA_ "SignalLongName" SG_ 1143 FLRRTrk17ObstType "Front Long Range Radar Obstacle Type Track 17";
BA_ "VNSigAllNodes" SG_ 1143 FLRRTrk17ObstType 1;
BA_ "SignalType" SG_ 1143 FLRRTrk16ObstTypeConf "UNM";
BA_ "SignalLongName" SG_ 1143 FLRRTrk16ObstTypeConf "Front Long Range Radar Obstacle Type Confirmation Track 16";
BA_ "VNSigAllNodes" SG_ 1143 FLRRTrk16ObstTypeConf 1;
BA_ "SignalType" SG_ 1143 FLRRTrk16ObstType "ENM";
BA_ "SignalLongName" SG_ 1143 FLRRTrk16ObstType "Front Long Range Radar Obstacle Type Track 16";
BA_ "VNSigAllNodes" SG_ 1143 FLRRTrk16ObstType 1;
BA_ "SignalType" SG_ 1143 FLRRTrk15ObstTypeConf "UNM";
BA_ "SignalLongName" SG_ 1143 FLRRTrk15ObstTypeConf "Front Long Range Radar Obstacle Type Confirmation Track 15";
BA_ "VNSigAllNodes" SG_ 1143 FLRRTrk15ObstTypeConf 1;
BA_ "SignalType" SG_ 1143 FLRRTrk15ObstType "ENM";
BA_ "SignalLongName" SG_ 1143 FLRRTrk15ObstType "Front Long Range Radar Obstacle Type Track 15";
BA_ "VNSigAllNodes" SG_ 1143 FLRRTrk15ObstType 1;
BA_ "SignalType" SG_ 1143 FLRRTrk14ObstTypeConf "UNM";
BA_ "SignalLongName" SG_ 1143 FLRRTrk14ObstTypeConf "Front Long Range Radar Obstacle Type Confirmation Track 14";
BA_ "VNSigAllNodes" SG_ 1143 FLRRTrk14ObstTypeConf 1;
BA_ "SignalType" SG_ 1143 FLRRTrk14ObstType "ENM";
BA_ "SignalLongName" SG_ 1143 FLRRTrk14ObstType "Front Long Range Radar Obstacle Type Track 14";
BA_ "VNSigAllNodes" SG_ 1143 FLRRTrk14ObstType 1;
BA_ "SignalType" SG_ 1143 FLRRTrk13ObstType "ENM";
BA_ "SignalLongName" SG_ 1143 FLRRTrk13ObstType "Front Long Range Radar Obstacle Type Track 13";
BA_ "VNSigAllNodes" SG_ 1143 FLRRTrk13ObstType 1;
BA_ "SignalType" SG_ 1142 FLRRAddInfo2BurstID "UNM";
BA_ "SignalLongName" SG_ 1142 FLRRAddInfo2BurstID "Front Long Range Radar Additional Information 2 Burst ID";
BA_ "VNSigAllNodes" SG_ 1142 FLRRAddInfo2BurstID 1;
BA_ "SignalType" SG_ 1142 FLRRTrk13ObstTypeConf "UNM";
BA_ "SignalLongName" SG_ 1142 FLRRTrk13ObstTypeConf "Front Long Range Radar Obstacle Type Confirmation Track 13";
BA_ "VNSigAllNodes" SG_ 1142 FLRRTrk13ObstTypeConf 1;
BA_ "SignalType" SG_ 1142 FLRRTrk12ObstTypeConf "UNM";
BA_ "SignalLongName" SG_ 1142 FLRRTrk12ObstTypeConf "Front Long Range Radar Obstacle Type Confirmation Track 12";
BA_ "VNSigAllNodes" SG_ 1142 FLRRTrk12ObstTypeConf 1;
BA_ "SignalType" SG_ 1142 FLRRTrk12ObstType "ENM";
BA_ "SignalLongName" SG_ 1142 FLRRTrk12ObstType "Front Long Range Radar Obstacle Type Track 12";
BA_ "VNSigAllNodes" SG_ 1142 FLRRTrk12ObstType 1;
BA_ "SignalType" SG_ 1142 FLRRTrk11ObstTypeConf "UNM";
BA_ "SignalLongName" SG_ 1142 FLRRTrk11ObstTypeConf "Front Long Range Radar Obstacle Type Confirmation Track 11";
BA_ "VNSigAllNodes" SG_ 1142 FLRRTrk11ObstTypeConf 1;
BA_ "SignalType" SG_ 1142 FLRRTrk11ObstType "ENM";
BA_ "SignalLongName" SG_ 1142 FLRRTrk11ObstType "Front Long Range Radar Obstacle Type Track 11";
BA_ "VNSigAllNodes" SG_ 1142 FLRRTrk11ObstType 1;
BA_ "SignalType" SG_ 1142 FLRRTrk10ObstTypeConf "UNM";
BA_ "SignalLongName" SG_ 1142 FLRRTrk10ObstTypeConf "Front Long Range Radar Obstacle Type Confirmation Track 10";
BA_ "VNSigAllNodes" SG_ 1142 FLRRTrk10ObstTypeConf 1;
BA_ "SignalType" SG_ 1142 FLRRTrk10ObstType "ENM";
BA_ "SignalLongName" SG_ 1142 FLRRTrk10ObstType "Front Long Range Radar Obstacle Type Track 10";
BA_ "VNSigAllNodes" SG_ 1142 FLRRTrk10ObstType 1;
BA_ "SignalType" SG_ 1142 FLRRTrk9ObstTypeConf "UNM";
BA_ "SignalLongName" SG_ 1142 FLRRTrk9ObstTypeConf "Front Long Range Radar Obstacle Type Confirmation Track 9";
BA_ "VNSigAllNodes" SG_ 1142 FLRRTrk9ObstTypeConf 1;
BA_ "SignalType" SG_ 1142 FLRRTrk9ObstType "ENM";
BA_ "SignalLongName" SG_ 1142 FLRRTrk9ObstType "Front Long Range Radar Obstacle Type Track 9";
BA_ "VNSigAllNodes" SG_ 1142 FLRRTrk9ObstType 1;
BA_ "SignalType" SG_ 1142 FLRRTrk8ObstTypeConf "UNM";
BA_ "SignalLongName" SG_ 1142 FLRRTrk8ObstTypeConf "Front Long Range Radar Obstacle Type Confirmation Track 8";
BA_ "VNSigAllNodes" SG_ 1142 FLRRTrk8ObstTypeConf 1;
BA_ "SignalType" SG_ 1142 FLRRTrk8ObstType "ENM";
BA_ "SignalLongName" SG_ 1142 FLRRTrk8ObstType "Front Long Range Radar Obstacle Type Track 8";
BA_ "VNSigAllNodes" SG_ 1142 FLRRTrk8ObstType 1;
BA_ "SignalType" SG_ 1142 FLRRTrk7ObstTypeConf "UNM";
BA_ "SignalLongName" SG_ 1142 FLRRTrk7ObstTypeConf "Front Long Range Radar Obstacle Type Confirmation Track 7";
BA_ "VNSigAllNodes" SG_ 1142 FLRRTrk7ObstTypeConf 1;
BA_ "SignalType" SG_ 1142 FLRRTrk7ObstType "ENM";
BA_ "SignalLongName" SG_ 1142 FLRRTrk7ObstType "Front Long Range Radar Obstacle Type Track 7";
BA_ "VNSigAllNodes" SG_ 1142 FLRRTrk7ObstType 1;
BA_ "SignalType" SG_ 1142 FLRRTrk1ObstTypeConf "UNM";
BA_ "SignalLongName" SG_ 1142 FLRRTrk1ObstTypeConf "Front Long Range Radar Obstacle Type Confirmation Track 1";
BA_ "VNSigAllNodes" SG_ 1142 FLRRTrk1ObstTypeConf 1;
BA_ "SignalType" SG_ 1142 FLRRTrk1ObstType "ENM";
BA_ "SignalLongName" SG_ 1142 FLRRTrk1ObstType "Front Long Range Radar Obstacle Type Track 1";
BA_ "VNSigAllNodes" SG_ 1142 FLRRTrk1ObstType 1;
BA_ "SignalType" SG_ 1141 ObjLossInfoObjTrk1 "ENM";
BA_ "SignalLongName" SG_ 1141 ObjLossInfoObjTrk1 "Object Loss Information Object Track 1";
BA_ "VNSigAllNodes" SG_ 1141 ObjLossInfoObjTrk1 1;
BA_ "SignalType" SG_ 1141 Cut_In_Out_Pot_Objtrk2 "UNM";
BA_ "SignalLongName" SG_ 1141 Cut_In_Out_Pot_Objtrk2 "Cut In Cut Out Potential Object Track 2";
BA_ "VNSigAllNodes" SG_ 1141 Cut_In_Out_Pot_Objtrk2 1;
BA_ "SignalType" SG_ 1141 ObjLossInfoObjTrk2 "ENM";
BA_ "SignalLongName" SG_ 1141 ObjLossInfoObjTrk2 "Object Loss Information Object Track 2";
BA_ "VNSigAllNodes" SG_ 1141 ObjLossInfoObjTrk2 1;
BA_ "SignalType" SG_ 1141 Cut_In_Out_Pot_Objtrk3 "UNM";
BA_ "SignalLongName" SG_ 1141 Cut_In_Out_Pot_Objtrk3 "Cut In Cut Out Potential Object Track 3";
BA_ "VNSigAllNodes" SG_ 1141 Cut_In_Out_Pot_Objtrk3 1;
BA_ "SignalType" SG_ 1141 ObjLossInfoObjTrk3 "ENM";
BA_ "SignalLongName" SG_ 1141 ObjLossInfoObjTrk3 "Object Loss Information Object Track 3";
BA_ "VNSigAllNodes" SG_ 1141 ObjLossInfoObjTrk3 1;
BA_ "SignalType" SG_ 1141 Cut_In_Out_Pot_Objtrk4 "UNM";
BA_ "SignalLongName" SG_ 1141 Cut_In_Out_Pot_Objtrk4 "Cut In Cut Out Potential Object Track 4";
BA_ "VNSigAllNodes" SG_ 1141 Cut_In_Out_Pot_Objtrk4 1;
BA_ "SignalType" SG_ 1141 ObjLossInfoObjTrk4 "ENM";
BA_ "SignalLongName" SG_ 1141 ObjLossInfoObjTrk4 "Object Loss Information Object Track 4";
BA_ "VNSigAllNodes" SG_ 1141 ObjLossInfoObjTrk4 1;
BA_ "SignalType" SG_ 1141 Cut_In_Out_Pot_Objtrk5 "UNM";
BA_ "SignalLongName" SG_ 1141 Cut_In_Out_Pot_Objtrk5 "Cut In Cut Out Potential Object Track 5";
BA_ "VNSigAllNodes" SG_ 1141 Cut_In_Out_Pot_Objtrk5 1;
BA_ "SignalType" SG_ 1141 ObjLossInfoObjTrk5 "ENM";
BA_ "SignalLongName" SG_ 1141 ObjLossInfoObjTrk5 "Object Loss Information Object Track 5";
BA_ "VNSigAllNodes" SG_ 1141 ObjLossInfoObjTrk5 1;
BA_ "SignalType" SG_ 1141 Cut_In_Out_Pot_Objtrk6 "UNM";
BA_ "SignalLongName" SG_ 1141 Cut_In_Out_Pot_Objtrk6 "Cut In Cut Out Potential Object Track 6";
BA_ "VNSigAllNodes" SG_ 1141 Cut_In_Out_Pot_Objtrk6 1;
BA_ "SignalType" SG_ 1141 ObjLossInfoObjTrk6 "ENM";
BA_ "SignalLongName" SG_ 1141 ObjLossInfoObjTrk6 "Object Loss Information Object Track 6";
BA_ "VNSigAllNodes" SG_ 1141 ObjLossInfoObjTrk6 1;
BA_ "SignalType" SG_ 1141 FLRRAddInfo1BurstID "UNM";
BA_ "SignalLongName" SG_ 1141 FLRRAddInfo1BurstID "Front Long Range Radar Additional Information 1 Burst ID";
BA_ "VNSigAllNodes" SG_ 1141 FLRRAddInfo1BurstID 1;
BA_ "SignalType" SG_ 1141 Cut_In_Out_Pot_Objtrk1 "UNM";
BA_ "SignalLongName" SG_ 1141 Cut_In_Out_Pot_Objtrk1 "Cut In Cut Out Potential Object Track 1";
BA_ "VNSigAllNodes" SG_ 1141 Cut_In_Out_Pot_Objtrk1 1;
BA_ "SignalType" SG_ 1140 FLRRTrk20Conf "ENM";
BA_ "SignalLongName" SG_ 1140 FLRRTrk20Conf "Front Long Range Radar Track 20 Confidence";
BA_ "VNSigAllNodes" SG_ 1140 FLRRTrk20Conf 1;
BA_ "SignalType" SG_ 1140 FLRRTrk20BurstID "UNM";
BA_ "SignalLongName" SG_ 1140 FLRRTrk20BurstID "Front Long Range Radar Track 20 Burst ID";
BA_ "VNSigAllNodes" SG_ 1140 FLRRTrk20BurstID 1;
BA_ "SignalType" SG_ 1140 FLRRTrk20Range "UNM";
BA_ "SignalLongName" SG_ 1140 FLRRTrk20Range "Front Long Range Radar Track 20 Range";
BA_ "GenSigStartValue" SG_ 1140 FLRRTrk20Range 1;
BA_ "VNSigAllNodes" SG_ 1140 FLRRTrk20Range 1;
BA_ "SignalType" SG_ 1140 FLRRTrk20RangeRate "SNM";
BA_ "SignalLongName" SG_ 1140 FLRRTrk20RangeRate "Front Long Range Radar Track 20 Range Rate";
BA_ "VNSigAllNodes" SG_ 1140 FLRRTrk20RangeRate 1;
BA_ "SignalType" SG_ 1140 FLRRTrk20RangeAccel "SNM";
BA_ "SignalLongName" SG_ 1140 FLRRTrk20RangeAccel "Front Long Range Radar Track 20 Range Acceleration";
BA_ "VNSigAllNodes" SG_ 1140 FLRRTrk20RangeAccel 1;
BA_ "SignalType" SG_ 1140 FLRRTrk20DynProp "ENM";
BA_ "SignalLongName" SG_ 1140 FLRRTrk20DynProp "Front Long Range Radar Dynamic Property Track 20";
BA_ "VNSigAllNodes" SG_ 1140 FLRRTrk20DynProp 1;
BA_ "SignalType" SG_ 1140 FLRRTrk20Azimuth "SNM";
BA_ "SignalLongName" SG_ 1140 FLRRTrk20Azimuth "Front Long Range Radar Azimuth Track 20";
BA_ "VNSigAllNodes" SG_ 1140 FLRRTrk20Azimuth 1;
BA_ "SignalType" SG_ 1140 FLRRTrk20Width "UNM";
BA_ "SignalLongName" SG_ 1140 FLRRTrk20Width "Front Long Range Radar Track 20 Width";
BA_ "GenSigStartValue" SG_ 1140 FLRRTrk20Width 1;
BA_ "VNSigAllNodes" SG_ 1140 FLRRTrk20Width 1;
BA_ "SignalType" SG_ 1140 FLRRTrk20MeasStatus "ENM";
BA_ "SignalLongName" SG_ 1140 FLRRTrk20MeasStatus "Front Long Range Radar Measurement Status Track 20";
BA_ "VNSigAllNodes" SG_ 1140 FLRRTrk20MeasStatus 1;
BA_ "SignalType" SG_ 1140 FLRRTrk20ObjectID "UNM";
BA_ "SignalLongName" SG_ 1140 FLRRTrk20ObjectID "Front Long Range Radar Track 20 Object ID";
BA_ "VNSigAllNodes" SG_ 1140 FLRRTrk20ObjectID 1;
BA_ "SignalType" SG_ 1139 FLRRTrk19Conf "ENM";
BA_ "SignalLongName" SG_ 1139 FLRRTrk19Conf "Front Long Range Radar Track 19 Confidence";
BA_ "VNSigAllNodes" SG_ 1139 FLRRTrk19Conf 1;
BA_ "SignalType" SG_ 1139 FLRRTrk19BurstID "UNM";
BA_ "SignalLongName" SG_ 1139 FLRRTrk19BurstID "Front Long Range Radar Track 19 Burst ID";
BA_ "VNSigAllNodes" SG_ 1139 FLRRTrk19BurstID 1;
BA_ "SignalType" SG_ 1139 FLRRTrk19Range "UNM";
BA_ "SignalLongName" SG_ 1139 FLRRTrk19Range "Front Long Range Radar Track 19 Range";
BA_ "GenSigStartValue" SG_ 1139 FLRRTrk19Range 1;
BA_ "VNSigAllNodes" SG_ 1139 FLRRTrk19Range 1;
BA_ "SignalType" SG_ 1139 FLRRTrk19RangeRate "SNM";
BA_ "SignalLongName" SG_ 1139 FLRRTrk19RangeRate "Front Long Range Radar Track 19 Range Rate";
BA_ "VNSigAllNodes" SG_ 1139 FLRRTrk19RangeRate 1;
BA_ "SignalType" SG_ 1139 FLRRTrk19RangeAccel "SNM";
BA_ "SignalLongName" SG_ 1139 FLRRTrk19RangeAccel "Front Long Range Radar Track 19 Range Acceleration";
BA_ "VNSigAllNodes" SG_ 1139 FLRRTrk19RangeAccel 1;
BA_ "SignalType" SG_ 1139 FLRRTrk19DynProp "ENM";
BA_ "SignalLongName" SG_ 1139 FLRRTrk19DynProp "Front Long Range Radar Dynamic Property Track 19";
BA_ "VNSigAllNodes" SG_ 1139 FLRRTrk19DynProp 1;
BA_ "SignalType" SG_ 1139 FLRRTrk19Azimuth "SNM";
BA_ "SignalLongName" SG_ 1139 FLRRTrk19Azimuth "Front Long Range Radar Azimuth Track 19";
BA_ "VNSigAllNodes" SG_ 1139 FLRRTrk19Azimuth 1;
BA_ "SignalType" SG_ 1139 FLRRTrk19Width "UNM";
BA_ "SignalLongName" SG_ 1139 FLRRTrk19Width "Front Long Range Radar Track 19 Width";
BA_ "GenSigStartValue" SG_ 1139 FLRRTrk19Width 1;
BA_ "VNSigAllNodes" SG_ 1139 FLRRTrk19Width 1;
BA_ "SignalType" SG_ 1139 FLRRTrk19MeasStatus "ENM";
BA_ "SignalLongName" SG_ 1139 FLRRTrk19MeasStatus "Front Long Range Radar Measurement Status Track 19";
BA_ "VNSigAllNodes" SG_ 1139 FLRRTrk19MeasStatus 1;
BA_ "SignalType" SG_ 1139 FLRRTrk19ObjectID "UNM";
BA_ "SignalLongName" SG_ 1139 FLRRTrk19ObjectID "Front Long Range Radar Track 19 Object ID";
BA_ "VNSigAllNodes" SG_ 1139 FLRRTrk19ObjectID 1;
BA_ "SignalType" SG_ 1138 FLRRTrk18Conf "ENM";
BA_ "SignalLongName" SG_ 1138 FLRRTrk18Conf "Front Long Range Radar Track 18 Confidence";
BA_ "VNSigAllNodes" SG_ 1138 FLRRTrk18Conf 1;
BA_ "SignalType" SG_ 1138 FLRRTrk18BurstID "UNM";
BA_ "SignalLongName" SG_ 1138 FLRRTrk18BurstID "Front Long Range Radar Track 18 Burst ID";
BA_ "VNSigAllNodes" SG_ 1138 FLRRTrk18BurstID 1;
BA_ "SignalType" SG_ 1138 FLRRTrk18Range "UNM";
BA_ "SignalLongName" SG_ 1138 FLRRTrk18Range "Front Long Range Radar Track 18 Range";
BA_ "GenSigStartValue" SG_ 1138 FLRRTrk18Range 1;
BA_ "VNSigAllNodes" SG_ 1138 FLRRTrk18Range 1;
BA_ "SignalType" SG_ 1138 FLRRTrk18RangeRate "SNM";
BA_ "SignalLongName" SG_ 1138 FLRRTrk18RangeRate "Front Long Range Radar Track 18 Range Rate";
BA_ "VNSigAllNodes" SG_ 1138 FLRRTrk18RangeRate 1;
BA_ "SignalType" SG_ 1138 FLRRTrk18RangeAccel "SNM";
BA_ "SignalLongName" SG_ 1138 FLRRTrk18RangeAccel "Front Long Range Radar Track 18 Range Acceleration";
BA_ "VNSigAllNodes" SG_ 1138 FLRRTrk18RangeAccel 1;
BA_ "SignalType" SG_ 1138 FLRRTrk18DynProp "ENM";
BA_ "SignalLongName" SG_ 1138 FLRRTrk18DynProp "Front Long Range Radar Dynamic Property Track 18";
BA_ "VNSigAllNodes" SG_ 1138 FLRRTrk18DynProp 1;
BA_ "SignalType" SG_ 1138 FLRRTrk18Azimuth "SNM";
BA_ "SignalLongName" SG_ 1138 FLRRTrk18Azimuth "Front Long Range Radar Azimuth Track 18";
BA_ "VNSigAllNodes" SG_ 1138 FLRRTrk18Azimuth 1;
BA_ "SignalType" SG_ 1138 FLRRTrk18Width "UNM";
BA_ "SignalLongName" SG_ 1138 FLRRTrk18Width "Front Long Range Radar Track 18 Width";
BA_ "GenSigStartValue" SG_ 1138 FLRRTrk18Width 1;
BA_ "VNSigAllNodes" SG_ 1138 FLRRTrk18Width 1;
BA_ "SignalType" SG_ 1138 FLRRTrk18MeasStatus "ENM";
BA_ "SignalLongName" SG_ 1138 FLRRTrk18MeasStatus "Front Long Range Radar Measurement Status Track 18";
BA_ "VNSigAllNodes" SG_ 1138 FLRRTrk18MeasStatus 1;
BA_ "SignalType" SG_ 1138 FLRRTrk18ObjectID "UNM";
BA_ "SignalLongName" SG_ 1138 FLRRTrk18ObjectID "Front Long Range Radar Track 18 Object ID";
BA_ "VNSigAllNodes" SG_ 1138 FLRRTrk18ObjectID 1;
BA_ "SignalType" SG_ 1137 FLRRTrk17Conf "ENM";
BA_ "SignalLongName" SG_ 1137 FLRRTrk17Conf "Front Long Range Radar Track 17 Confidence";
BA_ "VNSigAllNodes" SG_ 1137 FLRRTrk17Conf 1;
BA_ "SignalType" SG_ 1137 FLRRTrk17BurstID "UNM";
BA_ "SignalLongName" SG_ 1137 FLRRTrk17BurstID "Front Long Range Radar Track 17 Burst ID";
BA_ "VNSigAllNodes" SG_ 1137 FLRRTrk17BurstID 1;
BA_ "SignalType" SG_ 1137 FLRRTrk17Range "UNM";
BA_ "SignalLongName" SG_ 1137 FLRRTrk17Range "Front Long Range Radar Track 17 Range";
BA_ "GenSigStartValue" SG_ 1137 FLRRTrk17Range 1;
BA_ "VNSigAllNodes" SG_ 1137 FLRRTrk17Range 1;
BA_ "SignalType" SG_ 1137 FLRRTrk17RangeRate "SNM";
BA_ "SignalLongName" SG_ 1137 FLRRTrk17RangeRate "Front Long Range Radar Track 17 Range Rate";
BA_ "VNSigAllNodes" SG_ 1137 FLRRTrk17RangeRate 1;
BA_ "SignalType" SG_ 1137 FLRRTrk17RangeAccel "SNM";
BA_ "SignalLongName" SG_ 1137 FLRRTrk17RangeAccel "Front Long Range Radar Track 17 Range Acceleration";
BA_ "VNSigAllNodes" SG_ 1137 FLRRTrk17RangeAccel 1;
BA_ "SignalType" SG_ 1137 FLRRTrk17DynProp "ENM";
BA_ "SignalLongName" SG_ 1137 FLRRTrk17DynProp "Front Long Range Radar Dynamic Property Track 17";
BA_ "VNSigAllNodes" SG_ 1137 FLRRTrk17DynProp 1;
BA_ "SignalType" SG_ 1137 FLRRTrk17Azimuth "SNM";
BA_ "SignalLongName" SG_ 1137 FLRRTrk17Azimuth "Front Long Range Radar Azimuth Track 17";
BA_ "VNSigAllNodes" SG_ 1137 FLRRTrk17Azimuth 1;
BA_ "SignalType" SG_ 1137 FLRRTrk17Width "UNM";
BA_ "SignalLongName" SG_ 1137 FLRRTrk17Width "Front Long Range Radar Track 17 Width";
BA_ "GenSigStartValue" SG_ 1137 FLRRTrk17Width 1;
BA_ "VNSigAllNodes" SG_ 1137 FLRRTrk17Width 1;
BA_ "SignalType" SG_ 1137 FLRRTrk17MeasStatus "ENM";
BA_ "SignalLongName" SG_ 1137 FLRRTrk17MeasStatus "Front Long Range Radar Measurement Status Track 17";
BA_ "VNSigAllNodes" SG_ 1137 FLRRTrk17MeasStatus 1;
BA_ "SignalType" SG_ 1137 FLRRTrk17ObjectID "UNM";
BA_ "SignalLongName" SG_ 1137 FLRRTrk17ObjectID "Front Long Range Radar Track 17 Object ID";
BA_ "VNSigAllNodes" SG_ 1137 FLRRTrk17ObjectID 1;
BA_ "SignalType" SG_ 1136 FLRRTrk16Conf "ENM";
BA_ "SignalLongName" SG_ 1136 FLRRTrk16Conf "Front Long Range Radar Track 16 Confidence";
BA_ "VNSigAllNodes" SG_ 1136 FLRRTrk16Conf 1;
BA_ "SignalType" SG_ 1136 FLRRTrk16BurstID "UNM";
BA_ "SignalLongName" SG_ 1136 FLRRTrk16BurstID "Front Long Range Radar Track 16 Burst ID";
BA_ "VNSigAllNodes" SG_ 1136 FLRRTrk16BurstID 1;
BA_ "SignalType" SG_ 1136 FLRRTrk16Range "UNM";
BA_ "SignalLongName" SG_ 1136 FLRRTrk16Range "Front Long Range Radar Track 16 Range";
BA_ "GenSigStartValue" SG_ 1136 FLRRTrk16Range 1;
BA_ "VNSigAllNodes" SG_ 1136 FLRRTrk16Range 1;
BA_ "SignalType" SG_ 1136 FLRRTrk16RangeRate "SNM";
BA_ "SignalLongName" SG_ 1136 FLRRTrk16RangeRate "Front Long Range Radar Track 16 Range Rate";
BA_ "VNSigAllNodes" SG_ 1136 FLRRTrk16RangeRate 1;
BA_ "SignalType" SG_ 1136 FLRRTrk16RangeAccel "SNM";
BA_ "SignalLongName" SG_ 1136 FLRRTrk16RangeAccel "Front Long Range Radar Track 16 Range Acceleration";
BA_ "VNSigAllNodes" SG_ 1136 FLRRTrk16RangeAccel 1;
BA_ "SignalType" SG_ 1136 FLRRTrk16DynProp "ENM";
BA_ "SignalLongName" SG_ 1136 FLRRTrk16DynProp "Front Long Range Radar Dynamic Property Track 16";
BA_ "VNSigAllNodes" SG_ 1136 FLRRTrk16DynProp 1;
BA_ "SignalType" SG_ 1136 FLRRTrk16Azimuth "SNM";
BA_ "SignalLongName" SG_ 1136 FLRRTrk16Azimuth "Front Long Range Radar Azimuth Track 16";
BA_ "VNSigAllNodes" SG_ 1136 FLRRTrk16Azimuth 1;
BA_ "SignalType" SG_ 1136 FLRRTrk16Width "UNM";
BA_ "SignalLongName" SG_ 1136 FLRRTrk16Width "Front Long Range Radar Track 16 Width";
BA_ "GenSigStartValue" SG_ 1136 FLRRTrk16Width 1;
BA_ "VNSigAllNodes" SG_ 1136 FLRRTrk16Width 1;
BA_ "SignalType" SG_ 1136 FLRRTrk16MeasStatus "ENM";
BA_ "SignalLongName" SG_ 1136 FLRRTrk16MeasStatus "Front Long Range Radar Measurement Status Track 16";
BA_ "VNSigAllNodes" SG_ 1136 FLRRTrk16MeasStatus 1;
BA_ "SignalType" SG_ 1136 FLRRTrk16ObjectID "UNM";
BA_ "SignalLongName" SG_ 1136 FLRRTrk16ObjectID "Front Long Range Radar Track 16 Object ID";
BA_ "VNSigAllNodes" SG_ 1136 FLRRTrk16ObjectID 1;
BA_ "SignalType" SG_ 1135 FLRRTrk15Width "UNM";
BA_ "SignalLongName" SG_ 1135 FLRRTrk15Width "Front Long Range Radar Track 15 Width";
BA_ "GenSigStartValue" SG_ 1135 FLRRTrk15Width 1;
BA_ "VNSigAllNodes" SG_ 1135 FLRRTrk15Width 1;
BA_ "SignalType" SG_ 1135 FLRRTrk15MeasStatus "ENM";
BA_ "SignalLongName" SG_ 1135 FLRRTrk15MeasStatus "Front Long Range Radar Measurement Status Track 15";
BA_ "VNSigAllNodes" SG_ 1135 FLRRTrk15MeasStatus 1;
BA_ "SignalType" SG_ 1135 FLRRTrk15Conf "ENM";
BA_ "SignalLongName" SG_ 1135 FLRRTrk15Conf "Front Long Range Radar Track 15 Confidence";
BA_ "VNSigAllNodes" SG_ 1135 FLRRTrk15Conf 1;
BA_ "SignalType" SG_ 1135 FLRRTrk15ObjectID "UNM";
BA_ "SignalLongName" SG_ 1135 FLRRTrk15ObjectID "Front Long Range Radar Track 15 Object ID";
BA_ "VNSigAllNodes" SG_ 1135 FLRRTrk15ObjectID 1;
BA_ "SignalType" SG_ 1135 FLRRTrk15BurstID "UNM";
BA_ "SignalLongName" SG_ 1135 FLRRTrk15BurstID "Front Long Range Radar Track 15 Burst ID";
BA_ "VNSigAllNodes" SG_ 1135 FLRRTrk15BurstID 1;
BA_ "SignalType" SG_ 1135 FLRRTrk15Range "UNM";
BA_ "SignalLongName" SG_ 1135 FLRRTrk15Range "Front Long Range Radar Track 15 Range";
BA_ "GenSigStartValue" SG_ 1135 FLRRTrk15Range 1;
BA_ "VNSigAllNodes" SG_ 1135 FLRRTrk15Range 1;
BA_ "SignalType" SG_ 1135 FLRRTrk15RangeRate "SNM";
BA_ "SignalLongName" SG_ 1135 FLRRTrk15RangeRate "Front Long Range Radar Track 15 Range Rate";
BA_ "VNSigAllNodes" SG_ 1135 FLRRTrk15RangeRate 1;
BA_ "SignalType" SG_ 1135 FLRRTrk15RangeAccel "SNM";
BA_ "SignalLongName" SG_ 1135 FLRRTrk15RangeAccel "Front Long Range Radar Track 15 Range Acceleration";
BA_ "VNSigAllNodes" SG_ 1135 FLRRTrk15RangeAccel 1;
BA_ "SignalType" SG_ 1135 FLRRTrk15DynProp "ENM";
BA_ "SignalLongName" SG_ 1135 FLRRTrk15DynProp "Front Long Range Radar Dynamic Property Track 15";
BA_ "VNSigAllNodes" SG_ 1135 FLRRTrk15DynProp 1;
BA_ "SignalType" SG_ 1135 FLRRTrk15Azimuth "SNM";
BA_ "SignalLongName" SG_ 1135 FLRRTrk15Azimuth "Front Long Range Radar Azimuth Track 15";
BA_ "VNSigAllNodes" SG_ 1135 FLRRTrk15Azimuth 1;
BA_ "SignalType" SG_ 1134 FLRRTrk14Conf "ENM";
BA_ "SignalLongName" SG_ 1134 FLRRTrk14Conf "Front Long Range Radar Track 14 Confidence";
BA_ "VNSigAllNodes" SG_ 1134 FLRRTrk14Conf 1;
BA_ "SignalType" SG_ 1134 FLRRTrk14BurstID "UNM";
BA_ "SignalLongName" SG_ 1134 FLRRTrk14BurstID "Front Long Range Radar Track 14 Burst ID";
BA_ "VNSigAllNodes" SG_ 1134 FLRRTrk14BurstID 1;
BA_ "SignalType" SG_ 1134 FLRRTrk14Range "UNM";
BA_ "SignalLongName" SG_ 1134 FLRRTrk14Range "Front Long Range Radar Track 14 Range";
BA_ "GenSigStartValue" SG_ 1134 FLRRTrk14Range 1;
BA_ "VNSigAllNodes" SG_ 1134 FLRRTrk14Range 1;
BA_ "SignalType" SG_ 1134 FLRRTrk14RangeRate "SNM";
BA_ "SignalLongName" SG_ 1134 FLRRTrk14RangeRate "Front Long Range Radar Track 14 Range Rate";
BA_ "VNSigAllNodes" SG_ 1134 FLRRTrk14RangeRate 1;
BA_ "SignalType" SG_ 1134 FLRRTrk14RangeAccel "SNM";
BA_ "SignalLongName" SG_ 1134 FLRRTrk14RangeAccel "Front Long Range Radar Track 14 Range Acceleration";
BA_ "VNSigAllNodes" SG_ 1134 FLRRTrk14RangeAccel 1;
BA_ "SignalType" SG_ 1134 FLRRTrk14DynProp "ENM";
BA_ "SignalLongName" SG_ 1134 FLRRTrk14DynProp "Front Long Range Radar Dynamic Property Track 14";
BA_ "VNSigAllNodes" SG_ 1134 FLRRTrk14DynProp 1;
BA_ "SignalType" SG_ 1134 FLRRTrk14Azimuth "SNM";
BA_ "SignalLongName" SG_ 1134 FLRRTrk14Azimuth "Front Long Range Radar Azimuth Track 14";
BA_ "VNSigAllNodes" SG_ 1134 FLRRTrk14Azimuth 1;
BA_ "SignalType" SG_ 1134 FLRRTrk14Width "UNM";
BA_ "SignalLongName" SG_ 1134 FLRRTrk14Width "Front Long Range Radar Track 14 Width";
BA_ "GenSigStartValue" SG_ 1134 FLRRTrk14Width 1;
BA_ "VNSigAllNodes" SG_ 1134 FLRRTrk14Width 1;
BA_ "SignalType" SG_ 1134 FLRRTrk14MeasStatus "ENM";
BA_ "SignalLongName" SG_ 1134 FLRRTrk14MeasStatus "Front Long Range Radar Measurement Status Track 14";
BA_ "VNSigAllNodes" SG_ 1134 FLRRTrk14MeasStatus 1;
BA_ "SignalType" SG_ 1134 FLRRTrk14ObjectID "UNM";
BA_ "SignalLongName" SG_ 1134 FLRRTrk14ObjectID "Front Long Range Radar Track 14 Object ID";
BA_ "VNSigAllNodes" SG_ 1134 FLRRTrk14ObjectID 1;
BA_ "SignalType" SG_ 1133 FLRRTrk13Conf "ENM";
BA_ "SignalLongName" SG_ 1133 FLRRTrk13Conf "Front Long Range Radar Track 13 Confidence";
BA_ "VNSigAllNodes" SG_ 1133 FLRRTrk13Conf 1;
BA_ "SignalType" SG_ 1133 FLRRTrk13BurstID "UNM";
BA_ "SignalLongName" SG_ 1133 FLRRTrk13BurstID "Front Long Range Radar Track 13 Burst ID";
BA_ "VNSigAllNodes" SG_ 1133 FLRRTrk13BurstID 1;
BA_ "SignalType" SG_ 1133 FLRRTrk13Range "UNM";
BA_ "SignalLongName" SG_ 1133 FLRRTrk13Range "Front Long Range Radar Track 13 Range";
BA_ "GenSigStartValue" SG_ 1133 FLRRTrk13Range 1;
BA_ "VNSigAllNodes" SG_ 1133 FLRRTrk13Range 1;
BA_ "SignalType" SG_ 1133 FLRRTrk13RangeRate "SNM";
BA_ "SignalLongName" SG_ 1133 FLRRTrk13RangeRate "Front Long Range Radar Track 13 Range Rate";
BA_ "VNSigAllNodes" SG_ 1133 FLRRTrk13RangeRate 1;
BA_ "SignalType" SG_ 1133 FLRRTrk13RangeAccel "SNM";
BA_ "SignalLongName" SG_ 1133 FLRRTrk13RangeAccel "Front Long Range Radar Track 13 Range Acceleration";
BA_ "VNSigAllNodes" SG_ 1133 FLRRTrk13RangeAccel 1;
BA_ "SignalType" SG_ 1133 FLRRTrk13DynProp "ENM";
BA_ "SignalLongName" SG_ 1133 FLRRTrk13DynProp "Front Long Range Radar Dynamic Property Track 13";
BA_ "VNSigAllNodes" SG_ 1133 FLRRTrk13DynProp 1;
BA_ "SignalType" SG_ 1133 FLRRTrk13Azimuth "SNM";
BA_ "SignalLongName" SG_ 1133 FLRRTrk13Azimuth "Front Long Range Radar Azimuth Track 13";
BA_ "VNSigAllNodes" SG_ 1133 FLRRTrk13Azimuth 1;
BA_ "SignalType" SG_ 1133 FLRRTrk13Width "UNM";
BA_ "SignalLongName" SG_ 1133 FLRRTrk13Width "Front Long Range Radar Track 13 Width";
BA_ "GenSigStartValue" SG_ 1133 FLRRTrk13Width 1;
BA_ "VNSigAllNodes" SG_ 1133 FLRRTrk13Width 1;
BA_ "SignalType" SG_ 1133 FLRRTrk13MeasStatus "ENM";
BA_ "SignalLongName" SG_ 1133 FLRRTrk13MeasStatus "Front Long Range Radar Measurement Status Track 13";
BA_ "VNSigAllNodes" SG_ 1133 FLRRTrk13MeasStatus 1;
BA_ "SignalType" SG_ 1133 FLRRTrk13ObjectID "UNM";
BA_ "SignalLongName" SG_ 1133 FLRRTrk13ObjectID "Front Long Range Radar Track 13 Object ID";
BA_ "VNSigAllNodes" SG_ 1133 FLRRTrk13ObjectID 1;
BA_ "SignalType" SG_ 1132 FLRRTrk12Conf "ENM";
BA_ "SignalLongName" SG_ 1132 FLRRTrk12Conf "Front Long Range Radar Track 12 Confidence";
BA_ "VNSigAllNodes" SG_ 1132 FLRRTrk12Conf 1;
BA_ "SignalType" SG_ 1132 FLRRTrk12BurstID "UNM";
BA_ "SignalLongName" SG_ 1132 FLRRTrk12BurstID "Front Long Range Radar Track 12 Burst ID";
BA_ "VNSigAllNodes" SG_ 1132 FLRRTrk12BurstID 1;
BA_ "SignalType" SG_ 1132 FLRRTrk12Range "UNM";
BA_ "SignalLongName" SG_ 1132 FLRRTrk12Range "Front Long Range Radar Track 12 Range";
BA_ "GenSigStartValue" SG_ 1132 FLRRTrk12Range 1;
BA_ "VNSigAllNodes" SG_ 1132 FLRRTrk12Range 1;
BA_ "SignalType" SG_ 1132 FLRRTrk12RangeRate "SNM";
BA_ "SignalLongName" SG_ 1132 FLRRTrk12RangeRate "Front Long Range Radar Track 12 Range Rate";
BA_ "VNSigAllNodes" SG_ 1132 FLRRTrk12RangeRate 1;
BA_ "SignalType" SG_ 1132 FLRRTrk12RangeAccel "SNM";
BA_ "SignalLongName" SG_ 1132 FLRRTrk12RangeAccel "Front Long Range Radar Track 12 Range Acceleration";
BA_ "VNSigAllNodes" SG_ 1132 FLRRTrk12RangeAccel 1;
BA_ "SignalType" SG_ 1132 FLRRTrk12DynProp "ENM";
BA_ "SignalLongName" SG_ 1132 FLRRTrk12DynProp "Front Long Range Radar Dynamic Property Track 12";
BA_ "VNSigAllNodes" SG_ 1132 FLRRTrk12DynProp 1;
BA_ "SignalType" SG_ 1132 FLRRTrk12Azimuth "SNM";
BA_ "SignalLongName" SG_ 1132 FLRRTrk12Azimuth "Front Long Range Radar Azimuth Track 12";
BA_ "VNSigAllNodes" SG_ 1132 FLRRTrk12Azimuth 1;
BA_ "SignalType" SG_ 1132 FLRRTrk12Width "UNM";
BA_ "SignalLongName" SG_ 1132 FLRRTrk12Width "Front Long Range Radar Track 12 Width";
BA_ "GenSigStartValue" SG_ 1132 FLRRTrk12Width 1;
BA_ "VNSigAllNodes" SG_ 1132 FLRRTrk12Width 1;
BA_ "SignalType" SG_ 1132 FLRRTrk12MeasStatus "ENM";
BA_ "SignalLongName" SG_ 1132 FLRRTrk12MeasStatus "Front Long Range Radar Measurement Status Track 12";
BA_ "VNSigAllNodes" SG_ 1132 FLRRTrk12MeasStatus 1;
BA_ "SignalType" SG_ 1132 FLRRTrk12ObjectID "UNM";
BA_ "SignalLongName" SG_ 1132 FLRRTrk12ObjectID "Front Long Range Radar Track 12 Object ID";
BA_ "VNSigAllNodes" SG_ 1132 FLRRTrk12ObjectID 1;
BA_ "SignalType" SG_ 1131 FLRRTrk11Conf "ENM";
BA_ "SignalLongName" SG_ 1131 FLRRTrk11Conf "Front Long Range Radar Track 11 Confidence";
BA_ "VNSigAllNodes" SG_ 1131 FLRRTrk11Conf 1;
BA_ "SignalType" SG_ 1131 FLRRTrk11BurstID "UNM";
BA_ "SignalLongName" SG_ 1131 FLRRTrk11BurstID "Front Long Range Radar Track 11 Burst ID";
BA_ "VNSigAllNodes" SG_ 1131 FLRRTrk11BurstID 1;
BA_ "SignalType" SG_ 1131 FLRRTrk11Range "UNM";
BA_ "SignalLongName" SG_ 1131 FLRRTrk11Range "Front Long Range Radar Track 11 Range";
BA_ "GenSigStartValue" SG_ 1131 FLRRTrk11Range 1;
BA_ "VNSigAllNodes" SG_ 1131 FLRRTrk11Range 1;
BA_ "SignalType" SG_ 1131 FLRRTrk11RangeRate "SNM";
BA_ "SignalLongName" SG_ 1131 FLRRTrk11RangeRate "Front Long Range Radar Track 11 Range Rate";
BA_ "VNSigAllNodes" SG_ 1131 FLRRTrk11RangeRate 1;
BA_ "SignalType" SG_ 1131 FLRRTrk11RangeAccel "SNM";
BA_ "SignalLongName" SG_ 1131 FLRRTrk11RangeAccel "Front Long Range Radar Track 11 Range Acceleration";
BA_ "VNSigAllNodes" SG_ 1131 FLRRTrk11RangeAccel 1;
BA_ "SignalType" SG_ 1131 FLRRTrk11DynProp "ENM";
BA_ "SignalLongName" SG_ 1131 FLRRTrk11DynProp "Front Long Range Radar Dynamic Property Track 11";
BA_ "VNSigAllNodes" SG_ 1131 FLRRTrk11DynProp 1;
BA_ "SignalType" SG_ 1131 FLRRTrk11Azimuth "SNM";
BA_ "SignalLongName" SG_ 1131 FLRRTrk11Azimuth "Front Long Range Radar Azimuth Track 11";
BA_ "VNSigAllNodes" SG_ 1131 FLRRTrk11Azimuth 1;
BA_ "SignalType" SG_ 1131 FLRRTrk11Width "UNM";
BA_ "SignalLongName" SG_ 1131 FLRRTrk11Width "Front Long Range Radar Track 11 Width";
BA_ "GenSigStartValue" SG_ 1131 FLRRTrk11Width 1;
BA_ "VNSigAllNodes" SG_ 1131 FLRRTrk11Width 1;
BA_ "SignalType" SG_ 1131 FLRRTrk11MeasStatus "ENM";
BA_ "SignalLongName" SG_ 1131 FLRRTrk11MeasStatus "Front Long Range Radar Measurement Status Track 11";
BA_ "VNSigAllNodes" SG_ 1131 FLRRTrk11MeasStatus 1;
BA_ "SignalType" SG_ 1131 FLRRTrk11ObjectID "UNM";
BA_ "SignalLongName" SG_ 1131 FLRRTrk11ObjectID "Front Long Range Radar Track 11 Object ID";
BA_ "VNSigAllNodes" SG_ 1131 FLRRTrk11ObjectID 1;
BA_ "SignalType" SG_ 1130 FLRRTrk10Conf "ENM";
BA_ "SignalLongName" SG_ 1130 FLRRTrk10Conf "Front Long Range Radar Track 10 Confidence";
BA_ "VNSigAllNodes" SG_ 1130 FLRRTrk10Conf 1;
BA_ "SignalType" SG_ 1130 FLRRTrk10BurstID "UNM";
BA_ "SignalLongName" SG_ 1130 FLRRTrk10BurstID "Front Long Range Radar Track 10 Burst ID";
BA_ "VNSigAllNodes" SG_ 1130 FLRRTrk10BurstID 1;
BA_ "SignalType" SG_ 1130 FLRRTrk10Range "UNM";
BA_ "SignalLongName" SG_ 1130 FLRRTrk10Range "Front Long Range Radar Track 10 Range";
BA_ "GenSigStartValue" SG_ 1130 FLRRTrk10Range 1;
BA_ "VNSigAllNodes" SG_ 1130 FLRRTrk10Range 1;
BA_ "SignalType" SG_ 1130 FLRRTrk10RangeRate "SNM";
BA_ "SignalLongName" SG_ 1130 FLRRTrk10RangeRate "Front Long Range Radar Track 10 Range Rate";
BA_ "VNSigAllNodes" SG_ 1130 FLRRTrk10RangeRate 1;
BA_ "SignalType" SG_ 1130 FLRRTrk10RangeAccel "SNM";
BA_ "SignalLongName" SG_ 1130 FLRRTrk10RangeAccel "Front Long Range Radar Track 10 Range Acceleration";
BA_ "VNSigAllNodes" SG_ 1130 FLRRTrk10RangeAccel 1;
BA_ "SignalType" SG_ 1130 FLRRTrk10DynProp "ENM";
BA_ "SignalLongName" SG_ 1130 FLRRTrk10DynProp "Front Long Range Radar Dynamic Property Track 10";
BA_ "VNSigAllNodes" SG_ 1130 FLRRTrk10DynProp 1;
BA_ "SignalType" SG_ 1130 FLRRTrk10Azimuth "SNM";
BA_ "SignalLongName" SG_ 1130 FLRRTrk10Azimuth "Front Long Range Radar Azimuth Track 10";
BA_ "VNSigAllNodes" SG_ 1130 FLRRTrk10Azimuth 1;
BA_ "SignalType" SG_ 1130 FLRRTrk10Width "UNM";
BA_ "SignalLongName" SG_ 1130 FLRRTrk10Width "Front Long Range Radar Track 10 Width";
BA_ "GenSigStartValue" SG_ 1130 FLRRTrk10Width 1;
BA_ "VNSigAllNodes" SG_ 1130 FLRRTrk10Width 1;
BA_ "SignalType" SG_ 1130 FLRRTrk10MeasStatus "ENM";
BA_ "SignalLongName" SG_ 1130 FLRRTrk10MeasStatus "Front Long Range Radar Measurement Status Track 10";
BA_ "VNSigAllNodes" SG_ 1130 FLRRTrk10MeasStatus 1;
BA_ "SignalType" SG_ 1130 FLRRTrk10ObjectID "UNM";
BA_ "SignalLongName" SG_ 1130 FLRRTrk10ObjectID "Front Long Range Radar Track 10 Object ID";
BA_ "VNSigAllNodes" SG_ 1130 FLRRTrk10ObjectID 1;
BA_ "SignalType" SG_ 1129 FLRRTrk9Conf "ENM";
BA_ "SignalLongName" SG_ 1129 FLRRTrk9Conf "Front Long Range Radar Track 9 Confidence";
BA_ "VNSigAllNodes" SG_ 1129 FLRRTrk9Conf 1;
BA_ "SignalType" SG_ 1129 FLRRTrk9BurstID "UNM";
BA_ "SignalLongName" SG_ 1129 FLRRTrk9BurstID "Front Long Range Radar Track 9 Burst ID";
BA_ "VNSigAllNodes" SG_ 1129 FLRRTrk9BurstID 1;
BA_ "SignalType" SG_ 1129 FLRRTrk9Range "UNM";
BA_ "SignalLongName" SG_ 1129 FLRRTrk9Range "Front Long Range Radar Track 9 Range";
BA_ "GenSigStartValue" SG_ 1129 FLRRTrk9Range 1;
BA_ "VNSigAllNodes" SG_ 1129 FLRRTrk9Range 1;
BA_ "SignalType" SG_ 1129 FLRRTrk9RangeRate "SNM";
BA_ "SignalLongName" SG_ 1129 FLRRTrk9RangeRate "Front Long Range Radar Track 9 Range Rate";
BA_ "VNSigAllNodes" SG_ 1129 FLRRTrk9RangeRate 1;
BA_ "SignalType" SG_ 1129 FLRRTrk9RangeAccel "SNM";
BA_ "SignalLongName" SG_ 1129 FLRRTrk9RangeAccel "Front Long Range Radar Track 9 Range Acceleration";
BA_ "VNSigAllNodes" SG_ 1129 FLRRTrk9RangeAccel 1;
BA_ "SignalType" SG_ 1129 FLRRTrk9DynProp "ENM";
BA_ "SignalLongName" SG_ 1129 FLRRTrk9DynProp "Front Long Range Radar Dynamic Property Track 9";
BA_ "VNSigAllNodes" SG_ 1129 FLRRTrk9DynProp 1;
BA_ "SignalType" SG_ 1129 FLRRTrk9Azimuth "SNM";
BA_ "SignalLongName" SG_ 1129 FLRRTrk9Azimuth "Front Long Range Radar Azimuth Track 9";
BA_ "VNSigAllNodes" SG_ 1129 FLRRTrk9Azimuth 1;
BA_ "SignalType" SG_ 1129 FLRRTrk9Width "UNM";
BA_ "SignalLongName" SG_ 1129 FLRRTrk9Width "Front Long Range Radar Track 9 Width";
BA_ "GenSigStartValue" SG_ 1129 FLRRTrk9Width 1;
BA_ "VNSigAllNodes" SG_ 1129 FLRRTrk9Width 1;
BA_ "SignalType" SG_ 1129 FLRRTrk9MeasStatus "ENM";
BA_ "SignalLongName" SG_ 1129 FLRRTrk9MeasStatus "Front Long Range Radar Measurement Status Track 9";
BA_ "VNSigAllNodes" SG_ 1129 FLRRTrk9MeasStatus 1;
BA_ "SignalType" SG_ 1129 FLRRTrk9ObjectID "UNM";
BA_ "SignalLongName" SG_ 1129 FLRRTrk9ObjectID "Front Long Range Radar Track 9 Object ID";
BA_ "VNSigAllNodes" SG_ 1129 FLRRTrk9ObjectID 1;
BA_ "SignalType" SG_ 1128 FLRRTrk8Conf "ENM";
BA_ "SignalLongName" SG_ 1128 FLRRTrk8Conf "Front Long Range Radar Track 8 Confidence";
BA_ "VNSigAllNodes" SG_ 1128 FLRRTrk8Conf 1;
BA_ "SignalType" SG_ 1128 FLRRTrk8BurstID "UNM";
BA_ "SignalLongName" SG_ 1128 FLRRTrk8BurstID "Front Long Range Radar Track 8 Burst ID";
BA_ "VNSigAllNodes" SG_ 1128 FLRRTrk8BurstID 1;
BA_ "SignalType" SG_ 1128 FLRRTrk8Range "UNM";
BA_ "SignalLongName" SG_ 1128 FLRRTrk8Range "Front Long Range Radar Track 8 Range";
BA_ "GenSigStartValue" SG_ 1128 FLRRTrk8Range 1;
BA_ "VNSigAllNodes" SG_ 1128 FLRRTrk8Range 1;
BA_ "SignalType" SG_ 1128 FLRRTrk8RangeRate "SNM";
BA_ "SignalLongName" SG_ 1128 FLRRTrk8RangeRate "Front Long Range Radar Track 8 Range Rate";
BA_ "VNSigAllNodes" SG_ 1128 FLRRTrk8RangeRate 1;
BA_ "SignalType" SG_ 1128 FLRRTrk8RangeAccel "SNM";
BA_ "SignalLongName" SG_ 1128 FLRRTrk8RangeAccel "Front Long Range Radar Track 8 Range Acceleration";
BA_ "VNSigAllNodes" SG_ 1128 FLRRTrk8RangeAccel 1;
BA_ "SignalType" SG_ 1128 FLRRTrk8DynProp "ENM";
BA_ "SignalLongName" SG_ 1128 FLRRTrk8DynProp "Front Long Range Radar Dynamic Property Track 8";
BA_ "VNSigAllNodes" SG_ 1128 FLRRTrk8DynProp 1;
BA_ "SignalType" SG_ 1128 FLRRTrk8Azimuth "SNM";
BA_ "SignalLongName" SG_ 1128 FLRRTrk8Azimuth "Front Long Range Radar Azimuth Track 8";
BA_ "VNSigAllNodes" SG_ 1128 FLRRTrk8Azimuth 1;
BA_ "SignalType" SG_ 1128 FLRRTrk8Width "UNM";
BA_ "SignalLongName" SG_ 1128 FLRRTrk8Width "Front Long Range Radar Track 8 Width";
BA_ "GenSigStartValue" SG_ 1128 FLRRTrk8Width 1;
BA_ "VNSigAllNodes" SG_ 1128 FLRRTrk8Width 1;
BA_ "SignalType" SG_ 1128 FLRRTrk8MeasStatus "ENM";
BA_ "SignalLongName" SG_ 1128 FLRRTrk8MeasStatus "Front Long Range Radar Measurement Status Track 8";
BA_ "VNSigAllNodes" SG_ 1128 FLRRTrk8MeasStatus 1;
BA_ "SignalType" SG_ 1128 FLRRTrk8ObjectID "UNM";
BA_ "SignalLongName" SG_ 1128 FLRRTrk8ObjectID "Front Long Range Radar Track 8 Object ID";
BA_ "VNSigAllNodes" SG_ 1128 FLRRTrk8ObjectID 1;
BA_ "SignalType" SG_ 1127 FLRRTrk7Conf "ENM";
BA_ "SignalLongName" SG_ 1127 FLRRTrk7Conf "Front Long Range Radar Track 7 Confidence";
BA_ "VNSigAllNodes" SG_ 1127 FLRRTrk7Conf 1;
BA_ "SignalType" SG_ 1127 FLRRTrk7BurstID "UNM";
BA_ "SignalLongName" SG_ 1127 FLRRTrk7BurstID "Front Long Range Radar Track 7 Burst ID";
BA_ "VNSigAllNodes" SG_ 1127 FLRRTrk7BurstID 1;
BA_ "SignalType" SG_ 1127 FLRRTrk7Range "UNM";
BA_ "SignalLongName" SG_ 1127 FLRRTrk7Range "Front Long Range Radar Track 7 Range";
BA_ "GenSigStartValue" SG_ 1127 FLRRTrk7Range 1;
BA_ "VNSigAllNodes" SG_ 1127 FLRRTrk7Range 1;
BA_ "SignalType" SG_ 1127 FLRRTrk7RangeRate "SNM";
BA_ "SignalLongName" SG_ 1127 FLRRTrk7RangeRate "Front Long Range Radar Track 7 Range Rate";
BA_ "VNSigAllNodes" SG_ 1127 FLRRTrk7RangeRate 1;
BA_ "SignalType" SG_ 1127 FLRRTrk7RangeAccel "SNM";
BA_ "SignalLongName" SG_ 1127 FLRRTrk7RangeAccel "Front Long Range Radar Track 7 Range Acceleration";
BA_ "VNSigAllNodes" SG_ 1127 FLRRTrk7RangeAccel 1;
BA_ "SignalType" SG_ 1127 FLRRTrk7DynProp "ENM";
BA_ "SignalLongName" SG_ 1127 FLRRTrk7DynProp "Front Long Range Radar Dynamic Property Track 7";
BA_ "VNSigAllNodes" SG_ 1127 FLRRTrk7DynProp 1;
BA_ "SignalType" SG_ 1127 FLRRTrk7Azimuth "SNM";
BA_ "SignalLongName" SG_ 1127 FLRRTrk7Azimuth "Front Long Range Radar Azimuth Track 7";
BA_ "VNSigAllNodes" SG_ 1127 FLRRTrk7Azimuth 1;
BA_ "SignalType" SG_ 1127 FLRRTrk7Width "UNM";
BA_ "SignalLongName" SG_ 1127 FLRRTrk7Width "Front Long Range Radar Track 7 Width";
BA_ "GenSigStartValue" SG_ 1127 FLRRTrk7Width 1;
BA_ "VNSigAllNodes" SG_ 1127 FLRRTrk7Width 1;
BA_ "SignalType" SG_ 1127 FLRRTrk7MeasStatus "ENM";
BA_ "SignalLongName" SG_ 1127 FLRRTrk7MeasStatus "Front Long Range Radar Measurement Status Track 7";
BA_ "VNSigAllNodes" SG_ 1127 FLRRTrk7MeasStatus 1;
BA_ "SignalType" SG_ 1127 FLRRTrk7ObjectID "UNM";
BA_ "SignalLongName" SG_ 1127 FLRRTrk7ObjectID "Front Long Range Radar Track 7 Object ID";
BA_ "VNSigAllNodes" SG_ 1127 FLRRTrk7ObjectID 1;
BA_ "SignalType" SG_ 1126 FLRRTrk6BurstID "UNM";
BA_ "SignalLongName" SG_ 1126 FLRRTrk6BurstID "Front Long Range Radar Track 6 Burst ID";
BA_ "VNSigAllNodes" SG_ 1126 FLRRTrk6BurstID 1;
BA_ "SignalType" SG_ 1126 FLRRTrk6Range "UNM";
BA_ "SignalLongName" SG_ 1126 FLRRTrk6Range "Front Long Range Radar Track 6 Range";
BA_ "GenSigStartValue" SG_ 1126 FLRRTrk6Range 1;
BA_ "VNSigAllNodes" SG_ 1126 FLRRTrk6Range 1;
BA_ "SignalType" SG_ 1126 FLRRTrk6RangeRate "SNM";
BA_ "SignalLongName" SG_ 1126 FLRRTrk6RangeRate "Front Long Range Radar Track 6 Range Rate";
BA_ "VNSigAllNodes" SG_ 1126 FLRRTrk6RangeRate 1;
BA_ "SignalType" SG_ 1126 FLRRTrk6Conf "ENM";
BA_ "SignalLongName" SG_ 1126 FLRRTrk6Conf "Front Long Range Radar Track 6 Confidence";
BA_ "VNSigAllNodes" SG_ 1126 FLRRTrk6Conf 1;
BA_ "SignalType" SG_ 1126 FLRRTrk6RangeAccel "SNM";
BA_ "SignalLongName" SG_ 1126 FLRRTrk6RangeAccel "Front Long Range Radar Track 6 Range Acceleration";
BA_ "VNSigAllNodes" SG_ 1126 FLRRTrk6RangeAccel 1;
BA_ "SignalType" SG_ 1126 FLRRTrk6DynProp "ENM";
BA_ "SignalLongName" SG_ 1126 FLRRTrk6DynProp "Front Long Range Radar Dynamic Property Track 6";
BA_ "VNSigAllNodes" SG_ 1126 FLRRTrk6DynProp 1;
BA_ "SignalType" SG_ 1126 FLRRTrk6Azimuth "SNM";
BA_ "SignalLongName" SG_ 1126 FLRRTrk6Azimuth "Front Long Range Radar Azimuth Track 6";
BA_ "VNSigAllNodes" SG_ 1126 FLRRTrk6Azimuth 1;
BA_ "SignalType" SG_ 1126 FLRRTrk6Width "UNM";
BA_ "SignalLongName" SG_ 1126 FLRRTrk6Width "Front Long Range Radar Track 6 Width";
BA_ "GenSigStartValue" SG_ 1126 FLRRTrk6Width 1;
BA_ "VNSigAllNodes" SG_ 1126 FLRRTrk6Width 1;
BA_ "SignalType" SG_ 1126 FLRRTrk6MeasStatus "ENM";
BA_ "SignalLongName" SG_ 1126 FLRRTrk6MeasStatus "Front Long Range Radar Measurement Status Track 6";
BA_ "VNSigAllNodes" SG_ 1126 FLRRTrk6MeasStatus 1;
BA_ "SignalType" SG_ 1126 FLRRTrk6ObjectID "UNM";
BA_ "SignalLongName" SG_ 1126 FLRRTrk6ObjectID "Front Long Range Radar Track 6 Object ID";
BA_ "VNSigAllNodes" SG_ 1126 FLRRTrk6ObjectID 1;
BA_ "SignalType" SG_ 1125 FLRRTrk5BurstID "UNM";
BA_ "SignalLongName" SG_ 1125 FLRRTrk5BurstID "Front Long Range Radar Track 5 Burst ID";
BA_ "VNSigAllNodes" SG_ 1125 FLRRTrk5BurstID 1;
BA_ "SignalType" SG_ 1125 FLRRTrk5Range "UNM";
BA_ "SignalLongName" SG_ 1125 FLRRTrk5Range "Front Long Range Radar Track 5 Range";
BA_ "GenSigStartValue" SG_ 1125 FLRRTrk5Range 1;
BA_ "VNSigAllNodes" SG_ 1125 FLRRTrk5Range 1;
BA_ "SignalType" SG_ 1125 FLRRTrk5RangeRate "SNM";
BA_ "SignalLongName" SG_ 1125 FLRRTrk5RangeRate "Front Long Range Radar Track 5 RangeRate";
BA_ "VNSigAllNodes" SG_ 1125 FLRRTrk5RangeRate 1;
BA_ "SignalType" SG_ 1125 FLRRTrk5RangeAccel "SNM";
BA_ "SignalLongName" SG_ 1125 FLRRTrk5RangeAccel "Front Long Range Radar Track 5 Range Acceleration";
BA_ "VNSigAllNodes" SG_ 1125 FLRRTrk5RangeAccel 1;
BA_ "SignalType" SG_ 1125 FLRRTrk5DynProp "ENM";
BA_ "SignalLongName" SG_ 1125 FLRRTrk5DynProp "Front Long Range Radar Dynamic Property Track 5";
BA_ "VNSigAllNodes" SG_ 1125 FLRRTrk5DynProp 1;
BA_ "SignalType" SG_ 1125 FLRRTrk5Azimuth "SNM";
BA_ "SignalLongName" SG_ 1125 FLRRTrk5Azimuth "Front Long Range Radar Azimuth Track 5";
BA_ "VNSigAllNodes" SG_ 1125 FLRRTrk5Azimuth 1;
BA_ "SignalType" SG_ 1125 FLRRTrk5Width "UNM";
BA_ "SignalLongName" SG_ 1125 FLRRTrk5Width "Front Long Range Radar Track 5 Width";
BA_ "GenSigStartValue" SG_ 1125 FLRRTrk5Width 1;
BA_ "VNSigAllNodes" SG_ 1125 FLRRTrk5Width 1;
BA_ "SignalType" SG_ 1125 FLRRTrk5MeasStatus "ENM";
BA_ "SignalLongName" SG_ 1125 FLRRTrk5MeasStatus "Front Long Range Radar Measurement Status Track 5";
BA_ "VNSigAllNodes" SG_ 1125 FLRRTrk5MeasStatus 1;
BA_ "SignalType" SG_ 1125 FLRRTrk5ObjectID "UNM";
BA_ "SignalLongName" SG_ 1125 FLRRTrk5ObjectID "Front Long Range Radar Track 5 ObjectID";
BA_ "VNSigAllNodes" SG_ 1125 FLRRTrk5ObjectID 1;
BA_ "SignalType" SG_ 1125 FLRRTrk5Conf "ENM";
BA_ "SignalLongName" SG_ 1125 FLRRTrk5Conf "Front Long Range Radar Track 5 Confidence";
BA_ "VNSigAllNodes" SG_ 1125 FLRRTrk5Conf 1;
BA_ "SignalType" SG_ 1124 FLRRTrk4BurstID "UNM";
BA_ "SignalLongName" SG_ 1124 FLRRTrk4BurstID "Front Long Range Radar Track 4 Burst ID";
BA_ "VNSigAllNodes" SG_ 1124 FLRRTrk4BurstID 1;
BA_ "SignalType" SG_ 1124 FLRRTrk4Range "UNM";
BA_ "SignalLongName" SG_ 1124 FLRRTrk4Range "Front Long Range Radar Track 4 Range";
BA_ "GenSigStartValue" SG_ 1124 FLRRTrk4Range 1;
BA_ "VNSigAllNodes" SG_ 1124 FLRRTrk4Range 1;
BA_ "SignalType" SG_ 1124 FLRRTrk4RangeRate "SNM";
BA_ "SignalLongName" SG_ 1124 FLRRTrk4RangeRate "Front Long Range Radar Track 4 Range Rate";
BA_ "VNSigAllNodes" SG_ 1124 FLRRTrk4RangeRate 1;
BA_ "SignalType" SG_ 1124 FLRRTrk4RangeAccel "SNM";
BA_ "SignalLongName" SG_ 1124 FLRRTrk4RangeAccel "Front Long Range Radar Track 4 Range Acceleration";
BA_ "VNSigAllNodes" SG_ 1124 FLRRTrk4RangeAccel 1;
BA_ "SignalType" SG_ 1124 FLRRTrk4DynProp "ENM";
BA_ "SignalLongName" SG_ 1124 FLRRTrk4DynProp "Front Long Range Radar Dynamic Property Track 4";
BA_ "VNSigAllNodes" SG_ 1124 FLRRTrk4DynProp 1;
BA_ "SignalType" SG_ 1124 FLRRTrk4Azimuth "SNM";
BA_ "SignalLongName" SG_ 1124 FLRRTrk4Azimuth "Front Long Range Radar Azimuth Track 4";
BA_ "VNSigAllNodes" SG_ 1124 FLRRTrk4Azimuth 1;
BA_ "SignalType" SG_ 1124 FLRRTrk4Width "UNM";
BA_ "SignalLongName" SG_ 1124 FLRRTrk4Width "Front Long Range Radar Track 4 Width";
BA_ "GenSigStartValue" SG_ 1124 FLRRTrk4Width 1;
BA_ "VNSigAllNodes" SG_ 1124 FLRRTrk4Width 1;
BA_ "SignalType" SG_ 1124 FLRRTrk4MeasStatus "ENM";
BA_ "SignalLongName" SG_ 1124 FLRRTrk4MeasStatus "Front Long Range Radar Measurement Status Track 4";
BA_ "VNSigAllNodes" SG_ 1124 FLRRTrk4MeasStatus 1;
BA_ "SignalType" SG_ 1124 FLRRTrk4ObjectID "UNM";
BA_ "SignalLongName" SG_ 1124 FLRRTrk4ObjectID "Front Long Range Radar Track 4 Object ID";
BA_ "VNSigAllNodes" SG_ 1124 FLRRTrk4ObjectID 1;
BA_ "SignalType" SG_ 1124 FLRRTrk4Conf "ENM";
BA_ "SignalLongName" SG_ 1124 FLRRTrk4Conf "Front Long Range Radar Track 4 Confidence";
BA_ "VNSigAllNodes" SG_ 1124 FLRRTrk4Conf 1;
BA_ "SignalType" SG_ 1123 FLRRTrk3BurstID "UNM";
BA_ "SignalLongName" SG_ 1123 FLRRTrk3BurstID "Front Long Range Radar Track 3 Burst ID";
BA_ "VNSigAllNodes" SG_ 1123 FLRRTrk3BurstID 1;
BA_ "SignalType" SG_ 1123 FLRRTrk3Range "UNM";
BA_ "SignalLongName" SG_ 1123 FLRRTrk3Range "Front Long Range Radar Track 3 Range";
BA_ "GenSigStartValue" SG_ 1123 FLRRTrk3Range 1;
BA_ "VNSigAllNodes" SG_ 1123 FLRRTrk3Range 1;
BA_ "SignalType" SG_ 1123 FLRRTrk3RangeRate "SNM";
BA_ "SignalLongName" SG_ 1123 FLRRTrk3RangeRate "Front Long Range Radar Track 3 Range Rate";
BA_ "VNSigAllNodes" SG_ 1123 FLRRTrk3RangeRate 1;
BA_ "SignalType" SG_ 1123 FLRRTrk3RangeAccel "SNM";
BA_ "SignalLongName" SG_ 1123 FLRRTrk3RangeAccel "Front Long Range Radar Track 3 Range Acceleration";
BA_ "VNSigAllNodes" SG_ 1123 FLRRTrk3RangeAccel 1;
BA_ "SignalType" SG_ 1123 FLRRTrk3DynProp "ENM";
BA_ "SignalLongName" SG_ 1123 FLRRTrk3DynProp "Front Long Range Radar Dynamic Property Track 3";
BA_ "VNSigAllNodes" SG_ 1123 FLRRTrk3DynProp 1;
BA_ "SignalType" SG_ 1123 FLRRTrk3Azimuth "SNM";
BA_ "SignalLongName" SG_ 1123 FLRRTrk3Azimuth "Front Long Range Radar Azimuth Track 3";
BA_ "VNSigAllNodes" SG_ 1123 FLRRTrk3Azimuth 1;
BA_ "SignalType" SG_ 1123 FLRRTrk3Width "UNM";
BA_ "SignalLongName" SG_ 1123 FLRRTrk3Width "Front Long Range Radar Track 3 Width";
BA_ "GenSigStartValue" SG_ 1123 FLRRTrk3Width 1;
BA_ "VNSigAllNodes" SG_ 1123 FLRRTrk3Width 1;
BA_ "SignalType" SG_ 1123 FLRRTrk3MeasStatus "ENM";
BA_ "SignalLongName" SG_ 1123 FLRRTrk3MeasStatus "Front Long Range Radar Measurement Status Track 3";
BA_ "VNSigAllNodes" SG_ 1123 FLRRTrk3MeasStatus 1;
BA_ "SignalType" SG_ 1123 FLRRTrk3ObjectID "UNM";
BA_ "SignalLongName" SG_ 1123 FLRRTrk3ObjectID "Front Long Range Radar Track 3 Object ID";
BA_ "VNSigAllNodes" SG_ 1123 FLRRTrk3ObjectID 1;
BA_ "SignalType" SG_ 1123 FLRRTrk3Conf "ENM";
BA_ "SignalLongName" SG_ 1123 FLRRTrk3Conf "Front Long Range Radar Track 3 Confidence";
BA_ "VNSigAllNodes" SG_ 1123 FLRRTrk3Conf 1;
BA_ "SignalType" SG_ 1122 FLRRTrk2BurstID "UNM";
BA_ "SignalLongName" SG_ 1122 FLRRTrk2BurstID "Front Long Range Radar Track 2 Burst ID";
BA_ "VNSigAllNodes" SG_ 1122 FLRRTrk2BurstID 1;
BA_ "SignalType" SG_ 1122 FLRRTrk2Range "UNM";
BA_ "SignalLongName" SG_ 1122 FLRRTrk2Range "Front Long Range Radar Track 2 Range";
BA_ "GenSigStartValue" SG_ 1122 FLRRTrk2Range 1;
BA_ "VNSigAllNodes" SG_ 1122 FLRRTrk2Range 1;
BA_ "SignalType" SG_ 1122 FLRRTrk2RangeRate "SNM";
BA_ "SignalLongName" SG_ 1122 FLRRTrk2RangeRate "Front Long Range Radar Track 2 Range Rate";
BA_ "VNSigAllNodes" SG_ 1122 FLRRTrk2RangeRate 1;
BA_ "SignalType" SG_ 1122 FLRRTrk2RangeAccel "SNM";
BA_ "SignalLongName" SG_ 1122 FLRRTrk2RangeAccel "Front Long Range Radar Track 2 Range Acceleration";
BA_ "VNSigAllNodes" SG_ 1122 FLRRTrk2RangeAccel 1;
BA_ "SignalType" SG_ 1122 FLRRTrk2DynProp "ENM";
BA_ "SignalLongName" SG_ 1122 FLRRTrk2DynProp "Front Long Range Radar Dynamic Property Track 2";
BA_ "VNSigAllNodes" SG_ 1122 FLRRTrk2DynProp 1;
BA_ "SignalType" SG_ 1122 FLRRTrk2Azimuth "SNM";
BA_ "SignalLongName" SG_ 1122 FLRRTrk2Azimuth "Front Long Range Radar Azimuth Track 2";
BA_ "VNSigAllNodes" SG_ 1122 FLRRTrk2Azimuth 1;
BA_ "SignalType" SG_ 1122 FLRRTrk2Width "UNM";
BA_ "SignalLongName" SG_ 1122 FLRRTrk2Width "Front Long Range Radar Track 2 Width";
BA_ "GenSigStartValue" SG_ 1122 FLRRTrk2Width 1;
BA_ "VNSigAllNodes" SG_ 1122 FLRRTrk2Width 1;
BA_ "SignalType" SG_ 1122 FLRRTrk2MeasStatus "ENM";
BA_ "SignalLongName" SG_ 1122 FLRRTrk2MeasStatus "Front Long Range Radar Measurement Status Track 2";
BA_ "VNSigAllNodes" SG_ 1122 FLRRTrk2MeasStatus 1;
BA_ "SignalType" SG_ 1122 FLRRTrk2ObjectID "UNM";
BA_ "SignalLongName" SG_ 1122 FLRRTrk2ObjectID "Front Long Range Radar Track 2 Object ID";
BA_ "VNSigAllNodes" SG_ 1122 FLRRTrk2ObjectID 1;
BA_ "SignalType" SG_ 1122 FLRRTrk2Conf "ENM";
BA_ "SignalLongName" SG_ 1122 FLRRTrk2Conf "Front Long Range Radar Track 2 Confidence";
BA_ "VNSigAllNodes" SG_ 1122 FLRRTrk2Conf 1;
BA_ "SignalType" SG_ 1121 FLRRTrk1BurstID "UNM";
BA_ "SignalLongName" SG_ 1121 FLRRTrk1BurstID "Front Long Range Radar Track 1 Burst ID";
BA_ "VNSigAllNodes" SG_ 1121 FLRRTrk1BurstID 1;
BA_ "SignalType" SG_ 1121 FLRRTrk1Range "UNM";
BA_ "SignalLongName" SG_ 1121 FLRRTrk1Range "Front Long Range Radar Track 1 Range";
BA_ "GenSigStartValue" SG_ 1121 FLRRTrk1Range 1;
BA_ "VNSigAllNodes" SG_ 1121 FLRRTrk1Range 1;
BA_ "SignalType" SG_ 1121 FLRRTrk1RangeRate "SNM";
BA_ "SignalLongName" SG_ 1121 FLRRTrk1RangeRate "Front Long Range Radar Track 1 Range Rate";
BA_ "VNSigAllNodes" SG_ 1121 FLRRTrk1RangeRate 1;
BA_ "SignalType" SG_ 1121 FLRRTrk1RangeAccel "SNM";
BA_ "SignalLongName" SG_ 1121 FLRRTrk1RangeAccel "Front Long Range Radar Track 1 Range Acceleration";
BA_ "VNSigAllNodes" SG_ 1121 FLRRTrk1RangeAccel 1;
BA_ "SignalType" SG_ 1121 FLRRTrk1DynProp "ENM";
BA_ "SignalLongName" SG_ 1121 FLRRTrk1DynProp "Front Long Range Radar Dynamic Property Track 1 ";
BA_ "VNSigAllNodes" SG_ 1121 FLRRTrk1DynProp 1;
BA_ "SignalType" SG_ 1121 FLRRTrk1Azimuth "SNM";
BA_ "SignalLongName" SG_ 1121 FLRRTrk1Azimuth "Front Long Range Radar Azimuth Track 1";
BA_ "VNSigAllNodes" SG_ 1121 FLRRTrk1Azimuth 1;
BA_ "SignalType" SG_ 1121 FLRRTrk1Width "UNM";
BA_ "SignalLongName" SG_ 1121 FLRRTrk1Width "Front Long Range Radar Track 1 Width";
BA_ "GenSigStartValue" SG_ 1121 FLRRTrk1Width 1;
BA_ "VNSigAllNodes" SG_ 1121 FLRRTrk1Width 1;
BA_ "SignalType" SG_ 1121 FLRRTrk1MeasStatus "ENM";
BA_ "SignalLongName" SG_ 1121 FLRRTrk1MeasStatus "Front Long Range Radar Measurement Status Track 1";
BA_ "VNSigAllNodes" SG_ 1121 FLRRTrk1MeasStatus 1;
BA_ "SignalType" SG_ 1121 FLRRTrk1ObjectID "UNM";
BA_ "SignalLongName" SG_ 1121 FLRRTrk1ObjectID "Front Long Range Radar Track 1 Object ID";
BA_ "VNSigAllNodes" SG_ 1121 FLRRTrk1ObjectID 1;
BA_ "SignalType" SG_ 1121 FLRRTrk1Conf "ENM";
BA_ "SignalLongName" SG_ 1121 FLRRTrk1Conf "Front Long Range Radar Track 1 Confidence";
BA_ "VNSigAllNodes" SG_ 1121 FLRRTrk1Conf 1;
BA_ "SignalType" SG_ 1120 FLRRDiagSpare "BLN";
BA_ "PacketOrder" SG_ 1120 FLRRDiagSpare 1;
BA_ "SignalLongName" SG_ 1120 FLRRDiagSpare "Front Long Range Radar Diagnostic Spare";
BA_ "VNSigAllNodes" SG_ 1120 FLRRDiagSpare 1;
BA_ "SignalType" SG_ 1120 FLRRVltgOutRngLo "BLN";
BA_ "PacketOrder" SG_ 1120 FLRRVltgOutRngLo 19;
BA_ "SignalLongName" SG_ 1120 FLRRVltgOutRngLo "Front Long Range Radar Voltage Out Of Range Low";
BA_ "VNSigAllNodes" SG_ 1120 FLRRVltgOutRngLo 1;
BA_ "SignalType" SG_ 1120 FLRRVltgOutRngHi "BLN";
BA_ "PacketOrder" SG_ 1120 FLRRVltgOutRngHi 20;
BA_ "SignalLongName" SG_ 1120 FLRRVltgOutRngHi "Front Long Range Radar Voltage out of Range High";
BA_ "VNSigAllNodes" SG_ 1120 FLRRVltgOutRngHi 1;
BA_ "SignalType" SG_ 1120 FLRRSvcAlgnInPrcs "BLN";
BA_ "PacketOrder" SG_ 1120 FLRRSvcAlgnInPrcs 9;
BA_ "SignalLongName" SG_ 1120 FLRRSvcAlgnInPrcs "Front Long Range Radar Service Alignment in Process";
BA_ "VNSigAllNodes" SG_ 1120 FLRRSvcAlgnInPrcs 1;
BA_ "SignalType" SG_ 1120 FLRRSnsrBlckd "BLN";
BA_ "PacketOrder" SG_ 1120 FLRRSnsrBlckd 18;
BA_ "SignalLongName" SG_ 1120 FLRRSnsrBlckd "Front Long Range Radar Sensor Blocked";
BA_ "VNSigAllNodes" SG_ 1120 FLRRSnsrBlckd 1;
BA_ "SignalType" SG_ 1120 FLRRSnstvFltPrsntInt "BLN";
BA_ "PacketOrder" SG_ 1120 FLRRSnstvFltPrsntInt 7;
BA_ "SignalLongName" SG_ 1120 FLRRSnstvFltPrsntInt "Front Long Range Radar Sensitivity Fault Present, Internal";
BA_ "VNSigAllNodes" SG_ 1120 FLRRSnstvFltPrsntInt 1;
BA_ "SignalType" SG_ 1120 FLRRPlntAlgnInProc "BLN";
BA_ "PacketOrder" SG_ 1120 FLRRPlntAlgnInProc 10;
BA_ "SignalLongName" SG_ 1120 FLRRPlntAlgnInProc "Front Long Range Radar Plant Alignment in Process";
BA_ "VNSigAllNodes" SG_ 1120 FLRRPlntAlgnInProc 1;
BA_ "SignalType" SG_ 1120 FLRRMsalgnYawRt "BLN";
BA_ "PacketOrder" SG_ 1120 FLRRMsalgnYawRt 16;
BA_ "SignalLongName" SG_ 1120 FLRRMsalgnYawRt "Front Long Range Radar Misalignment Yaw Right";
BA_ "VNSigAllNodes" SG_ 1120 FLRRMsalgnYawRt 1;
BA_ "SignalType" SG_ 1120 FLRRMsalgnYawLt "BLN";
BA_ "PacketOrder" SG_ 1120 FLRRMsalgnYawLt 17;
BA_ "SignalLongName" SG_ 1120 FLRRMsalgnYawLt "Front Long Range Radar Misalignment Yaw Left";
BA_ "VNSigAllNodes" SG_ 1120 FLRRMsalgnYawLt 1;
BA_ "SignalType" SG_ 1120 FLRRLonVelPlsblityFlt "BLN";
BA_ "PacketOrder" SG_ 1120 FLRRLonVelPlsblityFlt 12;
BA_ "SignalLongName" SG_ 1120 FLRRLonVelPlsblityFlt "Front Long Range Radar Longitudinal Velocity Plausibility Fault";
BA_ "VNSigAllNodes" SG_ 1120 FLRRLonVelPlsblityFlt 1;
BA_ "SignalType" SG_ 1120 FLRRYawRtPlsblityFlt "BLN";
BA_ "PacketOrder" SG_ 1120 FLRRYawRtPlsblityFlt 13;
BA_ "SignalLongName" SG_ 1120 FLRRYawRtPlsblityFlt "Front Long Range Radar Yaw Rate Plausibility Fault";
BA_ "VNSigAllNodes" SG_ 1120 FLRRYawRtPlsblityFlt 1;
BA_ "SignalType" SG_ 1120 FLRRMsalgnPtchUp "BLN";
BA_ "PacketOrder" SG_ 1120 FLRRMsalgnPtchUp 15;
BA_ "SignalLongName" SG_ 1120 FLRRMsalgnPtchUp "Front Long Range Radar Misalignment Pitch Up";
BA_ "VNSigAllNodes" SG_ 1120 FLRRMsalgnPtchUp 1;
BA_ "SignalType" SG_ 1120 FLRRMsalgnPtchDn "BLN";
BA_ "PacketOrder" SG_ 1120 FLRRMsalgnPtchDn 14;
BA_ "SignalLongName" SG_ 1120 FLRRMsalgnPtchDn "Front Long Range Radar Misalignment Pitch Down";
BA_ "VNSigAllNodes" SG_ 1120 FLRRMsalgnPtchDn 1;
BA_ "SignalType" SG_ 1120 FLRRInitDiagCmplt "BLN";
BA_ "PacketOrder" SG_ 1120 FLRRInitDiagCmplt 23;
BA_ "SignalLongName" SG_ 1120 FLRRInitDiagCmplt "Front Long Range Radar Initialization Diagnostics Successfully Completed";
BA_ "VNSigAllNodes" SG_ 1120 FLRRInitDiagCmplt 1;
BA_ "SignalType" SG_ 1120 FLRRHWFltPrsntInt "BLN";
BA_ "PacketOrder" SG_ 1120 FLRRHWFltPrsntInt 6;
BA_ "SignalLongName" SG_ 1120 FLRRHWFltPrsntInt "Front Long Range Radar Hardware Fault Present, Internal";
BA_ "VNSigAllNodes" SG_ 1120 FLRRHWFltPrsntInt 1;
BA_ "SignalType" SG_ 1120 FLRRExtIntrfrnc "BLN";
BA_ "PacketOrder" SG_ 1120 FLRRExtIntrfrnc 11;
BA_ "SignalLongName" SG_ 1120 FLRRExtIntrfrnc "Front Long Range Radar External Interference";
BA_ "VNSigAllNodes" SG_ 1120 FLRRExtIntrfrnc 1;
BA_ "SignalType" SG_ 1120 FLRRCANSgnlSpvFld "BLN";
BA_ "PacketOrder" SG_ 1120 FLRRCANSgnlSpvFld 2;
BA_ "SignalLongName" SG_ 1120 FLRRCANSgnlSpvFld "Front Long Range Radar CAN Signal Supervision Failed";
BA_ "VNSigAllNodes" SG_ 1120 FLRRCANSgnlSpvFld 1;
BA_ "SignalType" SG_ 1120 FLRRCANRxErr "BLN";
BA_ "PacketOrder" SG_ 1120 FLRRCANRxErr 3;
BA_ "SignalLongName" SG_ 1120 FLRRCANRxErr "Front Long Range Radar CAN Rx Error";
BA_ "VNSigAllNodes" SG_ 1120 FLRRCANRxErr 1;
BA_ "SignalType" SG_ 1120 FLRRTunlDtctd "BLN";
BA_ "PacketOrder" SG_ 1120 FLRRTunlDtctd 4;
BA_ "SignalLongName" SG_ 1120 FLRRTunlDtctd "Front Long Range Radar Tunnel Detected";
BA_ "VNSigAllNodes" SG_ 1120 FLRRTunlDtctd 1;
BA_ "SignalType" SG_ 1120 FLRRAmbTmpOutRngLw "BLN";
BA_ "PacketOrder" SG_ 1120 FLRRAmbTmpOutRngLw 21;
BA_ "SignalLongName" SG_ 1120 FLRRAmbTmpOutRngLw "Front Long Range Radar Ambient Temperature Out of Range Low";
BA_ "VNSigAllNodes" SG_ 1120 FLRRAmbTmpOutRngLw 1;
BA_ "SignalType" SG_ 1120 FLRRAmbTmpOutRngHi "BLN";
BA_ "PacketOrder" SG_ 1120 FLRRAmbTmpOutRngHi 22;
BA_ "SignalLongName" SG_ 1120 FLRRAmbTmpOutRngHi "Front Long Range Radar Ambient Temperature Out of Range High";
BA_ "VNSigAllNodes" SG_ 1120 FLRRAmbTmpOutRngHi 1;
BA_ "SignalType" SG_ 1120 FLRRAntTngFltPrsnt "BLN";
BA_ "PacketOrder" SG_ 1120 FLRRAntTngFltPrsnt 5;
BA_ "SignalLongName" SG_ 1120 FLRRAntTngFltPrsnt "Front Long Range Radar Antenna Tuning Fault Present";
BA_ "VNSigAllNodes" SG_ 1120 FLRRAntTngFltPrsnt 1;
BA_ "SignalType" SG_ 1120 FLRRAlgnFltPrsnt "BLN";
BA_ "PacketOrder" SG_ 1120 FLRRAlgnFltPrsnt 8;
BA_ "SignalLongName" SG_ 1120 FLRRAlgnFltPrsnt "Front Long Range Radar Alignment Fault Present";
BA_ "VNSigAllNodes" SG_ 1120 FLRRAlgnFltPrsnt 1;
BA_ "SignalType" SG_ 1120 FLRRRollingCount "UNM";
BA_ "SignalLongName" SG_ 1120 FLRRRollingCount "Front Long Range Radar Rolling Count";
BA_ "VNSigAllNodes" SG_ 1120 FLRRRollingCount 1;
BA_ "SignalType" SG_ 1120 FLRRModeCmdFdbk "ENM";
BA_ "SignalLongName" SG_ 1120 FLRRModeCmdFdbk "Front Long Range Radar Sensor Mode Comand Status";
BA_ "VNSigAllNodes" SG_ 1120 FLRRModeCmdFdbk 1;
BA_ "SignalType" SG_ 1120 FLRRNumValidTargets "UNM";
BA_ "SignalLongName" SG_ 1120 FLRRNumValidTargets "Front Long Range Radar Number of Valid Targets";
BA_ "VNSigAllNodes" SG_ 1120 FLRRNumValidTargets 1;
BA_ "SignalType" SG_ 1120 FLRRTimeStampV "ENM";
BA_ "SignalLongName" SG_ 1120 FLRRTimeStampV "Front Long Range Radar Time Stamp Validity";
BA_ "VNSigAllNodes" SG_ 1120 FLRRTimeStampV 1;
BA_ "SignalType" SG_ 1120 FLRRTimeStamp "UNM";
BA_ "SignalLongName" SG_ 1120 FLRRTimeStamp "Front Long Range Radar Time Stamp";
BA_ "VNSigAllNodes" SG_ 1120 FLRRTimeStamp 1;
BA_ "SignalType" SG_ 1120 FLRRRoadTypeInfo "ENM";
BA_ "SignalLongName" SG_ 1120 FLRRRoadTypeInfo "Front Long Range Radar Road type information";
BA_ "VNSigAllNodes" SG_ 1120 FLRRRoadTypeInfo 1;
BA_ "SignalType" SG_ 1120 FLRRBurstChecksum "UNM";
BA_ "SignalLongName" SG_ 1120 FLRRBurstChecksum "Front Long Range Radar Burst Checksum";
BA_ "VNSigAllNodes" SG_ 1120 FLRRBurstChecksum 1;
BA_ "VNSigSLHSSharedDiagnostic" SG_ 1625 DgnInf 1;
BA_ "SignalType" SG_ 1625 DgnInf "UNM";
BA_ "SignalLongName" SG_ 1625 DgnInf "Diagnostic Information";
BA_ "VNSigAllNodes" SG_ 1625 DgnInf 1;
BA_ "VNSigSLHSSharedDiagnostic" SG_ 1602 DgnInf 1;
BA_ "SignalType" SG_ 1602 DgnInf "UNM";
BA_ "SignalLongName" SG_ 1602 DgnInf "Diagnostic Information";
BA_ "VNSigAllNodes" SG_ 1602 DgnInf 1;
VAL_ 1923 DTCI_WrnIndRqdSt_783 1 "true" 0 "false" ;
VAL_ 1923 DTCI_TstNPsdPwrUpSt_783 1 "true" 0 "false" ;
VAL_ 1923 DTCI_TstNPsdCdClrdSt_783 1 "true" 0 "false" ;
VAL_ 1923 DTCI_TstFldPwrUpSt_783 1 "true" 0 "false" ;
VAL_ 1923 DTCI_TstFldCdClrdStat_783 1 "true" 0 "false" ;
VAL_ 1923 DTCI_HistStat_783 1 "true" 0 "false" ;
VAL_ 1923 DTCI_DTCTriggered_783 1 "true" 0 "false" ;
VAL_ 1923 DTCI_DTCFaultType_783 3 "Type C" 2 "Type B" 1 "Type A" 0 "Not Supported" ;
VAL_ 1923 DTCI_CurrentStatus_783 1 "true" 0 "false" ;
VAL_ 1923 DTCI_CodeSupported_783 1 "true" 0 "false" ;
VAL_ 1923 DTCIUnused7_783 1 "true" 0 "false" ;
VAL_ 1923 DTCIUnused6_783 1 "true" 0 "false" ;
VAL_ 1923 DTCIUnused5_783 1 "true" 0 "false" ;
VAL_ 1923 DTCIUnused4_783 1 "true" 0 "false" ;
VAL_ 1923 DTCIUnused3_783 1 "true" 0 "false" ;
VAL_ 1923 DTCIUnused2_783 1 "true" 0 "false" ;
VAL_ 1923 DTCIUnused1_783 1 "true" 0 "false" ;
VAL_ 1920 DTCI_CurrentStatus_780 1 "true" 0 "false" ;
VAL_ 1920 DTCI_WrnIndRqdSt_780 1 "true" 0 "false" ;
VAL_ 1920 DTCIUnused7_780 1 "true" 0 "false" ;
VAL_ 1920 DTCIUnused6_780 1 "true" 0 "false" ;
VAL_ 1920 DTCIUnused5_780 1 "true" 0 "false" ;
VAL_ 1920 DTCIUnused4_780 1 "true" 0 "false" ;
VAL_ 1920 DTCIUnused3_780 1 "true" 0 "false" ;
VAL_ 1920 DTCIUnused2_780 1 "true" 0 "false" ;
VAL_ 1920 DTCIUnused1_780 1 "true" 0 "false" ;
VAL_ 1920 DTCI_TstNPsdPwrUpSt_780 1 "true" 0 "false" ;
VAL_ 1920 DTCI_TstNPsdCdClrdSt_780 1 "true" 0 "false" ;
VAL_ 1920 DTCI_TstFldPwrUpSt_780 1 "true" 0 "false" ;
VAL_ 1920 DTCI_TstFldCdClrdStat_780 1 "true" 0 "false" ;
VAL_ 1920 DTCI_HistStat_780 1 "true" 0 "false" ;
VAL_ 1920 DTCI_DTCTriggered_780 1 "true" 0 "false" ;
VAL_ 1920 DTCI_DTCFaultType_780 3 "Type C" 2 "Type B" 1 "Type A" 0 "Not Supported" ;
VAL_ 1920 DTCI_CodeSupported_780 1 "true" 0 "false" ;
VAL_ 1194 RSrrTrkObjElevation10 3 "Low " 2 "mid (reserved)" 1 "high " 0 "Unknown" ;
VAL_ 1194 RSrrTrkDynamProp10 4 "Moving in opposite direction" 3 "Moving in same direction as host" 2 "Has moved but currently stopped" 1 "Has never moved" 0 "Unknown" ;
VAL_ 1194 RSrrTrkMeasStatus10 3 "Measured this cycle" 2 "Latent track not detctd this cyc" 1 "New Object" 0 "No Object" ;
VAL_ 1193 RSrrTrkObjElevation9 3 "Low " 2 "mid (reserved)" 1 "high " 0 "Unknown" ;
VAL_ 1193 RSrrTrkDynamProp9 4 "Moving in opposite direction" 3 "Moving in same direction as host" 2 "Has moved but currently stopped" 1 "Has never moved" 0 "Unknown" ;
VAL_ 1193 RSrrTrkMeasStatus9 3 "Measured this cycle" 2 "Latent track not detctd this cyc" 1 "New Object" 0 "No Object" ;
VAL_ 1192 RSrrTrkObjElevation8 3 "Low " 2 "mid (reserved)" 1 "high " 0 "Unknown" ;
VAL_ 1192 RSrrTrkDynamProp8 4 "Moving in opposite direction" 3 "Moving in same direction as host" 2 "Has moved but currently stopped" 1 "Has never moved" 0 "Unknown" ;
VAL_ 1192 RSrrTrkMeasStatus8 3 "Measured this cycle" 2 "Latent track not detctd this cyc" 1 "New Object" 0 "No Object" ;
VAL_ 1191 RSrrTrkObjElevation7 3 "Low " 2 "mid (reserved)" 1 "high " 0 "Unknown" ;
VAL_ 1191 RSrrTrkDynamProp7 4 "Moving in opposite direction" 3 "Moving in same direction as host" 2 "Has moved but currently stopped" 1 "Has never moved" 0 "Unknown" ;
VAL_ 1191 RSrrTrkMeasStatus7 3 "Measured this cycle" 2 "Latent track not detctd this cyc" 1 "New Object" 0 "No Object" ;
VAL_ 1190 RSrrTrkObjElevation6 3 "Low " 2 "mid (reserved)" 1 "high " 0 "Unknown" ;
VAL_ 1190 RSrrTrkDynamProp6 4 "Moving in opposite direction" 3 "Moving in same direction as host" 2 "Has moved but currently stopped" 1 "Has never moved" 0 "Unknown" ;
VAL_ 1190 RSrrTrkMeasStatus6 3 "Measured this cycle" 2 "Latent track not detctd this cyc" 1 "New Object" 0 "No Object" ;
VAL_ 1189 RSrrTrkObjElevation5 3 "Low " 2 "mid (reserved)" 1 "high " 0 "Unknown" ;
VAL_ 1189 RSrrTrkDynamProp5 4 "Moving in opposite direction" 3 "Moving in same direction as host" 2 "Has moved but currently stopped" 1 "Has never moved" 0 "Unknown" ;
VAL_ 1189 RSrrTrkMeasStatus5 3 "Measured this cycle" 2 "Latent track not detctd this cyc" 1 "New Object" 0 "No Object" ;
VAL_ 1188 RSrrTrkObjElevation4 3 "Low " 2 "mid (reserved)" 1 "high " 0 "Unknown" ;
VAL_ 1188 RSrrTrkDynamProp4 4 "Moving in opposite direction" 3 "Moving in same direction as host" 2 "Has moved but currently stopped" 1 "Has never moved" 0 "Unknown" ;
VAL_ 1188 RSrrTrkMeasStatus4 3 "Measured this cycle" 2 "Latent track not detctd this cyc" 1 "New Object" 0 "No Object" ;
VAL_ 1187 RSrrTrkObjElevation3 3 "Low " 2 "mid (reserved)" 1 "high " 0 "Unknown" ;
VAL_ 1187 RSrrTrkDynamProp3 4 "Moving in opposite direction" 3 "Moving in same direction as host" 2 "Has moved but currently stopped" 1 "Has never moved" 0 "Unknown" ;
VAL_ 1187 RSrrTrkMeasStatus3 3 "Measured this cycle" 2 "Latent track not detctd this cyc" 1 "New Object" 0 "No Object" ;
VAL_ 1186 RSrrTrkObjElevation2 3 "Low " 2 "mid (reserved)" 1 "high " 0 "Unknown" ;
VAL_ 1186 RSrrTrkDynamProp2 4 "Moving in opposite direction" 3 "Moving in same direction as host" 2 "Has moved but currently stopped" 1 "Has never moved" 0 "Unknown" ;
VAL_ 1186 RSrrTrkMeasStatus2 3 "Measured this cycle" 2 "Latent track not detctd this cyc" 1 "New Object" 0 "No Object" ;
VAL_ 1185 RSrrTrkObjElevation1 3 "Low " 2 "mid (reserved)" 1 "high " 0 "Unknown" ;
VAL_ 1185 RSrrTrkDynamProp1 4 "Moving in opposite direction" 3 "Moving in same direction as host" 2 "Has moved but currently stopped" 1 "Has never moved" 0 "Unknown" ;
VAL_ 1185 RSrrTrkMeasStatus1 3 "Measured this cycle" 2 "Latent track not detctd this cyc" 1 "New Object" 0 "No Object" ;
VAL_ 1184 RSRRSnstvFltPrsntInt 1 "true" 0 "false" ;
VAL_ 1184 RSRRPlntAlgnInProc 1 "true" 0 "false" ;
VAL_ 1184 RSRRMsalgnYawRt 1 "true" 0 "false" ;
VAL_ 1184 RSRRMsalgnYawLt 1 "true" 0 "false" ;
VAL_ 1184 RSRRMsalgnRllRt 1 "true" 0 "false" ;
VAL_ 1184 RSRRMsalgnRllLt 1 "true" 0 "false" ;
VAL_ 1184 RSRRMsalgnPtchUp 1 "true" 0 "false" ;
VAL_ 1184 RSRRMsalgnPtchDn 1 "true" 0 "false" ;
VAL_ 1184 RSRRInitDiagCmplt 1 "true" 0 "false" ;
VAL_ 1184 RSRRHWFltPrsntInt 1 "true" 0 "false" ;
VAL_ 1184 RSRRExtIntrfrnc 1 "true" 0 "false" ;
VAL_ 1184 RSRRDiagSpare 1 "true" 0 "false" ;
VAL_ 1184 RSRRCANSgnlSpvFld 1 "true" 0 "false" ;
VAL_ 1184 RSRRCANRxErr 1 "true" 0 "false" ;
VAL_ 1184 RSRRCANIDAddrsUnsbl 1 "true" 0 "false" ;
VAL_ 1184 RSRRAntTngFltPrsnt 1 "true" 0 "false" ;
VAL_ 1184 RSRRAmbTmpOutRngLw 1 "true" 0 "false" ;
VAL_ 1184 RSRRAmbTmpOutRngHi 1 "true" 0 "false" ;
VAL_ 1184 RSRRAlgnFltPrsnt 1 "true" 0 "false" ;
VAL_ 1184 RSRRVltgOutRngLo 1 "true" 0 "false" ;
VAL_ 1184 RSRRVltgOutRngHi 1 "true" 0 "false" ;
VAL_ 1184 RSRRSvcAlgnInPrcs 1 "true" 0 "false" ;
VAL_ 1184 RSRRSnsrBlckd 1 "true" 0 "false" ;
VAL_ 1184 RSRRModeCmdFdbk 5 "Sensing with reduced power" 4 "Undefined" 3 "Radio Silent" 2 "Sensing" 1 "Not Sensing" 0 "Undefined" ;
VAL_ 1184 RSrrTimeStampV 1 "Invalid" 0 "Valid" ;
VAL_ 1151 FrtRdrRdEdgLtTanHdgAngV 1 "Invalid" 0 "Valid" ;
VAL_ 1151 FrtRdrRdEdgLtCrvtV 1 "Invalid" 0 "Valid" ;
VAL_ 1151 FrtRdrRdEdgLtCrvtGradV 1 "Invalid" 0 "Valid" ;
VAL_ 1150 FrtRdrRdEdgRtTanHdgAngV 1 "Invalid" 0 "Valid" ;
VAL_ 1150 FrtRdrRdEdgRtCrvtV 1 "Invalid" 0 "Valid" ;
VAL_ 1150 FrtRdrRdEdgRtCrvtGradV 1 "Invalid" 0 "Valid" ;
VAL_ 1143 FLRRTrk20ObstType 6 "NO_OBJECT" 5 "OBJ_GUARDRAIL" 4 "OBJ_TUNNEL " 3 "OBJ_TRAFFIC_SIGN" 2 "OBJ_VEHICLE" 1 "OBJ_BRIDGE " 0 "OBJ_UNKNOWN" ;
VAL_ 1143 FLRRTrk19ObstType 6 "NO_OBJECT" 5 "OBJ_GUARDRAIL" 4 "OBJ_TUNNEL " 3 "OBJ_TRAFFIC_SIGN" 2 "OBJ_VEHICLE" 1 "OBJ_BRIDGE " 0 "OBJ_UNKNOWN" ;
VAL_ 1143 FLRRTrk18ObstType 6 "NO_OBJECT" 5 "OBJ_GUARDRAIL" 4 "OBJ_TUNNEL " 3 "OBJ_TRAFFIC_SIGN" 2 "OBJ_VEHICLE" 1 "OBJ_BRIDGE " 0 "OBJ_UNKNOWN" ;
VAL_ 1143 FLRRTrk17ObstType 6 "NO_OBJECT" 5 "OBJ_GUARDRAIL" 4 "OBJ_TUNNEL " 3 "OBJ_TRAFFIC_SIGN" 2 "OBJ_VEHICLE" 1 "OBJ_BRIDGE " 0 "OBJ_UNKNOWN" ;
VAL_ 1143 FLRRTrk16ObstType 6 "NO_OBJECT" 5 "OBJ_GUARDRAIL" 4 "OBJ_TUNNEL " 3 "OBJ_TRAFFIC_SIGN" 2 "OBJ_VEHICLE" 1 "OBJ_BRIDGE " 0 "OBJ_UNKNOWN" ;
VAL_ 1143 FLRRTrk15ObstType 6 "NO_OBJECT" 5 "OBJ_GUARDRAIL" 4 "OBJ_TUNNEL " 3 "OBJ_TRAFFIC_SIGN" 2 "OBJ_VEHICLE" 1 "OBJ_BRIDGE " 0 "OBJ_UNKNOWN" ;
VAL_ 1143 FLRRTrk14ObstType 6 "NO_OBJECT" 5 "OBJ_GUARDRAIL" 4 "OBJ_TUNNEL " 3 "OBJ_TRAFFIC_SIGN" 2 "OBJ_VEHICLE" 1 "OBJ_BRIDGE " 0 "OBJ_UNKNOWN" ;
VAL_ 1143 FLRRTrk13ObstType 6 "NO_OBJECT" 5 "OBJ_GUARDRAIL" 4 "OBJ_TUNNEL " 3 "OBJ_TRAFFIC_SIGN" 2 "OBJ_VEHICLE" 1 "OBJ_BRIDGE " 0 "OBJ_UNKNOWN" ;
VAL_ 1142 FLRRTrk12ObstType 6 "NO_OBJECT" 5 "OBJ_GUARDRAIL" 4 "OBJ_TUNNEL " 3 "OBJ_TRAFFIC_SIGN" 2 "OBJ_VEHICLE" 1 "OBJ_BRIDGE " 0 "OBJ_UNKNOWN" ;
VAL_ 1142 FLRRTrk11ObstType 6 "NO_OBJECT" 5 "OBJ_GUARDRAIL" 4 "OBJ_TUNNEL " 3 "OBJ_TRAFFIC_SIGN" 2 "OBJ_VEHICLE" 1 "OBJ_BRIDGE " 0 "OBJ_UNKNOWN" ;
VAL_ 1142 FLRRTrk10ObstType 6 "NO_OBJECT" 5 "OBJ_GUARDRAIL" 4 "OBJ_TUNNEL " 3 "OBJ_TRAFFIC_SIGN" 2 "OBJ_VEHICLE" 1 "OBJ_BRIDGE " 0 "OBJ_UNKNOWN" ;
VAL_ 1142 FLRRTrk9ObstType 6 "NO_OBJECT" 5 "OBJ_GUARDRAIL" 4 "OBJ_TUNNEL " 3 "OBJ_TRAFFIC_SIGN" 2 "OBJ_VEHICLE" 1 "OBJ_BRIDGE " 0 "OBJ_UNKNOWN" ;
VAL_ 1142 FLRRTrk8ObstType 6 "NO_OBJECT" 5 "OBJ_GUARDRAIL" 4 "OBJ_TUNNEL " 3 "OBJ_TRAFFIC_SIGN" 2 "OBJ_VEHICLE" 1 "OBJ_BRIDGE " 0 "OBJ_UNKNOWN" ;
VAL_ 1142 FLRRTrk7ObstType 6 "NO_OBJECT" 5 "OBJ_GUARDRAIL" 4 "OBJ_TUNNEL " 3 "OBJ_TRAFFIC_SIGN" 2 "OBJ_VEHICLE" 1 "OBJ_BRIDGE " 0 "OBJ_UNKNOWN" ;
VAL_ 1142 FLRRTrk1ObstType 6 "NO_OBJECT" 5 "OBJ_GUARDRAIL" 4 "OBJ_TUNNEL " 3 "OBJ_TRAFFIC_SIGN" 2 "OBJ_VEHICLE" 1 "OBJ_BRIDGE " 0 "OBJ_UNKNOWN" ;
VAL_ 1141 ObjLossInfoObjTrk1 2 "elevation conditions" 1 "tight curve" 0 "not lost" ;
VAL_ 1141 ObjLossInfoObjTrk2 2 "elevation conditions" 1 "tight curve" 0 "not lost" ;
VAL_ 1141 ObjLossInfoObjTrk3 2 "elevation conditions" 1 "tight curve" 0 "not lost" ;
VAL_ 1141 ObjLossInfoObjTrk4 2 "elevation conditions" 1 "tight curve" 0 "not lost" ;
VAL_ 1141 ObjLossInfoObjTrk5 2 "elevation conditions" 1 "tight curve" 0 "not lost" ;
VAL_ 1141 ObjLossInfoObjTrk6 2 "elevation conditions" 1 "tight curve" 0 "not lost" ;
VAL_ 1140 FLRRTrk20Conf 3 "confident" 2 "speculative" 1 "highly speculative" 0 "invalid" ;
VAL_ 1140 FLRRTrk20DynProp 4 "Moving in opposite direction" 3 "Moving in same direction as host" 2 "Has moved but currently stopped" 1 "Has never moved" 0 "Unknown" ;
VAL_ 1140 FLRRTrk20MeasStatus 3 "Measured this cycle" 2 "Latent track not detctd this cyc" 1 "New Object" 0 "No Object" ;
VAL_ 1139 FLRRTrk19Conf 3 "confident" 2 "speculative" 1 "highly speculative" 0 "invalid" ;
VAL_ 1139 FLRRTrk19DynProp 4 "Moving in opposite direction" 3 "Moving in same direction as host" 2 "Has moved but currently stopped" 1 "Has never moved" 0 "Unknown" ;
VAL_ 1139 FLRRTrk19MeasStatus 3 "Measured this cycle" 2 "Latent track not detctd this cyc" 1 "New Object" 0 "No Object" ;
VAL_ 1138 FLRRTrk18Conf 3 "confident" 2 "speculative" 1 "highly speculative" 0 "invalid" ;
VAL_ 1138 FLRRTrk18DynProp 4 "Moving in opposite direction" 3 "Moving in same direction as host" 2 "Has moved but currently stopped" 1 "Has never moved" 0 "Unknown" ;
VAL_ 1138 FLRRTrk18MeasStatus 3 "Measured this cycle" 2 "Latent track not detctd this cyc" 1 "New Object" 0 "No Object" ;
VAL_ 1137 FLRRTrk17Conf 3 "confident" 2 "speculative" 1 "highly speculative" 0 "invalid" ;
VAL_ 1137 FLRRTrk17DynProp 4 "Moving in opposite direction" 3 "Moving in same direction as host" 2 "Has moved but currently stopped" 1 "Has never moved" 0 "Unknown" ;
VAL_ 1137 FLRRTrk17MeasStatus 3 "Measured this cycle" 2 "Latent track not detctd this cyc" 1 "New Object" 0 "No Object" ;
VAL_ 1136 FLRRTrk16Conf 3 "confident" 2 "speculative" 1 "highly speculative" 0 "invalid" ;
VAL_ 1136 FLRRTrk16DynProp 4 "Moving in opposite direction" 3 "Moving in same direction as host" 2 "Has moved but currently stopped" 1 "Has never moved" 0 "Unknown" ;
VAL_ 1136 FLRRTrk16MeasStatus 3 "Measured this cycle" 2 "Latent track not detctd this cyc" 1 "New Object" 0 "No Object" ;
VAL_ 1135 FLRRTrk15MeasStatus 3 "Measured this cycle" 2 "Latent track not detctd this cyc" 1 "New Object" 0 "No Object" ;
VAL_ 1135 FLRRTrk15Conf 3 "confident" 2 "speculative" 1 "highly speculative" 0 "invalid" ;
VAL_ 1135 FLRRTrk15DynProp 4 "Moving in opposite direction" 3 "Moving in same direction as host" 2 "Has moved but currently stopped" 1 "Has never moved" 0 "Unknown" ;
VAL_ 1134 FLRRTrk14Conf 3 "confident" 2 "speculative" 1 "highly speculative" 0 "invalid" ;
VAL_ 1134 FLRRTrk14DynProp 4 "Moving in opposite direction" 3 "Moving in same direction as host" 2 "Has moved but currently stopped" 1 "Has never moved" 0 "Unknown" ;
VAL_ 1134 FLRRTrk14MeasStatus 3 "Measured this cycle" 2 "Latent track not detctd this cyc" 1 "New Object" 0 "No Object" ;
VAL_ 1133 FLRRTrk13Conf 3 "confident" 2 "speculative" 1 "highly speculative" 0 "invalid" ;
VAL_ 1133 FLRRTrk13DynProp 4 "Moving in opposite direction" 3 "Moving in same direction as host" 2 "Has moved but currently stopped" 1 "Has never moved" 0 "Unknown" ;
VAL_ 1133 FLRRTrk13MeasStatus 3 "Measured this cycle" 2 "Latent track not detctd this cyc" 1 "New Object" 0 "No Object" ;
VAL_ 1132 FLRRTrk12Conf 3 "confident" 2 "speculative" 1 "highly speculative" 0 "invalid" ;
VAL_ 1132 FLRRTrk12DynProp 4 "Moving in opposite direction" 3 "Moving in same direction as host" 2 "Has moved but currently stopped" 1 "Has never moved" 0 "Unknown" ;
VAL_ 1132 FLRRTrk12MeasStatus 3 "Measured this cycle" 2 "Latent track not detctd this cyc" 1 "New Object" 0 "No Object" ;
VAL_ 1131 FLRRTrk11Conf 3 "confident" 2 "speculative" 1 "highly speculative" 0 "invalid" ;
VAL_ 1131 FLRRTrk11DynProp 4 "Moving in opposite direction" 3 "Moving in same direction as host" 2 "Has moved but currently stopped" 1 "Has never moved" 0 "Unknown" ;
VAL_ 1131 FLRRTrk11MeasStatus 3 "Measured this cycle" 2 "Latent track not detctd this cyc" 1 "New Object" 0 "No Object" ;
VAL_ 1130 FLRRTrk10Conf 3 "confident" 2 "speculative" 1 "highly speculative" 0 "invalid" ;
VAL_ 1130 FLRRTrk10DynProp 4 "Moving in opposite direction" 3 "Moving in same direction as host" 2 "Has moved but currently stopped" 1 "Has never moved" 0 "Unknown" ;
VAL_ 1130 FLRRTrk10MeasStatus 3 "Measured this cycle" 2 "Latent track not detctd this cyc" 1 "New Object" 0 "No Object" ;
VAL_ 1129 FLRRTrk9Conf 3 "confident" 2 "speculative" 1 "highly speculative" 0 "invalid" ;
VAL_ 1129 FLRRTrk9DynProp 4 "Moving in opposite direction" 3 "Moving in same direction as host" 2 "Has moved but currently stopped" 1 "Has never moved" 0 "Unknown" ;
VAL_ 1129 FLRRTrk9MeasStatus 3 "Measured this cycle" 2 "Latent track not detctd this cyc" 1 "New Object" 0 "No Object" ;
VAL_ 1128 FLRRTrk8Conf 3 "confident" 2 "speculative" 1 "highly speculative" 0 "invalid" ;
VAL_ 1128 FLRRTrk8DynProp 4 "Moving in opposite direction" 3 "Moving in same direction as host" 2 "Has moved but currently stopped" 1 "Has never moved" 0 "Unknown" ;
VAL_ 1128 FLRRTrk8MeasStatus 3 "Measured this cycle" 2 "Latent track not detctd this cyc" 1 "New Object" 0 "No Object" ;
VAL_ 1127 FLRRTrk7Conf 3 "confident" 2 "speculative" 1 "highly speculative" 0 "invalid" ;
VAL_ 1127 FLRRTrk7DynProp 4 "Moving in opposite direction" 3 "Moving in same direction as host" 2 "Has moved but currently stopped" 1 "Has never moved" 0 "Unknown" ;
VAL_ 1127 FLRRTrk7MeasStatus 3 "Measured this cycle" 2 "Latent track not detctd this cyc" 1 "New Object" 0 "No Object" ;
VAL_ 1126 FLRRTrk6Conf 3 "confident" 2 "speculative" 1 "highly speculative" 0 "invalid" ;
VAL_ 1126 FLRRTrk6DynProp 4 "Moving in opposite direction" 3 "Moving in same direction as host" 2 "Has moved but currently stopped" 1 "Has never moved" 0 "Unknown" ;
VAL_ 1126 FLRRTrk6MeasStatus 3 "Measured this cycle" 2 "Latent track not detctd this cyc" 1 "New Object" 0 "No Object" ;
VAL_ 1125 FLRRTrk5DynProp 4 "Moving in opposite direction" 3 "Moving in same direction as host" 2 "Has moved but currently stopped" 1 "Has never moved" 0 "Unknown" ;
VAL_ 1125 FLRRTrk5MeasStatus 3 "Measured this cycle" 2 "Latent track not detctd this cyc" 1 "New Object" 0 "No Object" ;
VAL_ 1125 FLRRTrk5Conf 3 "confident" 2 "speculative" 1 "highly speculative" 0 "invalid" ;
VAL_ 1124 FLRRTrk4DynProp 4 "Moving in opposite direction" 3 "Moving in same direction as host" 2 "Has moved but currently stopped" 1 "Has never moved" 0 "Unknown" ;
VAL_ 1124 FLRRTrk4MeasStatus 3 "Measured this cycle" 2 "Latent track not detctd this cyc" 1 "New Object" 0 "No Object" ;
VAL_ 1124 FLRRTrk4Conf 3 "confident" 2 "speculative" 1 "highly speculative" 0 "invalid" ;
VAL_ 1123 FLRRTrk3DynProp 4 "Moving in opposite direction" 3 "Moving in same direction as host" 2 "Has moved but currently stopped" 1 "Has never moved" 0 "Unknown" ;
VAL_ 1123 FLRRTrk3MeasStatus 3 "Measured this cycle" 2 "Latent track not detctd this cyc" 1 "New Object" 0 "No Object" ;
VAL_ 1123 FLRRTrk3Conf 3 "confident" 2 "speculative" 1 "highly speculative" 0 "invalid" ;
VAL_ 1122 FLRRTrk2DynProp 4 "Moving in opposite direction" 3 "Moving in same direction as host" 2 "Has moved but currently stopped" 1 "Has never moved" 0 "Unknown" ;
VAL_ 1122 FLRRTrk2MeasStatus 3 "Measured this cycle" 2 "Latent track not detctd this cyc" 1 "New Object" 0 "No Object" ;
VAL_ 1122 FLRRTrk2Conf 3 "confident" 2 "speculative" 1 "highly speculative" 0 "invalid" ;
VAL_ 1121 FLRRTrk1DynProp 4 "Moving in opposite direction" 3 "Moving in same direction as host" 2 "Has moved but currently stopped" 1 "Has never moved" 0 "Unknown" ;
VAL_ 1121 FLRRTrk1MeasStatus 3 "Measured this cycle" 2 "Latent track not detctd this cyc" 1 "New Object" 0 "No Object" ;
VAL_ 1121 FLRRTrk1Conf 3 "confident" 2 "speculative" 1 "highly speculative" 0 "invalid" ;
VAL_ 1120 FLRRDiagSpare 1 "true" 0 "false" ;
VAL_ 1120 FLRRVltgOutRngLo 1 "true" 0 "false" ;
VAL_ 1120 FLRRVltgOutRngHi 1 "true" 0 "false" ;
VAL_ 1120 FLRRSvcAlgnInPrcs 1 "true" 0 "false" ;
VAL_ 1120 FLRRSnsrBlckd 1 "true" 0 "false" ;
VAL_ 1120 FLRRSnstvFltPrsntInt 1 "true" 0 "false" ;
VAL_ 1120 FLRRPlntAlgnInProc 1 "true" 0 "false" ;
VAL_ 1120 FLRRMsalgnYawRt 1 "true" 0 "false" ;
VAL_ 1120 FLRRMsalgnYawLt 1 "true" 0 "false" ;
VAL_ 1120 FLRRLonVelPlsblityFlt 1 "true" 0 "false" ;
VAL_ 1120 FLRRYawRtPlsblityFlt 1 "true" 0 "false" ;
VAL_ 1120 FLRRMsalgnPtchUp 1 "true" 0 "false" ;
VAL_ 1120 FLRRMsalgnPtchDn 1 "true" 0 "false" ;
VAL_ 1120 FLRRInitDiagCmplt 1 "true" 0 "false" ;
VAL_ 1120 FLRRHWFltPrsntInt 1 "true" 0 "false" ;
VAL_ 1120 FLRRExtIntrfrnc 1 "true" 0 "false" ;
VAL_ 1120 FLRRCANSgnlSpvFld 1 "true" 0 "false" ;
VAL_ 1120 FLRRCANRxErr 1 "true" 0 "false" ;
VAL_ 1120 FLRRTunlDtctd 1 "true" 0 "false" ;
VAL_ 1120 FLRRAmbTmpOutRngLw 1 "true" 0 "false" ;
VAL_ 1120 FLRRAmbTmpOutRngHi 1 "true" 0 "false" ;
VAL_ 1120 FLRRAntTngFltPrsnt 1 "true" 0 "false" ;
VAL_ 1120 FLRRAlgnFltPrsnt 1 "true" 0 "false" ;
VAL_ 1120 FLRRModeCmdFdbk 5 "Sensing with reduced power" 4 "Undefined" 3 "Radio Silent" 2 "Sensing" 1 "Not Sensing" 0 "Undefined" ;
VAL_ 1120 FLRRTimeStampV 1 "Invalid" 0 "Valid" ;
VAL_ 1120 FLRRRoadTypeInfo 5 "Constiction Zone Exit" 4 "Construction Zone Entry" 3 "Highway" 2 "Secondary Road" 1 "City" 0 "Unknown" ;
SIG_GROUP_ 1923 DTCInfo_783 1 : DTCI_WrnIndRqdSt_783 DTCI_TstNPsdPwrUpSt_783 DTCI_TstNPsdCdClrdSt_783 DTCI_TstFldPwrUpSt_783 DTCI_TstFldCdClrdStat_783 DTCI_HistStat_783 DTCI_DTCTriggered_783 DTCI_DTCSource_783 DTCI_DTCNumber_783 DTCI_DTCFaultType_783 DTCI_DTCFailType_783 DTCI_CurrentStatus_783 DTCI_CodeSupported_783 DTCIUnused7_783 DTCIUnused6_783 DTCIUnused5_783 DTCIUnused4_783 DTCIUnused3_783 DTCIUnused2_783 DTCIUnused1_783;
SIG_GROUP_ 1920 DTCInfo_780 1 : DTCI_CurrentStatus_780 DTCI_WrnIndRqdSt_780 DTCIUnused7_780 DTCIUnused6_780 DTCIUnused5_780 DTCIUnused4_780 DTCIUnused3_780 DTCIUnused2_780 DTCIUnused1_780 DTCI_TstNPsdPwrUpSt_780 DTCI_TstNPsdCdClrdSt_780 DTCI_TstFldPwrUpSt_780 DTCI_TstFldCdClrdStat_780 DTCI_HistStat_780 DTCI_DTCTriggered_780 DTCI_DTCSource_780 DTCI_DTCNumber_780 DTCI_DTCFaultType_780 DTCI_DTCFailType_780 DTCI_CodeSupported_780;
SIG_GROUP_ 1184 RSRRDiagStatus 1 : RSRRSnstvFltPrsntInt RSRRPlntAlgnInProc RSRRMsalgnYawRt RSRRMsalgnYawLt RSRRMsalgnRllRt RSRRMsalgnRllLt RSRRMsalgnPtchUp RSRRMsalgnPtchDn RSRRInitDiagCmplt RSRRHWFltPrsntInt RSRRExtIntrfrnc RSRRDiagSpare RSRRCANSgnlSpvFld RSRRCANRxErr RSRRCANIDAddrsUnsbl RSRRAntTngFltPrsnt RSRRAmbTmpOutRngLw RSRRAmbTmpOutRngHi RSRRAlgnFltPrsnt RSRRVltgOutRngLo RSRRVltgOutRngHi RSRRSvcAlgnInPrcs RSRRSnsrBlckd;
SIG_GROUP_ 1120 FLRRDiagStatus 1 : FLRRDiagSpare FLRRVltgOutRngLo FLRRVltgOutRngHi FLRRSvcAlgnInPrcs FLRRSnsrBlckd FLRRSnstvFltPrsntInt FLRRPlntAlgnInProc FLRRMsalgnYawRt FLRRMsalgnYawLt FLRRLonVelPlsblityFlt FLRRYawRtPlsblityFlt FLRRMsalgnPtchUp FLRRMsalgnPtchDn FLRRInitDiagCmplt FLRRHWFltPrsntInt FLRRExtIntrfrnc FLRRCANSgnlSpvFld FLRRCANRxErr FLRRTunlDtctd FLRRAmbTmpOutRngLw FLRRAmbTmpOutRngHi FLRRAntTngFltPrsnt FLRRAlgnFltPrsnt;
